VERSION ""

NS_ :

BS_:

BU_: R_BPCU_MCU JiaShiCang L_BPCU_MCU EMPC_ECU

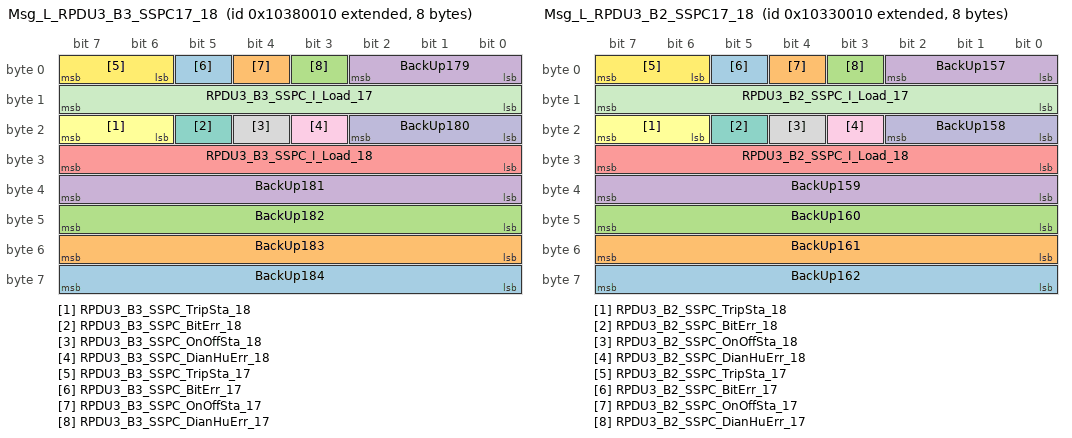
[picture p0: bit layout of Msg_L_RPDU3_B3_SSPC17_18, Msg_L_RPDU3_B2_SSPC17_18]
BO_ 2419589136 Msg_L_RPDU3_B3_SSPC17_18: 8 L_BPCU_MCU
 SG_ BackUp184 : 56|8@1+ (1,0) [0|0] ""  JiaShiCang
 SG_ BackUp183 : 48|8@1+ (1,0) [0|0] ""  JiaShiCang
 SG_ BackUp182 : 40|8@1+ (1,0) [0|0] ""  JiaShiCang
 SG_ BackUp181 : 32|8@1+ (1,0) [0|0] ""  JiaShiCang
 SG_ RPDU3_B3_SSPC_I_Load_18 : 24|8@1+ (0.1,0) [0|25.5] "A"  JiaShiCang
 SG_ RPDU3_B3_SSPC_TripSta_18 : 22|2@1+ (1,0) [0|3] ""  JiaShiCang
 SG_ RPDU3_B3_SSPC_BitErr_18 : 21|1@1+ (1,0) [0|1] ""  JiaShiCang
 SG_ RPDU3_B3_SSPC_OnOffSta_18 : 20|1@1+ (1,0) [0|1] ""  JiaShiCang
 SG_ RPDU3_B3_SSPC_DianHuErr_18 : 19|1@1+ (1,0) [0|1] ""  JiaShiCang
 SG_ BackUp180 : 16|3@1+ (1,0) [0|0] ""  JiaShiCang
 SG_ RPDU3_B3_SSPC_I_Load_17 : 8|8@1+ (0.1,0) [0|25.5] "A"  JiaShiCang
 SG_ RPDU3_B3_SSPC_TripSta_17 : 6|2@1+ (1,0) [0|3] ""  JiaShiCang
 SG_ RPDU3_B3_SSPC_BitErr_17 : 5|1@1+ (1,0) [0|1] ""  JiaShiCang
 SG_ RPDU3_B3_SSPC_OnOffSta_17 : 4|1@1+ (1,0) [0|1] ""  JiaShiCang
 SG_ RPDU3_B3_SSPC_DianHuErr_17 : 3|1@1+ (1,0) [0|1] ""  JiaShiCang
 SG_ BackUp179 : 0|3@1+ (1,0) [0|0] ""  JiaShiCang

BO_ 2419523600 Msg_L_RPDU3_B3_SSPC13_16: 8 L_BPCU_MCU
 SG_ RPDU3_B3_SSPC_I_Load_16 : 56|8@1+ (0.1,0) [0|25.5] "A"  JiaShiCang
 SG_ RPDU3_B3_SSPC_TripSta_16 : 54|2@1+ (1,0) [0|3] ""  JiaShiCang
 SG_ RPDU3_B3_SSPC_BitErr_16 : 53|1@1+ (1,0) [0|1] ""  JiaShiCang
 SG_ RPDU3_B3_SSPC_OnOffSta_16 : 52|1@1+ (1,0) [0|1] ""  JiaShiCang
 SG_ RPDU3_B3_SSPC_DianHuErr_16 : 51|1@1+ (1,0) [0|1] ""  JiaShiCang
 SG_ BackUp178 : 48|3@1+ (1,0) [0|0] ""  JiaShiCang
 SG_ RPDU3_B3_SSPC_I_Load_15 : 40|8@1+ (0.1,0) [0|25.5] "A"  JiaShiCang
 SG_ RPDU3_B3_SSPC_TripSta_15 : 38|2@1+ (1,0) [0|3] ""  JiaShiCang
 SG_ RPDU3_B3_SSPC_BitErr_15 : 37|1@1+ (1,0) [0|1] ""  JiaShiCang
 SG_ RPDU3_B3_SSPC_OnOffSta_15 : 36|1@1+ (1,0) [0|1] ""  JiaShiCang
 SG_ RPDU3_B3_SSPC_DianHuErr_15 : 35|1@1+ (1,0) [0|1] ""  JiaShiCang
 SG_ BackUp177 : 32|3@1+ (1,0) [0|0] ""  JiaShiCang
 SG_ RPDU3_B3_SSPC_I_Load_14 : 24|8@1+ (0.1,0) [0|25.5] "A"  JiaShiCang
 SG_ RPDU3_B3_SSPC_TripSta_14 : 22|2@1+ (1,0) [0|3] ""  JiaShiCang
 SG_ RPDU3_B3_SSPC_BitErr_14 : 21|1@1+ (1,0) [0|1] ""  JiaShiCang
 SG_ RPDU3_B3_SSPC_OnOffSta_14 : 20|1@1+ (1,0) [0|1] ""  JiaShiCang
 SG_ RPDU3_B3_SSPC_DianHuErr_14 : 19|1@1+ (1,0) [0|1] ""  JiaShiCang
 SG_ BackUp176 : 16|3@1+ (1,0) [0|0] ""  JiaShiCang
 SG_ RPDU3_B3_SSPC_I_Load_13 : 8|8@1+ (0.1,0) [0|25.5] "A"  JiaShiCang
 SG_ RPDU3_B3_SSPC_TripSta_13 : 6|2@1+ (1,0) [0|3] ""  JiaShiCang
 SG_ RPDU3_B3_SSPC_BitErr_13 : 5|1@1+ (1,0) [0|1] ""  JiaShiCang
 SG_ RPDU3_B3_SSPC_OnOffSta_13 : 4|1@1+ (1,0) [0|1] ""  JiaShiCang
 SG_ RPDU3_B3_SSPC_DianHuErr_13 : 3|1@1+ (1,0) [0|1] ""  JiaShiCang
 SG_ BackUp175 : 0|3@1+ (1,0) [0|0] ""  JiaShiCang

BO_ 2419458064 Msg_L_RPDU3_B3_SSPC09_12: 8 L_BPCU_MCU
 SG_ RPDU3_B3_SSPC_I_Load_12 : 56|8@1+ (0.1,0) [0|25.5] "A"  JiaShiCang
 SG_ RPDU3_B3_SSPC_TripSta_12 : 54|2@1+ (1,0) [0|3] ""  JiaShiCang
 SG_ RPDU3_B3_SSPC_BitErr_12 : 53|1@1+ (1,0) [0|1] ""  JiaShiCang
 SG_ RPDU3_B3_SSPC_OnOffSta_12 : 52|1@1+ (1,0) [0|1] ""  JiaShiCang
 SG_ RPDU3_B3_SSPC_DianHuErr_12 : 51|1@1+ (1,0) [0|1] ""  JiaShiCang
 SG_ BackUp174 : 48|3@1+ (1,0) [0|0] ""  JiaShiCang
 SG_ RPDU3_B3_SSPC_I_Load_11 : 40|8@1+ (0.1,0) [0|25.5] "A"  JiaShiCang
 SG_ RPDU3_B3_SSPC_TripSta_11 : 38|2@1+ (1,0) [0|3] ""  JiaShiCang
 SG_ RPDU3_B3_SSPC_BitErr_11 : 37|1@1+ (1,0) [0|1] ""  JiaShiCang
 SG_ RPDU3_B3_SSPC_OnOffSta_11 : 36|1@1+ (1,0) [0|1] ""  JiaShiCang
 SG_ RPDU3_B3_SSPC_DianHuErr_11 : 35|1@1+ (1,0) [0|1] ""  JiaShiCang
 SG_ BackUp173 : 32|3@1+ (1,0) [0|0] ""  JiaShiCang
 SG_ RPDU3_B3_SSPC_I_Load_10 : 24|8@1+ (0.1,0) [0|25.5] "A"  JiaShiCang
 SG_ RPDU3_B3_SSPC_TripSta_10 : 22|2@1+ (1,0) [0|3] ""  JiaShiCang
 SG_ RPDU3_B3_SSPC_BitErr_10 : 21|1@1+ (1,0) [0|1] ""  JiaShiCang
 SG_ RPDU3_B3_SSPC_OnOffSta_10 : 20|1@1+ (1,0) [0|1] ""  JiaShiCang
 SG_ RPDU3_B3_SSPC_DianHuErr_10 : 19|1@1+ (1,0) [0|1] ""  JiaShiCang
 SG_ BackUp172 : 16|3@1+ (1,0) [0|0] ""  JiaShiCang
 SG_ RPDU3_B3_SSPC_I_Load_09 : 8|8@1+ (0.1,0) [0|25.5] "A"  JiaShiCang
 SG_ RPDU3_B3_SSPC_TripSta_09 : 6|2@1+ (1,0) [0|3] ""  JiaShiCang
 SG_ RPDU3_B3_SSPC_BitErr_09 : 5|1@1+ (1,0) [0|1] ""  JiaShiCang
 SG_ RPDU3_B3_SSPC_OnOffSta_09 : 4|1@1+ (1,0) [0|1] ""  JiaShiCang
 SG_ RPDU3_B3_SSPC_DianHuErr_09 : 3|1@1+ (1,0) [0|1] ""  JiaShiCang
 SG_ BackUp171 : 0|3@1+ (1,0) [0|0] ""  JiaShiCang

BO_ 2419392528 Msg_L_RPDU3_B3_SSPC05_08: 8 L_BPCU_MCU
 SG_ RPDU3_B3_SSPC_I_Load_08 : 56|8@1+ (0.1,0) [0|25.5] "A"  JiaShiCang
 SG_ RPDU3_B3_SSPC_TripSta_08 : 54|2@1+ (1,0) [0|3] ""  JiaShiCang
 SG_ RPDU3_B3_SSPC_BitErr_08 : 53|1@1+ (1,0) [0|1] ""  JiaShiCang
 SG_ RPDU3_B3_SSPC_OnOffSta_08 : 52|1@1+ (1,0) [0|1] ""  JiaShiCang
 SG_ RPDU3_B3_SSPC_DianHuErr_08 : 51|1@1+ (1,0) [0|1] ""  JiaShiCang
 SG_ BackUp170 : 48|3@1+ (1,0) [0|0] ""  JiaShiCang
 SG_ RPDU3_B3_SSPC_I_Load_07 : 40|8@1+ (0.1,0) [0|25.5] "A"  JiaShiCang
 SG_ RPDU3_B3_SSPC_TripSta_07 : 38|2@1+ (1,0) [0|3] ""  JiaShiCang
 SG_ RPDU3_B3_SSPC_BitErr_07 : 37|1@1+ (1,0) [0|1] ""  JiaShiCang
 SG_ RPDU3_B3_SSPC_OnOffSta_07 : 36|1@1+ (1,0) [0|1] ""  JiaShiCang
 SG_ RPDU3_B3_SSPC_DianHuErr_07 : 35|1@1+ (1,0) [0|1] ""  JiaShiCang
 SG_ BackUp169 : 32|3@1+ (1,0) [0|0] ""  JiaShiCang
 SG_ RPDU3_B3_SSPC_I_Load_06 : 24|8@1+ (0.1,0) [0|25.5] "A"  JiaShiCang
 SG_ RPDU3_B3_SSPC_TripSta_06 : 22|2@1+ (1,0) [0|3] ""  JiaShiCang
 SG_ RPDU3_B3_SSPC_BitErr_06 : 21|1@1+ (1,0) [0|1] ""  JiaShiCang
 SG_ RPDU3_B3_SSPC_OnOffSta_06 : 20|1@1+ (1,0) [0|1] ""  JiaShiCang
 SG_ RPDU3_B3_SSPC_DianHuErr_06 : 19|1@1+ (1,0) [0|1] ""  JiaShiCang
 SG_ BackUp168 : 16|3@1+ (1,0) [0|0] ""  JiaShiCang
 SG_ RPDU3_B3_SSPC_I_Load_05 : 8|8@1+ (0.1,0) [0|25.5] "A"  JiaShiCang
 SG_ RPDU3_B3_SSPC_TripSta_05 : 6|2@1+ (1,0) [0|3] ""  JiaShiCang
 SG_ RPDU3_B3_SSPC_BitErr_05 : 5|1@1+ (1,0) [0|1] ""  JiaShiCang
 SG_ RPDU3_B3_SSPC_OnOffSta_05 : 4|1@1+ (1,0) [0|1] ""  JiaShiCang
 SG_ RPDU3_B3_SSPC_DianHuErr_05 : 3|1@1+ (1,0) [0|1] ""  JiaShiCang
 SG_ BackUp167 : 0|3@1+ (1,0) [0|0] ""  JiaShiCang

BO_ 2419326992 Msg_L_RPDU3_B3_SSPC01_04: 8 L_BPCU_MCU
 SG_ RPDU3_B3_SSPC_I_Load_04 : 56|8@1+ (0.1,0) [0|25.5] "A"  JiaShiCang
 SG_ RPDU3_B3_SSPC_TripSta_04 : 54|2@1+ (1,0) [0|3] ""  JiaShiCang
 SG_ RPDU3_B3_SSPC_BitErr_04 : 53|1@1+ (1,0) [0|1] ""  JiaShiCang
 SG_ RPDU3_B3_SSPC_OnOffSta_04 : 52|1@1+ (1,0) [0|1] ""  JiaShiCang
 SG_ RPDU3_B3_SSPC_DianHuErr_04 : 51|1@1+ (1,0) [0|1] ""  JiaShiCang
 SG_ BackUp166 : 48|3@1+ (1,0) [0|0] ""  JiaShiCang
 SG_ RPDU3_B3_SSPC_I_Load_03 : 40|8@1+ (0.1,0) [0|25.5] "A"  JiaShiCang
 SG_ RPDU3_B3_SSPC_TripSta_03 : 38|2@1+ (1,0) [0|3] ""  JiaShiCang
 SG_ RPDU3_B3_SSPC_BitErr_03 : 37|1@1+ (1,0) [0|1] ""  JiaShiCang
 SG_ RPDU3_B3_SSPC_OnOffSta_03 : 36|1@1+ (1,0) [0|1] ""  JiaShiCang
 SG_ RPDU3_B3_SSPC_DianHuErr_03 : 35|1@1+ (1,0) [0|1] ""  JiaShiCang
 SG_ BackUp165 : 32|3@1+ (1,0) [0|0] ""  JiaShiCang
 SG_ RPDU3_B3_SSPC_I_Load_02 : 24|8@1+ (0.1,0) [0|25.5] "A"  JiaShiCang
 SG_ RPDU3_B3_SSPC_TripSta_02 : 22|2@1+ (1,0) [0|3] ""  JiaShiCang
 SG_ RPDU3_B3_SSPC_BitErr_02 : 21|1@1+ (1,0) [0|1] ""  JiaShiCang
 SG_ RPDU3_B3_SSPC_OnOffSta_02 : 20|1@1+ (1,0) [0|1] ""  JiaShiCang
 SG_ RPDU3_B3_SSPC_DianHuErr_02 : 19|1@1+ (1,0) [0|1] ""  JiaShiCang
 SG_ BackUp164 : 16|3@1+ (1,0) [0|0] ""  JiaShiCang
 SG_ RPDU3_B3_SSPC_I_Load_01 : 8|8@1+ (0.1,0) [0|25.5] "A"  JiaShiCang
 SG_ RPDU3_B3_SSPC_TripSta_01 : 6|2@1+ (1,0) [0|3] ""  JiaShiCang
 SG_ RPDU3_B3_SSPC_BitErr_01 : 5|1@1+ (1,0) [0|1] ""  JiaShiCang
 SG_ RPDU3_B3_SSPC_OnOffSta_01 : 4|1@1+ (1,0) [0|1] ""  JiaShiCang
 SG_ RPDU3_B3_SSPC_DianHuErr_01 : 3|1@1+ (1,0) [0|1] ""  JiaShiCang
 SG_ BackUp163 : 0|3@1+ (1,0) [0|0] ""  JiaShiCang

BO_ 2419261456 Msg_L_RPDU3_B2_SSPC17_18: 8 L_BPCU_MCU
 SG_ BackUp162 : 56|8@1+ (1,0) [0|0] ""  JiaShiCang
 SG_ BackUp161 : 48|8@1+ (1,0) [0|0] ""  JiaShiCang
 SG_ BackUp160 : 40|8@1+ (1,0) [0|0] ""  JiaShiCang
 SG_ BackUp159 : 32|8@1+ (1,0) [0|0] ""  JiaShiCang
 SG_ RPDU3_B2_SSPC_I_Load_18 : 24|8@1+ (0.1,0) [0|25.5] "A"  JiaShiCang
 SG_ RPDU3_B2_SSPC_TripSta_18 : 22|2@1+ (1,0) [0|3] ""  JiaShiCang
 SG_ RPDU3_B2_SSPC_BitErr_18 : 21|1@1+ (1,0) [0|1] ""  JiaShiCang
 SG_ RPDU3_B2_SSPC_OnOffSta_18 : 20|1@1+ (1,0) [0|1] ""  JiaShiCang
 SG_ RPDU3_B2_SSPC_DianHuErr_18 : 19|1@1+ (1,0) [0|1] ""  JiaShiCang
 SG_ BackUp158 : 16|3@1+ (1,0) [0|0] ""  JiaShiCang
 SG_ RPDU3_B2_SSPC_I_Load_17 : 8|8@1+ (0.1,0) [0|25.5] "A"  JiaShiCang
 SG_ RPDU3_B2_SSPC_TripSta_17 : 6|2@1+ (1,0) [0|3] ""  JiaShiCang
 SG_ RPDU3_B2_SSPC_BitErr_17 : 5|1@1+ (1,0) [0|1] ""  JiaShiCang
 SG_ RPDU3_B2_SSPC_OnOffSta_17 : 4|1@1+ (1,0) [0|1] ""  JiaShiCang
 SG_ RPDU3_B2_SSPC_DianHuErr_17 : 3|1@1+ (1,0) [0|1] ""  JiaShiCang
 SG_ BackUp157 : 0|3@1+ (1,0) [0|0] ""  JiaShiCang

BO_ 2419195920 Msg_L_RPDU3_B2_SSPC13_16: 8 L_BPCU_MCU
 SG_ RPDU3_B2_SSPC_I_Load_16 : 56|8@1+ (0.1,0) [0|25.5] "A"  JiaShiCang
 SG_ RPDU3_B2_SSPC_TripSta_16 : 54|2@1+ (1,0) [0|3] ""  JiaShiCang
 SG_ RPDU3_B2_SSPC_BitErr_16 : 53|1@1+ (1,0) [0|1] ""  JiaShiCang
 SG_ RPDU3_B2_SSPC_OnOffSta_16 : 52|1@1+ (1,0) [0|1] ""  JiaShiCang
 SG_ RPDU3_B2_SSPC_DianHuErr_16 : 51|1@1+ (1,0) [0|1] ""  JiaShiCang
 SG_ BackUp156 : 48|3@1+ (1,0) [0|0] ""  JiaShiCang
 SG_ RPDU3_B2_SSPC_I_Load_15 : 40|8@1+ (0.1,0) [0|25.5] "A"  JiaShiCang
 SG_ RPDU3_B2_SSPC_TripSta_15 : 38|2@1+ (1,0) [0|3] ""  JiaShiCang
 SG_ RPDU3_B2_SSPC_BitErr_15 : 37|1@1+ (1,0) [0|1] ""  JiaShiCang
 SG_ RPDU3_B2_SSPC_OnOffSta_15 : 36|1@1+ (1,0) [0|1] ""  JiaShiCang
 SG_ RPDU3_B2_SSPC_DianHuErr_15 : 35|1@1+ (1,0) [0|1] ""  JiaShiCang
 SG_ BackUp155 : 32|3@1+ (1,0) [0|0] ""  JiaShiCang
 SG_ RPDU3_B2_SSPC_I_Load_14 : 24|8@1+ (0.1,0) [0|25.5] "A"  JiaShiCang
 SG_ RPDU3_B2_SSPC_TripSta_14 : 22|2@1+ (1,0) [0|3] ""  JiaShiCang
 SG_ RPDU3_B2_SSPC_BitErr_14 : 21|1@1+ (1,0) [0|1] ""  JiaShiCang
 SG_ RPDU3_B2_SSPC_OnOffSta_14 : 20|1@1+ (1,0) [0|1] ""  JiaShiCang
 SG_ RPDU3_B2_SSPC_DianHuErr_14 : 19|1@1+ (1,0) [0|1] ""  JiaShiCang
 SG_ BackUp154 : 16|3@1+ (1,0) [0|0] ""  JiaShiCang
 SG_ RPDU3_B2_SSPC_I_Load_13 : 8|8@1+ (0.1,0) [0|25.5] "A"  JiaShiCang
 SG_ RPDU3_B2_SSPC_TripSta_13 : 6|2@1+ (1,0) [0|3] ""  JiaShiCang
 SG_ RPDU3_B2_SSPC_BitErr_13 : 5|1@1+ (1,0) [0|1] ""  JiaShiCang
 SG_ RPDU3_B2_SSPC_OnOffSta_13 : 4|1@1+ (1,0) [0|1] ""  JiaShiCang
 SG_ RPDU3_B2_SSPC_DianHuErr_13 : 3|1@1+ (1,0) [0|1] ""  JiaShiCang
 SG_ BackUp153 : 0|3@1+ (1,0) [0|0] ""  JiaShiCang

BO_ 2419130384 Msg_L_RPDU3_B2_SSPC09_12: 8 L_BPCU_MCU
 SG_ RPDU3_B2_SSPC_I_Load_12 : 56|8@1+ (0.1,0) [0|25.5] "A"  JiaShiCang
 SG_ RPDU3_B2_SSPC_TripSta_12 : 54|2@1+ (1,0) [0|3] ""  JiaShiCang
 SG_ RPDU3_B2_SSPC_BitErr_12 : 53|1@1+ (1,0) [0|1] ""  JiaShiCang
 SG_ RPDU3_B2_SSPC_OnOffSta_12 : 52|1@1+ (1,0) [0|1] ""  JiaShiCang
 SG_ RPDU3_B2_SSPC_DianHuErr_12 : 51|1@1+ (1,0) [0|1] ""  JiaShiCang
 SG_ BackUp152 : 48|3@1+ (1,0) [0|0] ""  JiaShiCang
 SG_ RPDU3_B2_SSPC_I_Load_11 : 40|8@1+ (0.1,0) [0|25.5] "A"  JiaShiCang
 SG_ RPDU3_B2_SSPC_TripSta_11 : 38|2@1+ (1,0) [0|3] ""  JiaShiCang
 SG_ RPDU3_B2_SSPC_BitErr_11 : 37|1@1+ (1,0) [0|1] ""  JiaShiCang
 SG_ RPDU3_B2_SSPC_OnOffSta_11 : 36|1@1+ (1,0) [0|1] ""  JiaShiCang
 SG_ RPDU3_B2_SSPC_DianHuErr_11 : 35|1@1+ (1,0) [0|1] ""  JiaShiCang
 SG_ BackUp151 : 32|3@1+ (1,0) [0|0] ""  JiaShiCang
 SG_ RPDU3_B2_SSPC_I_Load_10 : 24|8@1+ (0.1,0) [0|25.5] "A"  JiaShiCang
 SG_ RPDU3_B2_SSPC_TripSta_10 : 22|2@1+ (1,0) [0|3] ""  JiaShiCang
 SG_ RPDU3_B2_SSPC_BitErr_10 : 21|1@1+ (1,0) [0|1] ""  JiaShiCang
 SG_ RPDU3_B2_SSPC_OnOffSta_10 : 20|1@1+ (1,0) [0|1] ""  JiaShiCang
 SG_ RPDU3_B2_SSPC_DianHuErr_10 : 19|1@1+ (1,0) [0|1] ""  JiaShiCang
 SG_ BackUp150 : 16|3@1+ (1,0) [0|0] ""  JiaShiCang
 SG_ RPDU3_B2_SSPC_I_Load_09 : 8|8@1+ (0.1,0) [0|25.5] "A"  JiaShiCang
 SG_ RPDU3_B2_SSPC_TripSta_09 : 6|2@1+ (1,0) [0|3] ""  JiaShiCang
 SG_ RPDU3_B2_SSPC_BitErr_09 : 5|1@1+ (1,0) [0|1] ""  JiaShiCang
 SG_ RPDU3_B2_SSPC_OnOffSta_09 : 4|1@1+ (1,0) [0|1] ""  JiaShiCang
 SG_ RPDU3_B2_SSPC_DianHuErr_09 : 3|1@1+ (1,0) [0|1] ""  JiaShiCang
 SG_ BackUp149 : 0|3@1+ (1,0) [0|0] ""  JiaShiCang

BO_ 2419064848 Msg_L_RPDU3_B2_SSPC05_08: 8 L_BPCU_MCU
 SG_ RPDU3_B2_SSPC_I_Load_08 : 56|8@1+ (0.1,0) [0|25.5] "A"  JiaShiCang
 SG_ RPDU3_B2_SSPC_TripSta_08 : 54|2@1+ (1,0) [0|3] ""  JiaShiCang
 SG_ RPDU3_B2_SSPC_BitErr_08 : 53|1@1+ (1,0) [0|1] ""  JiaShiCang
 SG_ RPDU3_B2_SSPC_OnOffSta_08 : 52|1@1+ (1,0) [0|1] ""  JiaShiCang
 SG_ RPDU3_B2_SSPC_DianHuErr_08 : 51|1@1+ (1,0) [0|1] ""  JiaShiCang
 SG_ BackUp148 : 48|3@1+ (1,0) [0|0] ""  JiaShiCang
 SG_ RPDU3_B2_SSPC_I_Load_07 : 40|8@1+ (0.1,0) [0|25.5] "A"  JiaShiCang
 SG_ RPDU3_B2_SSPC_TripSta_07 : 38|2@1+ (1,0) [0|3] ""  JiaShiCang
 SG_ RPDU3_B2_SSPC_BitErr_07 : 37|1@1+ (1,0) [0|1] ""  JiaShiCang
 SG_ RPDU3_B2_SSPC_OnOffSta_07 : 36|1@1+ (1,0) [0|1] ""  JiaShiCang
 SG_ RPDU3_B2_SSPC_DianHuErr_07 : 35|1@1+ (1,0) [0|1] ""  JiaShiCang
 SG_ BackUp147 : 32|3@1+ (1,0) [0|0] ""  JiaShiCang
 SG_ RPDU3_B2_SSPC_I_Load_06 : 24|8@1+ (0.1,0) [0|25.5] "A"  JiaShiCang
 SG_ RPDU3_B2_SSPC_TripSta_06 : 22|2@1+ (1,0) [0|3] ""  JiaShiCang
 SG_ RPDU3_B2_SSPC_BitErr_06 : 21|1@1+ (1,0) [0|1] ""  JiaShiCang
 SG_ RPDU3_B2_SSPC_OnOffSta_06 : 20|1@1+ (1,0) [0|1] ""  JiaShiCang
 SG_ RPDU3_B2_SSPC_DianHuErr_06 : 19|1@1+ (1,0) [0|1] ""  JiaShiCang
 SG_ BackUp146 : 16|3@1+ (1,0) [0|0] ""  JiaShiCang
 SG_ RPDU3_B2_SSPC_I_Load_05 : 8|8@1+ (0.1,0) [0|25.5] "A"  JiaShiCang
 SG_ RPDU3_B2_SSPC_TripSta_05 : 6|2@1+ (1,0) [0|3] ""  JiaShiCang
 SG_ RPDU3_B2_SSPC_BitErr_05 : 5|1@1+ (1,0) [0|1] ""  JiaShiCang
 SG_ RPDU3_B2_SSPC_OnOffSta_05 : 4|1@1+ (1,0) [0|1] ""  JiaShiCang
 SG_ RPDU3_B2_SSPC_DianHuErr_05 : 3|1@1+ (1,0) [0|1] ""  JiaShiCang
 SG_ BackUp145 : 0|3@1+ (1,0) [0|0] ""  JiaShiCang

BO_ 2418999312 Msg_L_RPDU3_B2_SSPC01_04: 8 L_BPCU_MCU
 SG_ RPDU3_B2_SSPC_I_Load_04 : 56|8@1+ (0.1,0) [0|25.5] "A"  JiaShiCang
 SG_ RPDU3_B2_SSPC_TripSta_04 : 54|2@1+ (1,0) [0|3] ""  JiaShiCang
 SG_ RPDU3_B2_SSPC_BitErr_04 : 53|1@1+ (1,0) [0|1] ""  JiaShiCang
 SG_ RPDU3_B2_SSPC_OnOffSta_04 : 52|1@1+ (1,0) [0|1] ""  JiaShiCang
 SG_ RPDU3_B2_SSPC_DianHuErr_04 : 51|1@1+ (1,0) [0|1] ""  JiaShiCang
 SG_ BackUp144 : 48|3@1+ (1,0) [0|0] ""  JiaShiCang
 SG_ RPDU3_B2_SSPC_I_Load_03 : 40|8@1+ (0.1,0) [0|25.5] "A"  JiaShiCang
 SG_ RPDU3_B2_SSPC_TripSta_03 : 38|2@1+ (1,0) [0|3] ""  JiaShiCang
 SG_ RPDU3_B2_SSPC_BitErr_03 : 37|1@1+ (1,0) [0|1] ""  JiaShiCang
 SG_ RPDU3_B2_SSPC_OnOffSta_03 : 36|1@1+ (1,0) [0|1] ""  JiaShiCang
 SG_ RPDU3_B2_SSPC_DianHuErr_03 : 35|1@1+ (1,0) [0|1] ""  JiaShiCang
 SG_ BackUp143 : 32|3@1+ (1,0) [0|0] ""  JiaShiCang
 SG_ RPDU3_B2_SSPC_I_Load_02 : 24|8@1+ (0.1,0) [0|25.5] "A"  JiaShiCang
 SG_ RPDU3_B2_SSPC_TripSta_02 : 22|2@1+ (1,0) [0|3] ""  JiaShiCang
 SG_ RPDU3_B2_SSPC_BitErr_02 : 21|1@1+ (1,0) [0|1] ""  JiaShiCang
 SG_ RPDU3_B2_SSPC_OnOffSta_02 : 20|1@1+ (1,0) [0|1] ""  JiaShiCang
 SG_ RPDU3_B2_SSPC_DianHuErr_02 : 19|1@1+ (1,0) [0|1] ""  JiaShiCang
 SG_ BackUp142 : 16|3@1+ (1,0) [0|0] ""  JiaShiCang
 SG_ RPDU3_B2_SSPC_I_Load_01 : 8|8@1+ (0.1,0) [0|25.5] "A"  JiaShiCang
 SG_ RPDU3_B2_SSPC_TripSta_01 : 6|2@1+ (1,0) [0|3] ""  JiaShiCang
 SG_ RPDU3_B2_SSPC_BitErr_01 : 5|1@1+ (1,0) [0|1] ""  JiaShiCang
 SG_ RPDU3_B2_SSPC_OnOffSta_01 : 4|1@1+ (1,0) [0|1] ""  JiaShiCang
 SG_ RPDU3_B2_SSPC_DianHuErr_01 : 3|1@1+ (1,0) [0|1] ""  JiaShiCang
 SG_ BackUp141 : 0|3@1+ (1,0) [0|0] ""  JiaShiCang

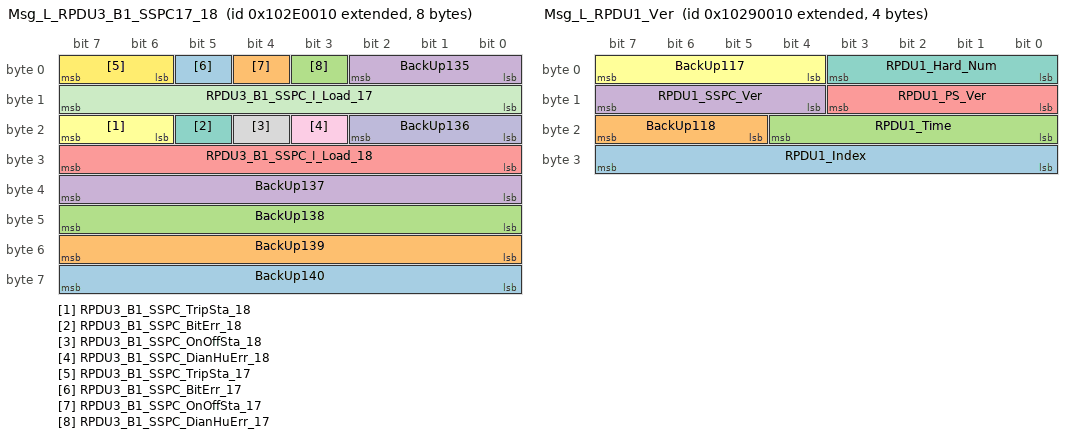
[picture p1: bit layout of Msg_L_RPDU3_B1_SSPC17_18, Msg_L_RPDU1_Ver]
BO_ 2418933776 Msg_L_RPDU3_B1_SSPC17_18: 8 L_BPCU_MCU
 SG_ BackUp140 : 56|8@1+ (1,0) [0|0] ""  JiaShiCang
 SG_ BackUp139 : 48|8@1+ (1,0) [0|0] ""  JiaShiCang
 SG_ BackUp138 : 40|8@1+ (1,0) [0|0] ""  JiaShiCang
 SG_ BackUp137 : 32|8@1+ (1,0) [0|0] ""  JiaShiCang
 SG_ RPDU3_B1_SSPC_I_Load_18 : 24|8@1+ (0.1,0) [0|25.5] "A"  JiaShiCang
 SG_ RPDU3_B1_SSPC_TripSta_18 : 22|2@1+ (1,0) [0|3] ""  JiaShiCang
 SG_ RPDU3_B1_SSPC_BitErr_18 : 21|1@1+ (1,0) [0|1] ""  JiaShiCang
 SG_ RPDU3_B1_SSPC_OnOffSta_18 : 20|1@1+ (1,0) [0|1] ""  JiaShiCang
 SG_ RPDU3_B1_SSPC_DianHuErr_18 : 19|1@1+ (1,0) [0|1] ""  JiaShiCang
 SG_ BackUp136 : 16|3@1+ (1,0) [0|0] ""  JiaShiCang
 SG_ RPDU3_B1_SSPC_I_Load_17 : 8|8@1+ (0.1,0) [0|25.5] "A"  JiaShiCang
 SG_ RPDU3_B1_SSPC_TripSta_17 : 6|2@1+ (1,0) [0|3] ""  JiaShiCang
 SG_ RPDU3_B1_SSPC_BitErr_17 : 5|1@1+ (1,0) [0|1] ""  JiaShiCang
 SG_ RPDU3_B1_SSPC_OnOffSta_17 : 4|1@1+ (1,0) [0|1] ""  JiaShiCang
 SG_ RPDU3_B1_SSPC_DianHuErr_17 : 3|1@1+ (1,0) [0|1] ""  JiaShiCang
 SG_ BackUp135 : 0|3@1+ (1,0) [0|0] ""  JiaShiCang

BO_ 2418868240 Msg_L_RPDU3_B1_SSPC13_16: 8 L_BPCU_MCU
 SG_ RPDU3_B1_SSPC_I_Load_16 : 56|8@1+ (0.1,0) [0|25.5] "A"  JiaShiCang
 SG_ RPDU3_B1_SSPC_TripSta_16 : 54|2@1+ (1,0) [0|3] ""  JiaShiCang
 SG_ RPDU3_B1_SSPC_BitErr_16 : 53|1@1+ (1,0) [0|1] ""  JiaShiCang
 SG_ RPDU3_B1_SSPC_OnOffSta_16 : 52|1@1+ (1,0) [0|1] ""  JiaShiCang
 SG_ RPDU3_B1_SSPC_DianHuErr_16 : 51|1@1+ (1,0) [0|1] ""  JiaShiCang
 SG_ BackUp134 : 48|3@1+ (1,0) [0|0] ""  JiaShiCang
 SG_ RPDU3_B1_SSPC_I_Load_15 : 40|8@1+ (0.1,0) [0|25.5] "A"  JiaShiCang
 SG_ RPDU3_B1_SSPC_TripSta_15 : 38|2@1+ (1,0) [0|3] ""  JiaShiCang
 SG_ RPDU3_B1_SSPC_BitErr_15 : 37|1@1+ (1,0) [0|1] ""  JiaShiCang
 SG_ RPDU3_B1_SSPC_OnOffSta_15 : 36|1@1+ (1,0) [0|1] ""  JiaShiCang
 SG_ RPDU3_B1_SSPC_DianHuErr_15 : 35|1@1+ (1,0) [0|1] ""  JiaShiCang
 SG_ BackUp133 : 32|3@1+ (1,0) [0|0] ""  JiaShiCang
 SG_ RPDU3_B1_SSPC_I_Load_14 : 24|8@1+ (0.1,0) [0|25.5] "A"  JiaShiCang
 SG_ RPDU3_B1_SSPC_TripSta_14 : 22|2@1+ (1,0) [0|3] ""  JiaShiCang
 SG_ RPDU3_B1_SSPC_BitErr_14 : 21|1@1+ (1,0) [0|1] ""  JiaShiCang
 SG_ RPDU3_B1_SSPC_OnOffSta_14 : 20|1@1+ (1,0) [0|1] ""  JiaShiCang
 SG_ RPDU3_B1_SSPC_DianHuErr_14 : 19|1@1+ (1,0) [0|1] ""  JiaShiCang
 SG_ BackUp132 : 16|3@1+ (1,0) [0|0] ""  JiaShiCang
 SG_ RPDU3_B1_SSPC_I_Load_13 : 8|8@1+ (0.1,0) [0|25.5] "A"  JiaShiCang
 SG_ RPDU3_B1_SSPC_TripSta_13 : 6|2@1+ (1,0) [0|3] ""  JiaShiCang
 SG_ RPDU3_B1_SSPC_BitErr_13 : 5|1@1+ (1,0) [0|1] ""  JiaShiCang
 SG_ RPDU3_B1_SSPC_OnOffSta_13 : 4|1@1+ (1,0) [0|1] ""  JiaShiCang
 SG_ RPDU3_B1_SSPC_DianHuErr_13 : 3|1@1+ (1,0) [0|1] ""  JiaShiCang
 SG_ BackUp131 : 0|3@1+ (1,0) [0|0] ""  JiaShiCang

BO_ 2418802704 Msg_L_RPDU3_B1_SSPC09_12: 8 L_BPCU_MCU
 SG_ RPDU3_B1_SSPC_I_Load_12 : 56|8@1+ (0.1,0) [0|25.5] "A"  JiaShiCang
 SG_ RPDU3_B1_SSPC_TripSta_12 : 54|2@1+ (1,0) [0|3] ""  JiaShiCang
 SG_ RPDU3_B1_SSPC_BitErr_12 : 53|1@1+ (1,0) [0|1] ""  JiaShiCang
 SG_ RPDU3_B1_SSPC_OnOffSta_12 : 52|1@1+ (1,0) [0|1] ""  JiaShiCang
 SG_ RPDU3_B1_SSPC_DianHuErr_12 : 51|1@1+ (1,0) [0|1] ""  JiaShiCang
 SG_ BackUp130 : 48|3@1+ (1,0) [0|0] ""  JiaShiCang
 SG_ RPDU3_B1_SSPC_I_Load_11 : 40|8@1+ (0.1,0) [0|25.5] "A"  JiaShiCang
 SG_ RPDU3_B1_SSPC_TripSta_11 : 38|2@1+ (1,0) [0|3] ""  JiaShiCang
 SG_ RPDU3_B1_SSPC_BitErr_11 : 37|1@1+ (1,0) [0|1] ""  JiaShiCang
 SG_ RPDU3_B1_SSPC_OnOffSta_11 : 36|1@1+ (1,0) [0|1] ""  JiaShiCang
 SG_ RPDU3_B1_SSPC_DianHuErr_11 : 35|1@1+ (1,0) [0|1] ""  JiaShiCang
 SG_ BackUp129 : 32|3@1+ (1,0) [0|0] ""  JiaShiCang
 SG_ RPDU3_B1_SSPC_I_Load_10 : 24|8@1+ (0.1,0) [0|25.5] "A"  JiaShiCang
 SG_ RPDU3_B1_SSPC_TripSta_10 : 22|2@1+ (1,0) [0|3] ""  JiaShiCang
 SG_ RPDU3_B1_SSPC_BitErr_10 : 21|1@1+ (1,0) [0|1] ""  JiaShiCang
 SG_ RPDU3_B1_SSPC_OnOffSta_10 : 20|1@1+ (1,0) [0|1] ""  JiaShiCang
 SG_ RPDU3_B1_SSPC_DianHuErr_10 : 19|1@1+ (1,0) [0|1] ""  JiaShiCang
 SG_ BackUp128 : 16|3@1+ (1,0) [0|0] ""  JiaShiCang
 SG_ RPDU3_B1_SSPC_I_Load_09 : 8|8@1+ (0.1,0) [0|25.5] "A"  JiaShiCang
 SG_ RPDU3_B1_SSPC_TripSta_09 : 6|2@1+ (1,0) [0|3] ""  JiaShiCang
 SG_ RPDU3_B1_SSPC_BitErr_09 : 5|1@1+ (1,0) [0|1] ""  JiaShiCang
 SG_ RPDU3_B1_SSPC_OnOffSta_09 : 4|1@1+ (1,0) [0|1] ""  JiaShiCang
 SG_ RPDU3_B1_SSPC_DianHuErr_09 : 3|1@1+ (1,0) [0|1] ""  JiaShiCang
 SG_ BackUp127 : 0|3@1+ (1,0) [0|0] ""  JiaShiCang

BO_ 2418737168 Msg_L_RPDU3_B1_SSPC05_08: 8 L_BPCU_MCU
 SG_ RPDU3_B1_SSPC_I_Load_08 : 56|8@1+ (0.1,0) [0|25.5] "A"  JiaShiCang
 SG_ RPDU3_B1_SSPC_TripSta_08 : 54|2@1+ (1,0) [0|3] ""  JiaShiCang
 SG_ RPDU3_B1_SSPC_BitErr_08 : 53|1@1+ (1,0) [0|1] ""  JiaShiCang
 SG_ RPDU3_B1_SSPC_OnOffSta_08 : 52|1@1+ (1,0) [0|1] ""  JiaShiCang
 SG_ RPDU3_B1_SSPC_DianHuErr_08 : 51|1@1+ (1,0) [0|1] ""  JiaShiCang
 SG_ BackUp126 : 48|3@1+ (1,0) [0|0] ""  JiaShiCang
 SG_ RPDU3_B1_SSPC_I_Load_07 : 40|8@1+ (0.1,0) [0|25.5] "A"  JiaShiCang
 SG_ RPDU3_B1_SSPC_TripSta_07 : 38|2@1+ (1,0) [0|3] ""  JiaShiCang
 SG_ RPDU3_B1_SSPC_BitErr_07 : 37|1@1+ (1,0) [0|1] ""  JiaShiCang
 SG_ RPDU3_B1_SSPC_OnOffSta_07 : 36|1@1+ (1,0) [0|1] ""  JiaShiCang
 SG_ RPDU3_B1_SSPC_DianHuErr_07 : 35|1@1+ (1,0) [0|1] ""  JiaShiCang
 SG_ BackUp125 : 32|3@1+ (1,0) [0|0] ""  JiaShiCang
 SG_ RPDU3_B1_SSPC_I_Load_06 : 24|8@1+ (0.1,0) [0|25.5] "A"  JiaShiCang
 SG_ RPDU3_B1_SSPC_TripSta_06 : 22|2@1+ (1,0) [0|3] ""  JiaShiCang
 SG_ RPDU3_B1_SSPC_BitErr_06 : 21|1@1+ (1,0) [0|1] ""  JiaShiCang
 SG_ RPDU3_B1_SSPC_OnOffSta_06 : 20|1@1+ (1,0) [0|1] ""  JiaShiCang
 SG_ RPDU3_B1_SSPC_DianHuErr_06 : 19|1@1+ (1,0) [0|1] ""  JiaShiCang
 SG_ BackUp124 : 16|3@1+ (1,0) [0|0] ""  JiaShiCang
 SG_ RPDU3_B1_SSPC_I_Load_05 : 8|8@1+ (0.1,0) [0|25.5] "A"  JiaShiCang
 SG_ RPDU3_B1_SSPC_TripSta_05 : 6|2@1+ (1,0) [0|3] ""  JiaShiCang
 SG_ RPDU3_B1_SSPC_BitErr_05 : 5|1@1+ (1,0) [0|1] ""  JiaShiCang
 SG_ RPDU3_B1_SSPC_OnOffSta_05 : 4|1@1+ (1,0) [0|1] ""  JiaShiCang
 SG_ RPDU3_B1_SSPC_DianHuErr_05 : 3|1@1+ (1,0) [0|1] ""  JiaShiCang
 SG_ BackUp123 : 0|3@1+ (1,0) [0|0] ""  JiaShiCang

BO_ 2418671632 Msg_L_RPDU3_B1_SSPC01_04: 8 L_BPCU_MCU
 SG_ RPDU3_B1_SSPC_I_Load_04 : 56|8@1+ (0.1,0) [0|25.5] "A"  JiaShiCang
 SG_ RPDU3_B1_SSPC_TripSta_04 : 54|2@1+ (1,0) [0|3] ""  JiaShiCang
 SG_ RPDU3_B1_SSPC_BitErr_04 : 53|1@1+ (1,0) [0|1] ""  JiaShiCang
 SG_ RPDU3_B1_SSPC_OnOffSta_04 : 52|1@1+ (1,0) [0|1] ""  JiaShiCang
 SG_ RPDU3_B1_SSPC_DianHuErr_04 : 51|1@1+ (1,0) [0|1] ""  JiaShiCang
 SG_ BackUp122 : 48|3@1+ (1,0) [0|0] ""  JiaShiCang
 SG_ RPDU3_B1_SSPC_I_Load_03 : 40|8@1+ (0.1,0) [0|25.5] "A"  JiaShiCang
 SG_ RPDU3_B1_SSPC_TripSta_03 : 38|2@1+ (1,0) [0|3] ""  JiaShiCang
 SG_ RPDU3_B1_SSPC_BitErr_03 : 37|1@1+ (1,0) [0|1] ""  JiaShiCang
 SG_ RPDU3_B1_SSPC_OnOffSta_03 : 36|1@1+ (1,0) [0|1] ""  JiaShiCang
 SG_ RPDU3_B1_SSPC_DianHuErr_03 : 35|1@1+ (1,0) [0|1] ""  JiaShiCang
 SG_ BackUp121 : 32|3@1+ (1,0) [0|0] ""  JiaShiCang
 SG_ RPDU3_B1_SSPC_I_Load_02 : 24|8@1+ (0.1,0) [0|25.5] "A"  JiaShiCang
 SG_ RPDU3_B1_SSPC_TripSta_02 : 22|2@1+ (1,0) [0|3] ""  JiaShiCang
 SG_ RPDU3_B1_SSPC_BitErr_02 : 21|1@1+ (1,0) [0|1] ""  JiaShiCang
 SG_ RPDU3_B1_SSPC_OnOffSta_02 : 20|1@1+ (1,0) [0|1] ""  JiaShiCang
 SG_ RPDU3_B1_SSPC_DianHuErr_02 : 19|1@1+ (1,0) [0|1] ""  JiaShiCang
 SG_ BackUp120 : 16|3@1+ (1,0) [0|0] ""  JiaShiCang
 SG_ RPDU3_B1_SSPC_I_Load_01 : 8|8@1+ (0.1,0) [0|25.5] "A"  JiaShiCang
 SG_ RPDU3_B1_SSPC_TripSta_01 : 6|2@1+ (1,0) [0|3] ""  JiaShiCang
 SG_ RPDU3_B1_SSPC_BitErr_01 : 5|1@1+ (1,0) [0|1] ""  JiaShiCang
 SG_ RPDU3_B1_SSPC_OnOffSta_01 : 4|1@1+ (1,0) [0|1] ""  JiaShiCang
 SG_ RPDU3_B1_SSPC_DianHuErr_01 : 3|1@1+ (1,0) [0|1] ""  JiaShiCang
 SG_ BackUp119 : 0|3@1+ (1,0) [0|0] ""  JiaShiCang

BO_ 2418606096 Msg_L_RPDU1_Ver: 4 L_BPCU_MCU
 SG_ RPDU1_Index : 24|8@1+ (1,0) [0|255] ""  JiaShiCang
 SG_ BackUp118 : 21|3@1+ (1,0) [0|0] ""  JiaShiCang
 SG_ RPDU1_Time : 16|5@1+ (1,0) [0|31] ""  JiaShiCang
 SG_ RPDU1_SSPC_Ver : 12|4@1+ (1,0) [0|15] ""  JiaShiCang
 SG_ RPDU1_PS_Ver : 8|4@1+ (1,0) [0|15] ""  JiaShiCang
 SG_ BackUp117 : 4|4@1+ (1,0) [0|0] ""  JiaShiCang
 SG_ RPDU1_Hard_Num : 0|4@1+ (1,0) [0|15] ""  JiaShiCang

BO_ 2418540560 Msg_L_RPDU1_B6_SSPC05_07: 8 L_BPCU_MCU
 SG_ BackUp116 : 56|8@1+ (1,0) [0|0] ""  JiaShiCang
 SG_ BackUp115 : 48|8@1+ (1,0) [0|0] ""  JiaShiCang
 SG_ RPDU1_B6_SSPC_I_Load_07 : 40|8@1+ (0.1,0) [0|25.5] "A"  JiaShiCang
 SG_ RPDU1_B6_SSPC_TripSta_07 : 38|2@1+ (1,0) [0|3] ""  JiaShiCang
 SG_ RPDU1_B6_SSPC_BitErr_07 : 37|1@1+ (1,0) [0|1] ""  JiaShiCang
 SG_ RPDU1_B6_SSPC_OnOffSta_07 : 36|1@1+ (1,0) [0|1] ""  JiaShiCang
 SG_ RPDU1_B6_SSPC_DianHuErr_07 : 35|1@1+ (1,0) [0|1] ""  JiaShiCang
 SG_ BackUp114 : 32|3@1+ (1,0) [0|0] ""  JiaShiCang
 SG_ RPDU1_B6_SSPC_I_Load_06 : 24|8@1+ (0.1,0) [0|25.5] "A"  JiaShiCang
 SG_ RPDU1_B6_SSPC_TripSta_06 : 22|2@1+ (1,0) [0|3] ""  JiaShiCang
 SG_ RPDU1_B6_SSPC_BitErr_06 : 21|1@1+ (1,0) [0|1] ""  JiaShiCang
 SG_ RPDU1_B6_SSPC_OnOffSta_06 : 20|1@1+ (1,0) [0|1] ""  JiaShiCang
 SG_ RPDU1_B6_SSPC_DianHuErr_06 : 19|1@1+ (1,0) [0|1] ""  JiaShiCang
 SG_ BackUp113 : 16|3@1+ (1,0) [0|0] ""  JiaShiCang
 SG_ RPDU1_B6_SSPC_I_Load_05 : 8|8@1+ (0.1,0) [0|25.5] "A"  JiaShiCang
 SG_ RPDU1_B6_SSPC_TripSta_05 : 6|2@1+ (1,0) [0|3] ""  JiaShiCang
 SG_ RPDU1_B6_SSPC_BitErr_05 : 5|1@1+ (1,0) [0|1] ""  JiaShiCang
 SG_ RPDU1_B6_SSPC_OnOffSta_05 : 4|1@1+ (1,0) [0|1] ""  JiaShiCang
 SG_ RPDU1_B6_SSPC_DianHuErr_05 : 3|1@1+ (1,0) [0|1] ""  JiaShiCang
 SG_ BackUp112 : 0|3@1+ (1,0) [0|0] ""  JiaShiCang

BO_ 2418475024 Msg_L_RPDU1_B6_SSPC01_04: 8 L_BPCU_MCU
 SG_ RPDU1_B6_SSPC_I_Load_04 : 56|8@1+ (0.1,0) [0|25.5] "A"  JiaShiCang
 SG_ RPDU1_B6_SSPC_TripSta_04 : 54|2@1+ (1,0) [0|3] ""  JiaShiCang
 SG_ RPDU1_B6_SSPC_BitErr_04 : 53|1@1+ (1,0) [0|1] ""  JiaShiCang
 SG_ RPDU1_B6_SSPC_OnOffSta_04 : 52|1@1+ (1,0) [0|1] ""  JiaShiCang
 SG_ RPDU1_B6_SSPC_DianHuErr_04 : 51|1@1+ (1,0) [0|1] ""  JiaShiCang
 SG_ BackUp111 : 48|3@1+ (1,0) [0|0] ""  JiaShiCang
 SG_ RPDU1_B6_SSPC_I_Load_03 : 40|8@1+ (0.1,0) [0|25.5] "A"  JiaShiCang
 SG_ RPDU1_B6_SSPC_TripSta_03 : 38|2@1+ (1,0) [0|3] ""  JiaShiCang
 SG_ RPDU1_B6_SSPC_BitErr_03 : 37|1@1+ (1,0) [0|1] ""  JiaShiCang
 SG_ RPDU1_B6_SSPC_OnOffSta_03 : 36|1@1+ (1,0) [0|1] ""  JiaShiCang
 SG_ RPDU1_B6_SSPC_DianHuErr_03 : 35|1@1+ (1,0) [0|1] ""  JiaShiCang
 SG_ BackUp110 : 32|3@1+ (1,0) [0|0] ""  JiaShiCang
 SG_ RPDU1_B6_SSPC_I_Load_02 : 24|8@1+ (0.1,0) [0|25.5] "A"  JiaShiCang
 SG_ RPDU1_B6_SSPC_TripSta_02 : 22|2@1+ (1,0) [0|3] ""  JiaShiCang
 SG_ RPDU1_B6_SSPC_BitErr_02 : 21|1@1+ (1,0) [0|1] ""  JiaShiCang
 SG_ RPDU1_B6_SSPC_OnOffSta_02 : 20|1@1+ (1,0) [0|1] ""  JiaShiCang
 SG_ RPDU1_B6_SSPC_DianHuErr_02 : 19|1@1+ (1,0) [0|1] ""  JiaShiCang
 SG_ BackUp109 : 16|3@1+ (1,0) [0|0] ""  JiaShiCang
 SG_ RPDU1_B6_SSPC_I_Load_01 : 8|8@1+ (0.1,0) [0|25.5] "A"  JiaShiCang
 SG_ RPDU1_B6_SSPC_TripSta_01 : 6|2@1+ (1,0) [0|3] ""  JiaShiCang
 SG_ RPDU1_B6_SSPC_BitErr_01 : 5|1@1+ (1,0) [0|1] ""  JiaShiCang
 SG_ RPDU1_B6_SSPC_OnOffSta_01 : 4|1@1+ (1,0) [0|1] ""  JiaShiCang
 SG_ RPDU1_B6_SSPC_DianHuErr_01 : 3|1@1+ (1,0) [0|1] ""  JiaShiCang
 SG_ BackUp108 : 0|3@1+ (1,0) [0|0] ""  JiaShiCang

BO_ 2418409488 Msg_L_RPDU1_B5_SSPC05_07: 8 L_BPCU_MCU
 SG_ BackUp107 : 56|8@1+ (1,0) [0|0] ""  JiaShiCang
 SG_ BackUp106 : 48|8@1+ (1,0) [0|0] ""  JiaShiCang
 SG_ RPDU1_B5_SSPC_I_Load_07 : 40|8@1+ (0.1,0) [0|25.5] "A"  JiaShiCang
 SG_ RPDU1_B5_SSPC_TripSta_07 : 38|2@1+ (1,0) [0|3] ""  JiaShiCang
 SG_ RPDU1_B5_SSPC_BitErr_07 : 37|1@1+ (1,0) [0|1] ""  JiaShiCang
 SG_ RPDU1_B5_SSPC_OnOffSta_07 : 36|1@1+ (1,0) [0|1] ""  JiaShiCang
 SG_ RPDU1_B5_SSPC_DianHuErr_07 : 35|1@1+ (1,0) [0|1] ""  JiaShiCang
 SG_ BackUp105 : 32|3@1+ (1,0) [0|0] ""  JiaShiCang
 SG_ RPDU1_B5_SSPC_I_Load_06 : 24|8@1+ (0.1,0) [0|25.5] "A"  JiaShiCang
 SG_ RPDU1_B5_SSPC_TripSta_06 : 22|2@1+ (1,0) [0|3] ""  JiaShiCang
 SG_ RPDU1_B5_SSPC_BitErr_06 : 21|1@1+ (1,0) [0|1] ""  JiaShiCang
 SG_ RPDU1_B5_SSPC_OnOffSta_06 : 20|1@1+ (1,0) [0|1] ""  JiaShiCang
 SG_ RPDU1_B5_SSPC_DianHuErr_06 : 19|1@1+ (1,0) [0|1] ""  JiaShiCang
 SG_ BackUp104 : 16|3@1+ (1,0) [0|0] ""  JiaShiCang
 SG_ RPDU1_B5_SSPC_I_Load_05 : 8|8@1+ (0.1,0) [0|25.5] "A"  JiaShiCang
 SG_ RPDU1_B5_SSPC_TripSta_05 : 6|2@1+ (1,0) [0|3] ""  JiaShiCang
 SG_ RPDU1_B5_SSPC_BitErr_05 : 5|1@1+ (1,0) [0|1] ""  JiaShiCang
 SG_ RPDU1_B5_SSPC_OnOffSta_05 : 4|1@1+ (1,0) [0|1] ""  JiaShiCang
 SG_ RPDU1_B5_SSPC_DianHuErr_05 : 3|1@1+ (1,0) [0|1] ""  JiaShiCang
 SG_ BackUp103 : 0|3@1+ (1,0) [0|0] ""  JiaShiCang

BO_ 2418343952 Msg_L_RPDU1_B5_SSPC01_04: 8 L_BPCU_MCU
 SG_ RPDU1_B5_SSPC_I_Load_04 : 56|8@1+ (0.1,0) [0|25.5] "A"  JiaShiCang
 SG_ RPDU1_B5_SSPC_TripSta_04 : 54|2@1+ (1,0) [0|3] ""  JiaShiCang
 SG_ RPDU1_B5_SSPC_BitErr_04 : 53|1@1+ (1,0) [0|1] ""  JiaShiCang
 SG_ RPDU1_B5_SSPC_OnOffSta_04 : 52|1@1+ (1,0) [0|1] ""  JiaShiCang
 SG_ RPDU1_B5_SSPC_DianHuErr_04 : 51|1@1+ (1,0) [0|1] ""  JiaShiCang
 SG_ BackUp102 : 48|3@1+ (1,0) [0|0] ""  JiaShiCang
 SG_ RPDU1_B5_SSPC_I_Load_03 : 40|8@1+ (0.1,0) [0|25.5] "A"  JiaShiCang
 SG_ RPDU1_B5_SSPC_TripSta_03 : 38|2@1+ (1,0) [0|3] ""  JiaShiCang
 SG_ RPDU1_B5_SSPC_BitErr_03 : 37|1@1+ (1,0) [0|1] ""  JiaShiCang
 SG_ RPDU1_B5_SSPC_OnOffSta_03 : 36|1@1+ (1,0) [0|1] ""  JiaShiCang
 SG_ RPDU1_B5_SSPC_DianHuErr_03 : 35|1@1+ (1,0) [0|1] ""  JiaShiCang
 SG_ BackUp101 : 32|3@1+ (1,0) [0|0] ""  JiaShiCang
 SG_ RPDU1_B5_SSPC_I_Load_02 : 24|8@1+ (0.1,0) [0|25.5] "A"  JiaShiCang
 SG_ RPDU1_B5_SSPC_TripSta_02 : 22|2@1+ (1,0) [0|3] ""  JiaShiCang
 SG_ RPDU1_B5_SSPC_BitErr_02 : 21|1@1+ (1,0) [0|1] ""  JiaShiCang
 SG_ RPDU1_B5_SSPC_OnOffSta_02 : 20|1@1+ (1,0) [0|1] ""  JiaShiCang
 SG_ RPDU1_B5_SSPC_DianHuErr_02 : 19|1@1+ (1,0) [0|1] ""  JiaShiCang
 SG_ BackUp100 : 16|3@1+ (1,0) [0|0] ""  JiaShiCang
 SG_ RPDU1_B5_SSPC_I_Load_01 : 8|8@1+ (0.1,0) [0|25.5] "A"  JiaShiCang
 SG_ RPDU1_B5_SSPC_TripSta_01 : 6|2@1+ (1,0) [0|3] ""  JiaShiCang
 SG_ RPDU1_B5_SSPC_BitErr_01 : 5|1@1+ (1,0) [0|1] ""  JiaShiCang
 SG_ RPDU1_B5_SSPC_OnOffSta_01 : 4|1@1+ (1,0) [0|1] ""  JiaShiCang
 SG_ RPDU1_B5_SSPC_DianHuErr_01 : 3|1@1+ (1,0) [0|1] ""  JiaShiCang
 SG_ BackUp099 : 0|3@1+ (1,0) [0|0] ""  JiaShiCang

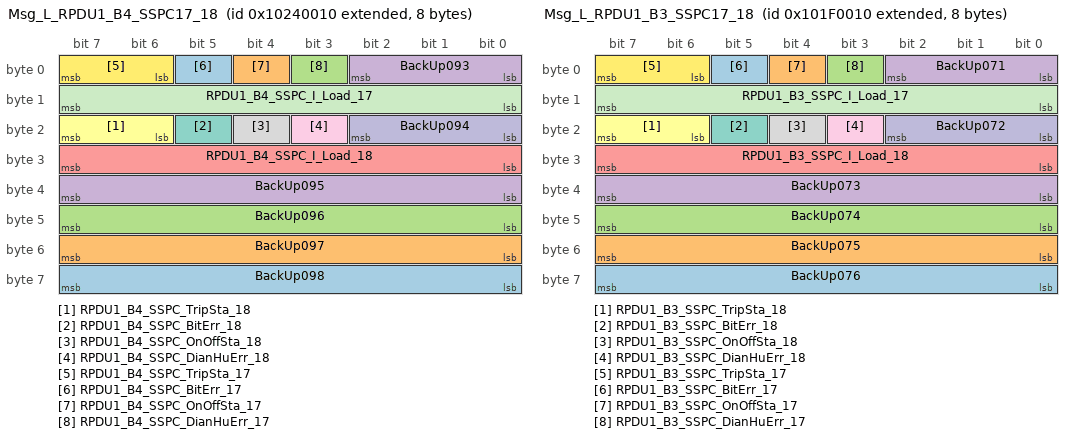
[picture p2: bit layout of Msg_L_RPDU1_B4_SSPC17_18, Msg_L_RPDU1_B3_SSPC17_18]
BO_ 2418278416 Msg_L_RPDU1_B4_SSPC17_18: 8 L_BPCU_MCU
 SG_ BackUp098 : 56|8@1+ (1,0) [0|0] ""  JiaShiCang
 SG_ BackUp097 : 48|8@1+ (1,0) [0|0] ""  JiaShiCang
 SG_ BackUp096 : 40|8@1+ (1,0) [0|0] ""  JiaShiCang
 SG_ BackUp095 : 32|8@1+ (1,0) [0|0] ""  JiaShiCang
 SG_ RPDU1_B4_SSPC_I_Load_18 : 24|8@1+ (0.1,0) [0|25.5] "A"  JiaShiCang
 SG_ RPDU1_B4_SSPC_TripSta_18 : 22|2@1+ (1,0) [0|3] ""  JiaShiCang
 SG_ RPDU1_B4_SSPC_BitErr_18 : 21|1@1+ (1,0) [0|1] ""  JiaShiCang
 SG_ RPDU1_B4_SSPC_OnOffSta_18 : 20|1@1+ (1,0) [0|1] ""  JiaShiCang
 SG_ RPDU1_B4_SSPC_DianHuErr_18 : 19|1@1+ (1,0) [0|1] ""  JiaShiCang
 SG_ BackUp094 : 16|3@1+ (1,0) [0|0] ""  JiaShiCang
 SG_ RPDU1_B4_SSPC_I_Load_17 : 8|8@1+ (0.1,0) [0|25.5] "A"  JiaShiCang
 SG_ RPDU1_B4_SSPC_TripSta_17 : 6|2@1+ (1,0) [0|3] ""  JiaShiCang
 SG_ RPDU1_B4_SSPC_BitErr_17 : 5|1@1+ (1,0) [0|1] ""  JiaShiCang
 SG_ RPDU1_B4_SSPC_OnOffSta_17 : 4|1@1+ (1,0) [0|1] ""  JiaShiCang
 SG_ RPDU1_B4_SSPC_DianHuErr_17 : 3|1@1+ (1,0) [0|1] ""  JiaShiCang
 SG_ BackUp093 : 0|3@1+ (1,0) [0|0] ""  JiaShiCang

BO_ 2418212880 Msg_L_RPDU1_B4_SSPC13_16: 8 L_BPCU_MCU
 SG_ RPDU1_B4_SSPC_I_Load_16 : 56|8@1+ (0.1,0) [0|25.5] "A"  JiaShiCang
 SG_ RPDU1_B4_SSPC_TripSta_16 : 54|2@1+ (1,0) [0|3] ""  JiaShiCang
 SG_ RPDU1_B4_SSPC_BitErr_16 : 53|1@1+ (1,0) [0|1] ""  JiaShiCang
 SG_ RPDU1_B4_SSPC_OnOffSta_16 : 52|1@1+ (1,0) [0|1] ""  JiaShiCang
 SG_ RPDU1_B4_SSPC_DianHuErr_16 : 51|1@1+ (1,0) [0|1] ""  JiaShiCang
 SG_ BackUp092 : 48|3@1+ (1,0) [0|0] ""  JiaShiCang
 SG_ RPDU1_B4_SSPC_I_Load_15 : 40|8@1+ (0.1,0) [0|25.5] "A"  JiaShiCang
 SG_ RPDU1_B4_SSPC_TripSta_15 : 38|2@1+ (1,0) [0|3] ""  JiaShiCang
 SG_ RPDU1_B4_SSPC_BitErr_15 : 37|1@1+ (1,0) [0|1] ""  JiaShiCang
 SG_ RPDU1_B4_SSPC_OnOffSta_15 : 36|1@1+ (1,0) [0|1] ""  JiaShiCang
 SG_ RPDU1_B4_SSPC_DianHuErr_15 : 35|1@1+ (1,0) [0|1] ""  JiaShiCang
 SG_ BackUp091 : 32|3@1+ (1,0) [0|0] ""  JiaShiCang
 SG_ RPDU1_B4_SSPC_I_Load_14 : 24|8@1+ (0.1,0) [0|25.5] "A"  JiaShiCang
 SG_ RPDU1_B4_SSPC_TripSta_14 : 22|2@1+ (1,0) [0|3] ""  JiaShiCang
 SG_ RPDU1_B4_SSPC_BitErr_14 : 21|1@1+ (1,0) [0|1] ""  JiaShiCang
 SG_ RPDU1_B4_SSPC_OnOffSta_14 : 20|1@1+ (1,0) [0|1] ""  JiaShiCang
 SG_ RPDU1_B4_SSPC_DianHuErr_14 : 19|1@1+ (1,0) [0|1] ""  JiaShiCang
 SG_ BackUp090 : 16|3@1+ (1,0) [0|0] ""  JiaShiCang
 SG_ RPDU1_B4_SSPC_I_Load_13 : 8|8@1+ (0.1,0) [0|25.5] "A"  JiaShiCang
 SG_ RPDU1_B4_SSPC_TripSta_13 : 6|2@1+ (1,0) [0|3] ""  JiaShiCang
 SG_ RPDU1_B4_SSPC_BitErr_13 : 5|1@1+ (1,0) [0|1] ""  JiaShiCang
 SG_ RPDU1_B4_SSPC_OnOffSta_13 : 4|1@1+ (1,0) [0|1] ""  JiaShiCang
 SG_ RPDU1_B4_SSPC_DianHuErr_13 : 3|1@1+ (1,0) [0|1] ""  JiaShiCang
 SG_ BackUp089 : 0|3@1+ (1,0) [0|0] ""  JiaShiCang

BO_ 2418147344 Msg_L_RPDU1_B4_SSPC09_12: 8 L_BPCU_MCU
 SG_ RPDU1_B4_SSPC_I_Load_12 : 56|8@1+ (0.1,0) [0|25.5] "A"  JiaShiCang
 SG_ RPDU1_B4_SSPC_TripSta_12 : 54|2@1+ (1,0) [0|3] ""  JiaShiCang
 SG_ RPDU1_B4_SSPC_BitErr_12 : 53|1@1+ (1,0) [0|1] ""  JiaShiCang
 SG_ RPDU1_B4_SSPC_OnOffSta_12 : 52|1@1+ (1,0) [0|1] ""  JiaShiCang
 SG_ RPDU1_B4_SSPC_DianHuErr_12 : 51|1@1+ (1,0) [0|1] ""  JiaShiCang
 SG_ BackUp088 : 48|3@1+ (1,0) [0|0] ""  JiaShiCang
 SG_ RPDU1_B4_SSPC_I_Load_11 : 40|8@1+ (0.1,0) [0|25.5] "A"  JiaShiCang
 SG_ RPDU1_B4_SSPC_TripSta_11 : 38|2@1+ (1,0) [0|3] ""  JiaShiCang
 SG_ RPDU1_B4_SSPC_BitErr_11 : 37|1@1+ (1,0) [0|1] ""  JiaShiCang
 SG_ RPDU1_B4_SSPC_OnOffSta_11 : 36|1@1+ (1,0) [0|1] ""  JiaShiCang
 SG_ RPDU1_B4_SSPC_DianHuErr_11 : 35|1@1+ (1,0) [0|1] ""  JiaShiCang
 SG_ BackUp087 : 32|3@1+ (1,0) [0|0] ""  JiaShiCang
 SG_ RPDU1_B4_SSPC_I_Load_10 : 24|8@1+ (0.1,0) [0|25.5] "A"  JiaShiCang
 SG_ RPDU1_B4_SSPC_TripSta_10 : 22|2@1+ (1,0) [0|3] ""  JiaShiCang
 SG_ RPDU1_B4_SSPC_BitErr_10 : 21|1@1+ (1,0) [0|1] ""  JiaShiCang
 SG_ RPDU1_B4_SSPC_OnOffSta_10 : 20|1@1+ (1,0) [0|1] ""  JiaShiCang
 SG_ RPDU1_B4_SSPC_DianHuErr_10 : 19|1@1+ (1,0) [0|1] ""  JiaShiCang
 SG_ BackUp086 : 16|3@1+ (1,0) [0|0] ""  JiaShiCang
 SG_ RPDU1_B4_SSPC_I_Load_09 : 8|8@1+ (0.1,0) [0|25.5] "A"  JiaShiCang
 SG_ RPDU1_B4_SSPC_TripSta_09 : 6|2@1+ (1,0) [0|3] ""  JiaShiCang
 SG_ RPDU1_B4_SSPC_BitErr_09 : 5|1@1+ (1,0) [0|1] ""  JiaShiCang
 SG_ RPDU1_B4_SSPC_OnOffSta_09 : 4|1@1+ (1,0) [0|1] ""  JiaShiCang
 SG_ RPDU1_B4_SSPC_DianHuErr_09 : 3|1@1+ (1,0) [0|1] ""  JiaShiCang
 SG_ BackUp085 : 0|3@1+ (1,0) [0|0] ""  JiaShiCang

BO_ 2418081808 Msg_L_RPDU1_B4_SSPC05_08: 8 L_BPCU_MCU
 SG_ RPDU1_B4_SSPC_I_Load_08 : 56|8@1+ (0.1,0) [0|25.5] "A"  JiaShiCang
 SG_ RPDU1_B4_SSPC_TripSta_08 : 54|2@1+ (1,0) [0|3] ""  JiaShiCang
 SG_ RPDU1_B4_SSPC_BitErr_08 : 53|1@1+ (1,0) [0|1] ""  JiaShiCang
 SG_ RPDU1_B4_SSPC_OnOffSta_08 : 52|1@1+ (1,0) [0|1] ""  JiaShiCang
 SG_ RPDU1_B4_SSPC_DianHuErr_08 : 51|1@1+ (1,0) [0|1] ""  JiaShiCang
 SG_ BackUp084 : 48|3@1+ (1,0) [0|0] ""  JiaShiCang
 SG_ RPDU1_B4_SSPC_I_Load_07 : 40|8@1+ (0.1,0) [0|25.5] "A"  JiaShiCang
 SG_ RPDU1_B4_SSPC_TripSta_07 : 38|2@1+ (1,0) [0|3] ""  JiaShiCang
 SG_ RPDU1_B4_SSPC_BitErr_07 : 37|1@1+ (1,0) [0|1] ""  JiaShiCang
 SG_ RPDU1_B4_SSPC_OnOffSta_07 : 36|1@1+ (1,0) [0|1] ""  JiaShiCang
 SG_ RPDU1_B4_SSPC_DianHuErr_07 : 35|1@1+ (1,0) [0|1] ""  JiaShiCang
 SG_ BackUp083 : 32|3@1+ (1,0) [0|0] ""  JiaShiCang
 SG_ RPDU1_B4_SSPC_I_Load_06 : 24|8@1+ (0.1,0) [0|25.5] "A"  JiaShiCang
 SG_ RPDU1_B4_SSPC_TripSta_06 : 22|2@1+ (1,0) [0|3] ""  JiaShiCang
 SG_ RPDU1_B4_SSPC_BitErr_06 : 21|1@1+ (1,0) [0|1] ""  JiaShiCang
 SG_ RPDU1_B4_SSPC_OnOffSta_06 : 20|1@1+ (1,0) [0|1] ""  JiaShiCang
 SG_ RPDU1_B4_SSPC_DianHuErr_06 : 19|1@1+ (1,0) [0|1] ""  JiaShiCang
 SG_ BackUp082 : 16|3@1+ (1,0) [0|0] ""  JiaShiCang
 SG_ RPDU1_B4_SSPC_I_Load_05 : 8|8@1+ (0.1,0) [0|25.5] "A"  JiaShiCang
 SG_ RPDU1_B4_SSPC_TripSta_05 : 6|2@1+ (1,0) [0|3] ""  JiaShiCang
 SG_ RPDU1_B4_SSPC_BitErr_05 : 5|1@1+ (1,0) [0|1] ""  JiaShiCang
 SG_ RPDU1_B4_SSPC_OnOffSta_05 : 4|1@1+ (1,0) [0|1] ""  JiaShiCang
 SG_ RPDU1_B4_SSPC_DianHuErr_05 : 3|1@1+ (1,0) [0|1] ""  JiaShiCang
 SG_ BackUp081 : 0|3@1+ (1,0) [0|0] ""  JiaShiCang

BO_ 2418016272 Msg_L_RPDU1_B4_SSPC01_04: 8 L_BPCU_MCU
 SG_ RPDU1_B4_SSPC_I_Load_04 : 56|8@1+ (0.1,0) [0|25.5] "A"  JiaShiCang
 SG_ RPDU1_B4_SSPC_TripSta_04 : 54|2@1+ (1,0) [0|3] ""  JiaShiCang
 SG_ RPDU1_B4_SSPC_BitErr_04 : 53|1@1+ (1,0) [0|1] ""  JiaShiCang
 SG_ RPDU1_B4_SSPC_OnOffSta_04 : 52|1@1+ (1,0) [0|1] ""  JiaShiCang
 SG_ RPDU1_B4_SSPC_DianHuErr_04 : 51|1@1+ (1,0) [0|1] ""  JiaShiCang
 SG_ BackUp080 : 48|3@1+ (1,0) [0|0] ""  JiaShiCang
 SG_ RPDU1_B4_SSPC_I_Load_03 : 40|8@1+ (0.1,0) [0|25.5] "A"  JiaShiCang
 SG_ RPDU1_B4_SSPC_TripSta_03 : 38|2@1+ (1,0) [0|3] ""  JiaShiCang
 SG_ RPDU1_B4_SSPC_BitErr_03 : 37|1@1+ (1,0) [0|1] ""  JiaShiCang
 SG_ RPDU1_B4_SSPC_OnOffSta_03 : 36|1@1+ (1,0) [0|1] ""  JiaShiCang
 SG_ RPDU1_B4_SSPC_DianHuErr_03 : 35|1@1+ (1,0) [0|1] ""  JiaShiCang
 SG_ BackUp079 : 32|3@1+ (1,0) [0|0] ""  JiaShiCang
 SG_ RPDU1_B4_SSPC_I_Load_02 : 24|8@1+ (0.1,0) [0|25.5] "A"  JiaShiCang
 SG_ RPDU1_B4_SSPC_TripSta_02 : 22|2@1+ (1,0) [0|3] ""  JiaShiCang
 SG_ RPDU1_B4_SSPC_BitErr_02 : 21|1@1+ (1,0) [0|1] ""  JiaShiCang
 SG_ RPDU1_B4_SSPC_OnOffSta_02 : 20|1@1+ (1,0) [0|1] ""  JiaShiCang
 SG_ RPDU1_B4_SSPC_DianHuErr_02 : 19|1@1+ (1,0) [0|1] ""  JiaShiCang
 SG_ BackUp078 : 16|3@1+ (1,0) [0|0] ""  JiaShiCang
 SG_ RPDU1_B4_SSPC_I_Load_01 : 8|8@1+ (0.1,0) [0|25.5] "A"  JiaShiCang
 SG_ RPDU1_B4_SSPC_TripSta_01 : 6|2@1+ (1,0) [0|3] ""  JiaShiCang
 SG_ RPDU1_B4_SSPC_BitErr_01 : 5|1@1+ (1,0) [0|1] ""  JiaShiCang
 SG_ RPDU1_B4_SSPC_OnOffSta_01 : 4|1@1+ (1,0) [0|1] ""  JiaShiCang
 SG_ RPDU1_B4_SSPC_DianHuErr_01 : 3|1@1+ (1,0) [0|1] ""  JiaShiCang
 SG_ BackUp077 : 0|3@1+ (1,0) [0|0] ""  JiaShiCang

BO_ 2417950736 Msg_L_RPDU1_B3_SSPC17_18: 8 L_BPCU_MCU
 SG_ BackUp076 : 56|8@1+ (1,0) [0|0] ""  JiaShiCang
 SG_ BackUp075 : 48|8@1+ (1,0) [0|0] ""  JiaShiCang
 SG_ BackUp074 : 40|8@1+ (1,0) [0|0] ""  JiaShiCang
 SG_ BackUp073 : 32|8@1+ (1,0) [0|0] ""  JiaShiCang
 SG_ RPDU1_B3_SSPC_I_Load_18 : 24|8@1+ (0.1,0) [0|25.5] "A"  JiaShiCang
 SG_ RPDU1_B3_SSPC_TripSta_18 : 22|2@1+ (1,0) [0|3] ""  JiaShiCang
 SG_ RPDU1_B3_SSPC_BitErr_18 : 21|1@1+ (1,0) [0|1] ""  JiaShiCang
 SG_ RPDU1_B3_SSPC_OnOffSta_18 : 20|1@1+ (1,0) [0|1] ""  JiaShiCang
 SG_ RPDU1_B3_SSPC_DianHuErr_18 : 19|1@1+ (1,0) [0|1] ""  JiaShiCang
 SG_ BackUp072 : 16|3@1+ (1,0) [0|0] ""  JiaShiCang
 SG_ RPDU1_B3_SSPC_I_Load_17 : 8|8@1+ (0.1,0) [0|25.5] "A"  JiaShiCang
 SG_ RPDU1_B3_SSPC_TripSta_17 : 6|2@1+ (1,0) [0|3] ""  JiaShiCang
 SG_ RPDU1_B3_SSPC_BitErr_17 : 5|1@1+ (1,0) [0|1] ""  JiaShiCang
 SG_ RPDU1_B3_SSPC_OnOffSta_17 : 4|1@1+ (1,0) [0|1] ""  JiaShiCang
 SG_ RPDU1_B3_SSPC_DianHuErr_17 : 3|1@1+ (1,0) [0|1] ""  JiaShiCang
 SG_ BackUp071 : 0|3@1+ (1,0) [0|0] ""  JiaShiCang

BO_ 2417885200 Msg_L_RPDU1_B3_SSPC13_16: 8 L_BPCU_MCU
 SG_ RPDU1_B3_SSPC_I_Load_16 : 56|8@1+ (0.1,0) [0|25.5] "A"  JiaShiCang
 SG_ RPDU1_B3_SSPC_TripSta_16 : 54|2@1+ (1,0) [0|3] ""  JiaShiCang
 SG_ RPDU1_B3_SSPC_BitErr_16 : 53|1@1+ (1,0) [0|1] ""  JiaShiCang
 SG_ RPDU1_B3_SSPC_OnOffSta_16 : 52|1@1+ (1,0) [0|1] ""  JiaShiCang
 SG_ RPDU1_B3_SSPC_DianHuErr_16 : 51|1@1+ (1,0) [0|1] ""  JiaShiCang
 SG_ BackUp070 : 48|3@1+ (1,0) [0|0] ""  JiaShiCang
 SG_ RPDU1_B3_SSPC_I_Load_15 : 40|8@1+ (0.1,0) [0|25.5] "A"  JiaShiCang
 SG_ RPDU1_B3_SSPC_TripSta_15 : 38|2@1+ (1,0) [0|3] ""  JiaShiCang
 SG_ RPDU1_B3_SSPC_BitErr_15 : 37|1@1+ (1,0) [0|1] ""  JiaShiCang
 SG_ RPDU1_B3_SSPC_OnOffSta_15 : 36|1@1+ (1,0) [0|1] ""  JiaShiCang
 SG_ RPDU1_B3_SSPC_DianHuErr_15 : 35|1@1+ (1,0) [0|1] ""  JiaShiCang
 SG_ BackUp069 : 32|3@1+ (1,0) [0|0] ""  JiaShiCang
 SG_ RPDU1_B3_SSPC_I_Load_14 : 24|8@1+ (0.1,0) [0|25.5] "A"  JiaShiCang
 SG_ RPDU1_B3_SSPC_TripSta_14 : 22|2@1+ (1,0) [0|3] ""  JiaShiCang
 SG_ RPDU1_B3_SSPC_BitErr_14 : 21|1@1+ (1,0) [0|1] ""  JiaShiCang
 SG_ RPDU1_B3_SSPC_OnOffSta_14 : 20|1@1+ (1,0) [0|1] ""  JiaShiCang
 SG_ RPDU1_B3_SSPC_DianHuErr_14 : 19|1@1+ (1,0) [0|1] ""  JiaShiCang
 SG_ BackUp068 : 16|3@1+ (1,0) [0|0] ""  JiaShiCang
 SG_ RPDU1_B3_SSPC_I_Load_13 : 8|8@1+ (0.1,0) [0|25.5] "A"  JiaShiCang
 SG_ RPDU1_B3_SSPC_TripSta_13 : 6|2@1+ (1,0) [0|3] ""  JiaShiCang
 SG_ RPDU1_B3_SSPC_BitErr_13 : 5|1@1+ (1,0) [0|1] ""  JiaShiCang
 SG_ RPDU1_B3_SSPC_OnOffSta_13 : 4|1@1+ (1,0) [0|1] ""  JiaShiCang
 SG_ RPDU1_B3_SSPC_DianHuErr_13 : 3|1@1+ (1,0) [0|1] ""  JiaShiCang
 SG_ BackUp067 : 0|3@1+ (1,0) [0|0] ""  JiaShiCang

BO_ 2417819664 Msg_L_RPDU1_B3_SSPC09_12: 8 L_BPCU_MCU
 SG_ RPDU1_B3_SSPC_I_Load_12 : 56|8@1+ (0.1,0) [0|25.5] "A"  JiaShiCang
 SG_ RPDU1_B3_SSPC_TripSta_12 : 54|2@1+ (1,0) [0|3] ""  JiaShiCang
 SG_ RPDU1_B3_SSPC_BitErr_12 : 53|1@1+ (1,0) [0|1] ""  JiaShiCang
 SG_ RPDU1_B3_SSPC_OnOffSta_12 : 52|1@1+ (1,0) [0|1] ""  JiaShiCang
 SG_ RPDU1_B3_SSPC_DianHuErr_12 : 51|1@1+ (1,0) [0|1] ""  JiaShiCang
 SG_ BackUp066 : 48|3@1+ (1,0) [0|0] ""  JiaShiCang
 SG_ RPDU1_B3_SSPC_I_Load_11 : 40|8@1+ (0.1,0) [0|25.5] "A"  JiaShiCang
 SG_ RPDU1_B3_SSPC_TripSta_11 : 38|2@1+ (1,0) [0|3] ""  JiaShiCang
 SG_ RPDU1_B3_SSPC_BitErr_11 : 37|1@1+ (1,0) [0|1] ""  JiaShiCang
 SG_ RPDU1_B3_SSPC_OnOffSta_11 : 36|1@1+ (1,0) [0|1] ""  JiaShiCang
 SG_ RPDU1_B3_SSPC_DianHuErr_11 : 35|1@1+ (1,0) [0|1] ""  JiaShiCang
 SG_ BackUp065 : 32|3@1+ (1,0) [0|0] ""  JiaShiCang
 SG_ RPDU1_B3_SSPC_I_Load_10 : 24|8@1+ (0.1,0) [0|25.5] "A"  JiaShiCang
 SG_ RPDU1_B3_SSPC_TripSta_10 : 22|2@1+ (1,0) [0|3] ""  JiaShiCang
 SG_ RPDU1_B3_SSPC_BitErr_10 : 21|1@1+ (1,0) [0|1] ""  JiaShiCang
 SG_ RPDU1_B3_SSPC_OnOffSta_10 : 20|1@1+ (1,0) [0|1] ""  JiaShiCang
 SG_ RPDU1_B3_SSPC_DianHuErr_10 : 19|1@1+ (1,0) [0|1] ""  JiaShiCang
 SG_ BackUp064 : 16|3@1+ (1,0) [0|0] ""  JiaShiCang
 SG_ RPDU1_B3_SSPC_I_Load_09 : 8|8@1+ (0.1,0) [0|25.5] "A"  JiaShiCang
 SG_ RPDU1_B3_SSPC_TripSta_09 : 6|2@1+ (1,0) [0|3] ""  JiaShiCang
 SG_ RPDU1_B3_SSPC_BitErr_09 : 5|1@1+ (1,0) [0|1] ""  JiaShiCang
 SG_ RPDU1_B3_SSPC_OnOffSta_09 : 4|1@1+ (1,0) [0|1] ""  JiaShiCang
 SG_ RPDU1_B3_SSPC_DianHuErr_09 : 3|1@1+ (1,0) [0|1] ""  JiaShiCang
 SG_ BackUp063 : 0|3@1+ (1,0) [0|0] ""  JiaShiCang

BO_ 2417754128 Msg_L_RPDU1_B3_SSPC05_08: 8 L_BPCU_MCU
 SG_ RPDU1_B3_SSPC_I_Load_08 : 56|8@1+ (0.1,0) [0|25.5] "A"  JiaShiCang
 SG_ RPDU1_B3_SSPC_TripSta_08 : 54|2@1+ (1,0) [0|3] ""  JiaShiCang
 SG_ RPDU1_B3_SSPC_BitErr_08 : 53|1@1+ (1,0) [0|1] ""  JiaShiCang
 SG_ RPDU1_B3_SSPC_OnOffSta_08 : 52|1@1+ (1,0) [0|1] ""  JiaShiCang
 SG_ RPDU1_B3_SSPC_DianHuErr_08 : 51|1@1+ (1,0) [0|1] ""  JiaShiCang
 SG_ BackUp062 : 48|3@1+ (1,0) [0|0] ""  JiaShiCang
 SG_ RPDU1_B3_SSPC_I_Load_07 : 40|8@1+ (0.1,0) [0|25.5] "A"  JiaShiCang
 SG_ RPDU1_B3_SSPC_TripSta_07 : 38|2@1+ (1,0) [0|3] ""  JiaShiCang
 SG_ RPDU1_B3_SSPC_BitErr_07 : 37|1@1+ (1,0) [0|1] ""  JiaShiCang
 SG_ RPDU1_B3_SSPC_OnOffSta_07 : 36|1@1+ (1,0) [0|1] ""  JiaShiCang
 SG_ RPDU1_B3_SSPC_DianHuErr_07 : 35|1@1+ (1,0) [0|1] ""  JiaShiCang
 SG_ BackUp061 : 32|3@1+ (1,0) [0|0] ""  JiaShiCang
 SG_ RPDU1_B3_SSPC_I_Load_06 : 24|8@1+ (0.1,0) [0|25.5] "A"  JiaShiCang
 SG_ RPDU1_B3_SSPC_TripSta_06 : 22|2@1+ (1,0) [0|3] ""  JiaShiCang
 SG_ RPDU1_B3_SSPC_BitErr_06 : 21|1@1+ (1,0) [0|1] ""  JiaShiCang
 SG_ RPDU1_B3_SSPC_OnOffSta_06 : 20|1@1+ (1,0) [0|1] ""  JiaShiCang
 SG_ RPDU1_B3_SSPC_DianHuErr_06 : 19|1@1+ (1,0) [0|1] ""  JiaShiCang
 SG_ BackUp060 : 16|3@1+ (1,0) [0|0] ""  JiaShiCang
 SG_ RPDU1_B3_SSPC_I_Load_05 : 8|8@1+ (0.1,0) [0|25.5] "A"  JiaShiCang
 SG_ RPDU1_B3_SSPC_TripSta_05 : 6|2@1+ (1,0) [0|3] ""  JiaShiCang
 SG_ RPDU1_B3_SSPC_BitErr_05 : 5|1@1+ (1,0) [0|1] ""  JiaShiCang
 SG_ RPDU1_B3_SSPC_OnOffSta_05 : 4|1@1+ (1,0) [0|1] ""  JiaShiCang
 SG_ RPDU1_B3_SSPC_DianHuErr_05 : 3|1@1+ (1,0) [0|1] ""  JiaShiCang
 SG_ BackUp059 : 0|3@1+ (1,0) [0|0] ""  JiaShiCang

BO_ 2417688592 Msg_L_RPDU1_B3_SSPC01_04: 8 L_BPCU_MCU
 SG_ RPDU1_B3_SSPC_I_Load_04 : 56|8@1+ (0.1,0) [0|25.5] "A"  JiaShiCang
 SG_ RPDU1_B3_SSPC_TripSta_04 : 54|2@1+ (1,0) [0|3] ""  JiaShiCang
 SG_ RPDU1_B3_SSPC_BitErr_04 : 53|1@1+ (1,0) [0|1] ""  JiaShiCang
 SG_ RPDU1_B3_SSPC_OnOffSta_04 : 52|1@1+ (1,0) [0|1] ""  JiaShiCang
 SG_ RPDU1_B3_SSPC_DianHuErr_04 : 51|1@1+ (1,0) [0|1] ""  JiaShiCang
 SG_ BackUp058 : 48|3@1+ (1,0) [0|0] ""  JiaShiCang
 SG_ RPDU1_B3_SSPC_I_Load_03 : 40|8@1+ (0.1,0) [0|25.5] "A"  JiaShiCang
 SG_ RPDU1_B3_SSPC_TripSta_03 : 38|2@1+ (1,0) [0|3] ""  JiaShiCang
 SG_ RPDU1_B3_SSPC_BitErr_03 : 37|1@1+ (1,0) [0|1] ""  JiaShiCang
 SG_ RPDU1_B3_SSPC_OnOffSta_03 : 36|1@1+ (1,0) [0|1] ""  JiaShiCang
 SG_ RPDU1_B3_SSPC_DianHuErr_03 : 35|1@1+ (1,0) [0|1] ""  JiaShiCang
 SG_ BackUp057 : 32|3@1+ (1,0) [0|0] ""  JiaShiCang
 SG_ RPDU1_B3_SSPC_I_Load_02 : 24|8@1+ (0.1,0) [0|25.5] "A"  JiaShiCang
 SG_ RPDU1_B3_SSPC_TripSta_02 : 22|2@1+ (1,0) [0|3] ""  JiaShiCang
 SG_ RPDU1_B3_SSPC_BitErr_02 : 21|1@1+ (1,0) [0|1] ""  JiaShiCang
 SG_ RPDU1_B3_SSPC_OnOffSta_02 : 20|1@1+ (1,0) [0|1] ""  JiaShiCang
 SG_ RPDU1_B3_SSPC_DianHuErr_02 : 19|1@1+ (1,0) [0|1] ""  JiaShiCang
 SG_ BackUp056 : 16|3@1+ (1,0) [0|0] ""  JiaShiCang
 SG_ RPDU1_B3_SSPC_I_Load_01 : 8|8@1+ (0.1,0) [0|25.5] "A"  JiaShiCang
 SG_ RPDU1_B3_SSPC_TripSta_01 : 6|2@1+ (1,0) [0|3] ""  JiaShiCang
 SG_ RPDU1_B3_SSPC_BitErr_01 : 5|1@1+ (1,0) [0|1] ""  JiaShiCang
 SG_ RPDU1_B3_SSPC_OnOffSta_01 : 4|1@1+ (1,0) [0|1] ""  JiaShiCang
 SG_ RPDU1_B3_SSPC_DianHuErr_01 : 3|1@1+ (1,0) [0|1] ""  JiaShiCang
 SG_ BackUp055 : 0|3@1+ (1,0) [0|0] ""  JiaShiCang

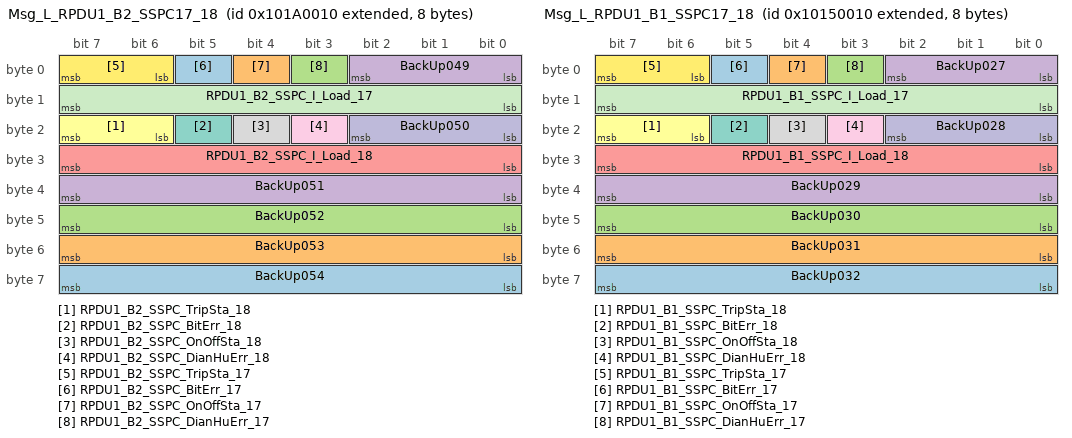
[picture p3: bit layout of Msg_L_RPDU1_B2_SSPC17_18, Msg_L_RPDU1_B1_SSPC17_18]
BO_ 2417623056 Msg_L_RPDU1_B2_SSPC17_18: 8 L_BPCU_MCU
 SG_ BackUp054 : 56|8@1+ (1,0) [0|0] ""  JiaShiCang
 SG_ BackUp053 : 48|8@1+ (1,0) [0|0] ""  JiaShiCang
 SG_ BackUp052 : 40|8@1+ (1,0) [0|0] ""  JiaShiCang
 SG_ BackUp051 : 32|8@1+ (1,0) [0|0] ""  JiaShiCang
 SG_ RPDU1_B2_SSPC_I_Load_18 : 24|8@1+ (0.1,0) [0|25.5] "A"  JiaShiCang
 SG_ RPDU1_B2_SSPC_TripSta_18 : 22|2@1+ (1,0) [0|3] ""  JiaShiCang
 SG_ RPDU1_B2_SSPC_BitErr_18 : 21|1@1+ (1,0) [0|1] ""  JiaShiCang
 SG_ RPDU1_B2_SSPC_OnOffSta_18 : 20|1@1+ (1,0) [0|1] ""  JiaShiCang
 SG_ RPDU1_B2_SSPC_DianHuErr_18 : 19|1@1+ (1,0) [0|1] ""  JiaShiCang
 SG_ BackUp050 : 16|3@1+ (1,0) [0|0] ""  JiaShiCang
 SG_ RPDU1_B2_SSPC_I_Load_17 : 8|8@1+ (0.1,0) [0|25.5] "A"  JiaShiCang
 SG_ RPDU1_B2_SSPC_TripSta_17 : 6|2@1+ (1,0) [0|3] ""  JiaShiCang
 SG_ RPDU1_B2_SSPC_BitErr_17 : 5|1@1+ (1,0) [0|1] ""  JiaShiCang
 SG_ RPDU1_B2_SSPC_OnOffSta_17 : 4|1@1+ (1,0) [0|1] ""  JiaShiCang
 SG_ RPDU1_B2_SSPC_DianHuErr_17 : 3|1@1+ (1,0) [0|1] ""  JiaShiCang
 SG_ BackUp049 : 0|3@1+ (1,0) [0|0] ""  JiaShiCang

BO_ 2417557520 Msg_L_RPDU1_B2_SSPC13_16: 8 L_BPCU_MCU
 SG_ RPDU1_B2_SSPC_I_Load_16 : 56|8@1+ (0.1,0) [0|25.5] "A"  JiaShiCang
 SG_ RPDU1_B2_SSPC_TripSta_16 : 54|2@1+ (1,0) [0|3] ""  JiaShiCang
 SG_ RPDU1_B2_SSPC_BitErr_16 : 53|1@1+ (1,0) [0|1] ""  JiaShiCang
 SG_ RPDU1_B2_SSPC_OnOffSta_16 : 52|1@1+ (1,0) [0|1] ""  JiaShiCang
 SG_ RPDU1_B2_SSPC_DianHuErr_16 : 51|1@1+ (1,0) [0|1] ""  JiaShiCang
 SG_ BackUp048 : 48|3@1+ (1,0) [0|0] ""  JiaShiCang
 SG_ RPDU1_B2_SSPC_I_Load_15 : 40|8@1+ (0.1,0) [0|25.5] "A"  JiaShiCang
 SG_ RPDU1_B2_SSPC_TripSta_15 : 38|2@1+ (1,0) [0|3] ""  JiaShiCang
 SG_ RPDU1_B2_SSPC_BitErr_15 : 37|1@1+ (1,0) [0|1] ""  JiaShiCang
 SG_ RPDU1_B2_SSPC_OnOffSta_15 : 36|1@1+ (1,0) [0|1] ""  JiaShiCang
 SG_ RPDU1_B2_SSPC_DianHuErr_15 : 35|1@1+ (1,0) [0|1] ""  JiaShiCang
 SG_ BackUp047 : 32|3@1+ (1,0) [0|0] ""  JiaShiCang
 SG_ RPDU1_B2_SSPC_I_Load_14 : 24|8@1+ (0.1,0) [0|25.5] "A"  JiaShiCang
 SG_ RPDU1_B2_SSPC_TripSta_14 : 22|2@1+ (1,0) [0|3] ""  JiaShiCang
 SG_ RPDU1_B2_SSPC_BitErr_14 : 21|1@1+ (1,0) [0|1] ""  JiaShiCang
 SG_ RPDU1_B2_SSPC_OnOffSta_14 : 20|1@1+ (1,0) [0|1] ""  JiaShiCang
 SG_ RPDU1_B2_SSPC_DianHuErr_14 : 19|1@1+ (1,0) [0|1] ""  JiaShiCang
 SG_ BackUp046 : 16|3@1+ (1,0) [0|0] ""  JiaShiCang
 SG_ RPDU1_B2_SSPC_I_Load_13 : 8|8@1+ (0.1,0) [0|25.5] "A"  JiaShiCang
 SG_ RPDU1_B2_SSPC_TripSta_13 : 6|2@1+ (1,0) [0|3] ""  JiaShiCang
 SG_ RPDU1_B2_SSPC_BitErr_13 : 5|1@1+ (1,0) [0|1] ""  JiaShiCang
 SG_ RPDU1_B2_SSPC_OnOffSta_13 : 4|1@1+ (1,0) [0|1] ""  JiaShiCang
 SG_ RPDU1_B2_SSPC_DianHuErr_13 : 3|1@1+ (1,0) [0|1] ""  JiaShiCang
 SG_ BackUp045 : 0|3@1+ (1,0) [0|0] ""  JiaShiCang

BO_ 2417491984 Msg_L_RPDU1_B2_SSPC09_12: 8 L_BPCU_MCU
 SG_ RPDU1_B2_SSPC_I_Load_12 : 56|8@1+ (0.1,0) [0|25.5] "A"  JiaShiCang
 SG_ RPDU1_B2_SSPC_TripSta_12 : 54|2@1+ (1,0) [0|3] ""  JiaShiCang
 SG_ RPDU1_B2_SSPC_BitErr_12 : 53|1@1+ (1,0) [0|1] ""  JiaShiCang
 SG_ RPDU1_B2_SSPC_OnOffSta_12 : 52|1@1+ (1,0) [0|1] ""  JiaShiCang
 SG_ RPDU1_B2_SSPC_DianHuErr_12 : 51|1@1+ (1,0) [0|1] ""  JiaShiCang
 SG_ BackUp044 : 48|3@1+ (1,0) [0|0] ""  JiaShiCang
 SG_ RPDU1_B2_SSPC_I_Load_11 : 40|8@1+ (0.1,0) [0|25.5] "A"  JiaShiCang
 SG_ RPDU1_B2_SSPC_TripSta_11 : 38|2@1+ (1,0) [0|3] ""  JiaShiCang
 SG_ RPDU1_B2_SSPC_BitErr_11 : 37|1@1+ (1,0) [0|1] ""  JiaShiCang
 SG_ RPDU1_B2_SSPC_OnOffSta_11 : 36|1@1+ (1,0) [0|1] ""  JiaShiCang
 SG_ RPDU1_B2_SSPC_DianHuErr_11 : 35|1@1+ (1,0) [0|1] ""  JiaShiCang
 SG_ BackUp043 : 32|3@1+ (1,0) [0|0] ""  JiaShiCang
 SG_ RPDU1_B2_SSPC_I_Load_10 : 24|8@1+ (0.1,0) [0|25.5] "A"  JiaShiCang
 SG_ RPDU1_B2_SSPC_TripSta_10 : 22|2@1+ (1,0) [0|3] ""  JiaShiCang
 SG_ RPDU1_B2_SSPC_BitErr_10 : 21|1@1+ (1,0) [0|1] ""  JiaShiCang
 SG_ RPDU1_B2_SSPC_OnOffSta_10 : 20|1@1+ (1,0) [0|1] ""  JiaShiCang
 SG_ RPDU1_B2_SSPC_DianHuErr_10 : 19|1@1+ (1,0) [0|1] ""  JiaShiCang
 SG_ BackUp042 : 16|3@1+ (1,0) [0|0] ""  JiaShiCang
 SG_ RPDU1_B2_SSPC_I_Load_09 : 8|8@1+ (0.1,0) [0|25.5] "A"  JiaShiCang
 SG_ RPDU1_B2_SSPC_TripSta_09 : 6|2@1+ (1,0) [0|3] ""  JiaShiCang
 SG_ RPDU1_B2_SSPC_BitErr_09 : 5|1@1+ (1,0) [0|1] ""  JiaShiCang
 SG_ RPDU1_B2_SSPC_OnOffSta_09 : 4|1@1+ (1,0) [0|1] ""  JiaShiCang
 SG_ RPDU1_B2_SSPC_DianHuErr_09 : 3|1@1+ (1,0) [0|1] ""  JiaShiCang
 SG_ BackUp041 : 0|3@1+ (1,0) [0|0] ""  JiaShiCang

BO_ 2417426448 Msg_L_RPDU1_B2_SSPC05_08: 8 L_BPCU_MCU
 SG_ RPDU1_B2_SSPC_I_Load_08 : 56|8@1+ (0.1,0) [0|25.5] "A"  JiaShiCang
 SG_ RPDU1_B2_SSPC_TripSta_08 : 54|2@1+ (1,0) [0|3] ""  JiaShiCang
 SG_ RPDU1_B2_SSPC_BitErr_08 : 53|1@1+ (1,0) [0|1] ""  JiaShiCang
 SG_ RPDU1_B2_SSPC_OnOffSta_08 : 52|1@1+ (1,0) [0|1] ""  JiaShiCang
 SG_ RPDU1_B2_SSPC_DianHuErr_08 : 51|1@1+ (1,0) [0|1] ""  JiaShiCang
 SG_ BackUp040 : 48|3@1+ (1,0) [0|0] ""  JiaShiCang
 SG_ RPDU1_B2_SSPC_I_Load_07 : 40|8@1+ (0.1,0) [0|25.5] "A"  JiaShiCang
 SG_ RPDU1_B2_SSPC_TripSta_07 : 38|2@1+ (1,0) [0|3] ""  JiaShiCang
 SG_ RPDU1_B2_SSPC_BitErr_07 : 37|1@1+ (1,0) [0|1] ""  JiaShiCang
 SG_ RPDU1_B2_SSPC_OnOffSta_07 : 36|1@1+ (1,0) [0|1] ""  JiaShiCang
 SG_ RPDU1_B2_SSPC_DianHuErr_07 : 35|1@1+ (1,0) [0|1] ""  JiaShiCang
 SG_ BackUp039 : 32|3@1+ (1,0) [0|0] ""  JiaShiCang
 SG_ RPDU1_B2_SSPC_I_Load_06 : 24|8@1+ (0.1,0) [0|25.5] "A"  JiaShiCang
 SG_ RPDU1_B2_SSPC_TripSta_06 : 22|2@1+ (1,0) [0|3] ""  JiaShiCang
 SG_ RPDU1_B2_SSPC_BitErr_06 : 21|1@1+ (1,0) [0|1] ""  JiaShiCang
 SG_ RPDU1_B2_SSPC_OnOffSta_06 : 20|1@1+ (1,0) [0|1] ""  JiaShiCang
 SG_ RPDU1_B2_SSPC_DianHuErr_06 : 19|1@1+ (1,0) [0|1] ""  JiaShiCang
 SG_ BackUp038 : 16|3@1+ (1,0) [0|0] ""  JiaShiCang
 SG_ RPDU1_B2_SSPC_I_Load_05 : 8|8@1+ (0.1,0) [0|25.5] "A"  JiaShiCang
 SG_ RPDU1_B2_SSPC_TripSta_05 : 6|2@1+ (1,0) [0|3] ""  JiaShiCang
 SG_ RPDU1_B2_SSPC_BitErr_05 : 5|1@1+ (1,0) [0|1] ""  JiaShiCang
 SG_ RPDU1_B2_SSPC_OnOffSta_05 : 4|1@1+ (1,0) [0|1] ""  JiaShiCang
 SG_ RPDU1_B2_SSPC_DianHuErr_05 : 3|1@1+ (1,0) [0|1] ""  JiaShiCang
 SG_ BackUp037 : 0|3@1+ (1,0) [0|0] ""  JiaShiCang

BO_ 2417360912 Msg_L_RPDU1_B2_SSPC01_04: 8 L_BPCU_MCU
 SG_ RPDU1_B2_SSPC_I_Load_04 : 56|8@1+ (0.1,0) [0|25.5] "A"  JiaShiCang
 SG_ RPDU1_B2_SSPC_TripSta_04 : 54|2@1+ (1,0) [0|3] ""  JiaShiCang
 SG_ RPDU1_B2_SSPC_BitErr_04 : 53|1@1+ (1,0) [0|1] ""  JiaShiCang
 SG_ RPDU1_B2_SSPC_OnOffSta_04 : 52|1@1+ (1,0) [0|1] ""  JiaShiCang
 SG_ RPDU1_B2_SSPC_DianHuErr_04 : 51|1@1+ (1,0) [0|1] ""  JiaShiCang
 SG_ BackUp036 : 48|3@1+ (1,0) [0|0] ""  JiaShiCang
 SG_ RPDU1_B2_SSPC_I_Load_03 : 40|8@1+ (0.1,0) [0|25.5] "A"  JiaShiCang
 SG_ RPDU1_B2_SSPC_TripSta_03 : 38|2@1+ (1,0) [0|3] ""  JiaShiCang
 SG_ RPDU1_B2_SSPC_BitErr_03 : 37|1@1+ (1,0) [0|1] ""  JiaShiCang
 SG_ RPDU1_B2_SSPC_OnOffSta_03 : 36|1@1+ (1,0) [0|1] ""  JiaShiCang
 SG_ RPDU1_B2_SSPC_DianHuErr_03 : 35|1@1+ (1,0) [0|1] ""  JiaShiCang
 SG_ BackUp035 : 32|3@1+ (1,0) [0|0] ""  JiaShiCang
 SG_ RPDU1_B2_SSPC_I_Load_02 : 24|8@1+ (0.1,0) [0|25.5] "A"  JiaShiCang
 SG_ RPDU1_B2_SSPC_TripSta_02 : 22|2@1+ (1,0) [0|3] ""  JiaShiCang
 SG_ RPDU1_B2_SSPC_BitErr_02 : 21|1@1+ (1,0) [0|1] ""  JiaShiCang
 SG_ RPDU1_B2_SSPC_OnOffSta_02 : 20|1@1+ (1,0) [0|1] ""  JiaShiCang
 SG_ RPDU1_B2_SSPC_DianHuErr_02 : 19|1@1+ (1,0) [0|1] ""  JiaShiCang
 SG_ BackUp034 : 16|3@1+ (1,0) [0|0] ""  JiaShiCang
 SG_ RPDU1_B2_SSPC_I_Load_01 : 8|8@1+ (0.1,0) [0|25.5] "A"  JiaShiCang
 SG_ RPDU1_B2_SSPC_TripSta_01 : 6|2@1+ (1,0) [0|3] ""  JiaShiCang
 SG_ RPDU1_B2_SSPC_BitErr_01 : 5|1@1+ (1,0) [0|1] ""  JiaShiCang
 SG_ RPDU1_B2_SSPC_OnOffSta_01 : 4|1@1+ (1,0) [0|1] ""  JiaShiCang
 SG_ RPDU1_B2_SSPC_DianHuErr_01 : 3|1@1+ (1,0) [0|1] ""  JiaShiCang
 SG_ BackUp033 : 0|3@1+ (1,0) [0|0] ""  JiaShiCang

BO_ 2417295376 Msg_L_RPDU1_B1_SSPC17_18: 8 L_BPCU_MCU
 SG_ BackUp032 : 56|8@1+ (1,0) [0|0] ""  JiaShiCang
 SG_ BackUp031 : 48|8@1+ (1,0) [0|0] ""  JiaShiCang
 SG_ BackUp030 : 40|8@1+ (1,0) [0|0] ""  JiaShiCang
 SG_ BackUp029 : 32|8@1+ (1,0) [0|0] ""  JiaShiCang
 SG_ RPDU1_B1_SSPC_I_Load_18 : 24|8@1+ (0.1,0) [0|25.5] "A"  JiaShiCang
 SG_ RPDU1_B1_SSPC_TripSta_18 : 22|2@1+ (1,0) [0|3] ""  JiaShiCang
 SG_ RPDU1_B1_SSPC_BitErr_18 : 21|1@1+ (1,0) [0|1] ""  JiaShiCang
 SG_ RPDU1_B1_SSPC_OnOffSta_18 : 20|1@1+ (1,0) [0|1] ""  JiaShiCang
 SG_ RPDU1_B1_SSPC_DianHuErr_18 : 19|1@1+ (1,0) [0|1] ""  JiaShiCang
 SG_ BackUp028 : 16|3@1+ (1,0) [0|0] ""  JiaShiCang
 SG_ RPDU1_B1_SSPC_I_Load_17 : 8|8@1+ (0.1,0) [0|25.5] "A"  JiaShiCang
 SG_ RPDU1_B1_SSPC_TripSta_17 : 6|2@1+ (1,0) [0|3] ""  JiaShiCang
 SG_ RPDU1_B1_SSPC_BitErr_17 : 5|1@1+ (1,0) [0|1] ""  JiaShiCang
 SG_ RPDU1_B1_SSPC_OnOffSta_17 : 4|1@1+ (1,0) [0|1] ""  JiaShiCang
 SG_ RPDU1_B1_SSPC_DianHuErr_17 : 3|1@1+ (1,0) [0|1] ""  JiaShiCang
 SG_ BackUp027 : 0|3@1+ (1,0) [0|0] ""  JiaShiCang

BO_ 2417229840 Msg_L_RPDU1_B1_SSPC13_16: 8 L_BPCU_MCU
 SG_ RPDU1_B1_SSPC_I_Load_16 : 56|8@1+ (0.1,0) [0|25.5] "A"  JiaShiCang
 SG_ RPDU1_B1_SSPC_TripSta_16 : 54|2@1+ (1,0) [0|3] ""  JiaShiCang
 SG_ RPDU1_B1_SSPC_BitErr_16 : 53|1@1+ (1,0) [0|1] ""  JiaShiCang
 SG_ RPDU1_B1_SSPC_OnOffSta_16 : 52|1@1+ (1,0) [0|1] ""  JiaShiCang
 SG_ RPDU1_B1_SSPC_DianHuErr_16 : 51|1@1+ (1,0) [0|1] ""  JiaShiCang
 SG_ BackUp026 : 48|3@1+ (1,0) [0|0] ""  JiaShiCang
 SG_ RPDU1_B1_SSPC_I_Load_15 : 40|8@1+ (0.1,0) [0|25.5] "A"  JiaShiCang
 SG_ RPDU1_B1_SSPC_TripSta_15 : 38|2@1+ (1,0) [0|3] ""  JiaShiCang
 SG_ RPDU1_B1_SSPC_BitErr_15 : 37|1@1+ (1,0) [0|1] ""  JiaShiCang
 SG_ RPDU1_B1_SSPC_OnOffSta_15 : 36|1@1+ (1,0) [0|1] ""  JiaShiCang
 SG_ RPDU1_B1_SSPC_DianHuErr_15 : 35|1@1+ (1,0) [0|1] ""  JiaShiCang
 SG_ BackUp025 : 32|3@1+ (1,0) [0|0] ""  JiaShiCang
 SG_ RPDU1_B1_SSPC_I_Load_14 : 24|8@1+ (0.1,0) [0|25.5] "A"  JiaShiCang
 SG_ RPDU1_B1_SSPC_TripSta_14 : 22|2@1+ (1,0) [0|3] ""  JiaShiCang
 SG_ RPDU1_B1_SSPC_BitErr_14 : 21|1@1+ (1,0) [0|1] ""  JiaShiCang
 SG_ RPDU1_B1_SSPC_OnOffSta_14 : 20|1@1+ (1,0) [0|1] ""  JiaShiCang
 SG_ RPDU1_B1_SSPC_DianHuErr_14 : 19|1@1+ (1,0) [0|1] ""  JiaShiCang
 SG_ BackUp024 : 16|3@1+ (1,0) [0|0] ""  JiaShiCang
 SG_ RPDU1_B1_SSPC_I_Load_13 : 8|8@1+ (0.1,0) [0|25.5] "A"  JiaShiCang
 SG_ RPDU1_B1_SSPC_TripSta_13 : 6|2@1+ (1,0) [0|3] ""  JiaShiCang
 SG_ RPDU1_B1_SSPC_BitErr_13 : 5|1@1+ (1,0) [0|1] ""  JiaShiCang
 SG_ RPDU1_B1_SSPC_OnOffSta_13 : 4|1@1+ (1,0) [0|1] ""  JiaShiCang
 SG_ RPDU1_B1_SSPC_DianHuErr_13 : 3|1@1+ (1,0) [0|1] ""  JiaShiCang
 SG_ BackUp023 : 0|3@1+ (1,0) [0|0] ""  JiaShiCang

BO_ 2417164304 Msg_L_RPDU1_B1_SSPC09_12: 8 L_BPCU_MCU
 SG_ RPDU1_B1_SSPC_I_Load_12 : 56|8@1+ (0.1,0) [0|25.5] "A"  JiaShiCang
 SG_ RPDU1_B1_SSPC_TripSta_12 : 54|2@1+ (1,0) [0|3] ""  JiaShiCang
 SG_ RPDU1_B1_SSPC_BitErr_12 : 53|1@1+ (1,0) [0|1] ""  JiaShiCang
 SG_ RPDU1_B1_SSPC_OnOffSta_12 : 52|1@1+ (1,0) [0|1] ""  JiaShiCang
 SG_ RPDU1_B1_SSPC_DianHuErr_12 : 51|1@1+ (1,0) [0|1] ""  JiaShiCang
 SG_ BackUp022 : 48|3@1+ (1,0) [0|0] ""  JiaShiCang
 SG_ RPDU1_B1_SSPC_I_Load_11 : 40|8@1+ (0.1,0) [0|25.5] "A"  JiaShiCang
 SG_ RPDU1_B1_SSPC_TripSta_11 : 38|2@1+ (1,0) [0|3] ""  JiaShiCang
 SG_ RPDU1_B1_SSPC_BitErr_11 : 37|1@1+ (1,0) [0|1] ""  JiaShiCang
 SG_ RPDU1_B1_SSPC_OnOffSta_11 : 36|1@1+ (1,0) [0|1] ""  JiaShiCang
 SG_ RPDU1_B1_SSPC_DianHuErr_11 : 35|1@1+ (1,0) [0|1] ""  JiaShiCang
 SG_ BackUp021 : 32|3@1+ (1,0) [0|0] ""  JiaShiCang
 SG_ RPDU1_B1_SSPC_I_Load_10 : 24|8@1+ (0.1,0) [0|25.5] "A"  JiaShiCang
 SG_ RPDU1_B1_SSPC_TripSta_10 : 22|2@1+ (1,0) [0|3] ""  JiaShiCang
 SG_ RPDU1_B1_SSPC_BitErr_10 : 21|1@1+ (1,0) [0|1] ""  JiaShiCang
 SG_ RPDU1_B1_SSPC_OnOffSta_10 : 20|1@1+ (1,0) [0|1] ""  JiaShiCang
 SG_ RPDU1_B1_SSPC_DianHuErr_10 : 19|1@1+ (1,0) [0|1] ""  JiaShiCang
 SG_ BackUp020 : 16|3@1+ (1,0) [0|0] ""  JiaShiCang
 SG_ RPDU1_B1_SSPC_I_Load_09 : 8|8@1+ (0.1,0) [0|25.5] "A"  JiaShiCang
 SG_ RPDU1_B1_SSPC_TripSta_09 : 6|2@1+ (1,0) [0|3] ""  JiaShiCang
 SG_ RPDU1_B1_SSPC_BitErr_09 : 5|1@1+ (1,0) [0|1] ""  JiaShiCang
 SG_ RPDU1_B1_SSPC_OnOffSta_09 : 4|1@1+ (1,0) [0|1] ""  JiaShiCang
 SG_ RPDU1_B1_SSPC_DianHuErr_09 : 3|1@1+ (1,0) [0|1] ""  JiaShiCang
 SG_ BackUp019 : 0|3@1+ (1,0) [0|0] ""  JiaShiCang

BO_ 2417098768 Msg_L_RPDU1_B1_SSPC05_08: 8 L_BPCU_MCU
 SG_ RPDU1_B1_SSPC_I_Load_08 : 56|8@1+ (0.1,0) [0|25.5] "A"  JiaShiCang
 SG_ RPDU1_B1_SSPC_TripSta_08 : 54|2@1+ (1,0) [0|3] ""  JiaShiCang
 SG_ RPDU1_B1_SSPC_BitErr_08 : 53|1@1+ (1,0) [0|1] ""  JiaShiCang
 SG_ RPDU1_B1_SSPC_OnOffSta_08 : 52|1@1+ (1,0) [0|1] ""  JiaShiCang
 SG_ RPDU1_B1_SSPC_DianHuErr_08 : 51|1@1+ (1,0) [0|1] ""  JiaShiCang
 SG_ BackUp018 : 48|3@1+ (1,0) [0|0] ""  JiaShiCang
 SG_ RPDU1_B1_SSPC_I_Load_07 : 40|8@1+ (0.1,0) [0|25.5] "A"  JiaShiCang
 SG_ RPDU1_B1_SSPC_TripSta_07 : 38|2@1+ (1,0) [0|3] ""  JiaShiCang
 SG_ RPDU1_B1_SSPC_BitErr_07 : 37|1@1+ (1,0) [0|1] ""  JiaShiCang
 SG_ RPDU1_B1_SSPC_OnOffSta_07 : 36|1@1+ (1,0) [0|1] ""  JiaShiCang
 SG_ RPDU1_B1_SSPC_DianHuErr_07 : 35|1@1+ (1,0) [0|1] ""  JiaShiCang
 SG_ BackUp017 : 32|3@1+ (1,0) [0|0] ""  JiaShiCang
 SG_ RPDU1_B1_SSPC_I_Load_06 : 24|8@1+ (0.1,0) [0|25.5] "A"  JiaShiCang
 SG_ RPDU1_B1_SSPC_TripSta_06 : 22|2@1+ (1,0) [0|3] ""  JiaShiCang
 SG_ RPDU1_B1_SSPC_BitErr_06 : 21|1@1+ (1,0) [0|1] ""  JiaShiCang
 SG_ RPDU1_B1_SSPC_OnOffSta_06 : 20|1@1+ (1,0) [0|1] ""  JiaShiCang
 SG_ RPDU1_B1_SSPC_DianHuErr_06 : 19|1@1+ (1,0) [0|1] ""  JiaShiCang
 SG_ BackUp016 : 16|3@1+ (1,0) [0|0] ""  JiaShiCang
 SG_ RPDU1_B1_SSPC_I_Load_05 : 8|8@1+ (0.1,0) [0|25.5] "A"  JiaShiCang
 SG_ RPDU1_B1_SSPC_TripSta_05 : 6|2@1+ (1,0) [0|3] ""  JiaShiCang
 SG_ RPDU1_B1_SSPC_BitErr_05 : 5|1@1+ (1,0) [0|1] ""  JiaShiCang
 SG_ RPDU1_B1_SSPC_OnOffSta_05 : 4|1@1+ (1,0) [0|1] ""  JiaShiCang
 SG_ RPDU1_B1_SSPC_DianHuErr_05 : 3|1@1+ (1,0) [0|1] ""  JiaShiCang
 SG_ BackUp015 : 0|3@1+ (1,0) [0|0] ""  JiaShiCang

BO_ 2417033232 Msg_L_RPDU1_B1_SSPC01_04: 8 L_BPCU_MCU
 SG_ RPDU1_B1_SSPC_I_Load_04 : 56|8@1+ (0.1,0) [0|25.5] "A"  JiaShiCang
 SG_ RPDU1_B1_SSPC_TripSta_04 : 54|2@1+ (1,0) [0|3] ""  JiaShiCang
 SG_ RPDU1_B1_SSPC_BitErr_04 : 53|1@1+ (1,0) [0|1] ""  JiaShiCang
 SG_ RPDU1_B1_SSPC_OnOffSta_04 : 52|1@1+ (1,0) [0|1] ""  JiaShiCang
 SG_ RPDU1_B1_SSPC_DianHuErr_04 : 51|1@1+ (1,0) [0|1] ""  JiaShiCang
 SG_ BackUp014 : 48|3@1+ (1,0) [0|0] ""  JiaShiCang
 SG_ RPDU1_B1_SSPC_I_Load_03 : 40|8@1+ (0.1,0) [0|25.5] "A"  JiaShiCang
 SG_ RPDU1_B1_SSPC_TripSta_03 : 38|2@1+ (1,0) [0|3] ""  JiaShiCang
 SG_ RPDU1_B1_SSPC_BitErr_03 : 37|1@1+ (1,0) [0|1] ""  JiaShiCang
 SG_ RPDU1_B1_SSPC_OnOffSta_03 : 36|1@1+ (1,0) [0|1] ""  JiaShiCang
 SG_ RPDU1_B1_SSPC_DianHuErr_03 : 35|1@1+ (1,0) [0|1] ""  JiaShiCang
 SG_ BackUp013 : 32|3@1+ (1,0) [0|0] ""  JiaShiCang
 SG_ RPDU1_B1_SSPC_I_Load_02 : 24|8@1+ (0.1,0) [0|25.5] "A"  JiaShiCang
 SG_ RPDU1_B1_SSPC_TripSta_02 : 22|2@1+ (1,0) [0|3] ""  JiaShiCang
 SG_ RPDU1_B1_SSPC_BitErr_02 : 21|1@1+ (1,0) [0|1] ""  JiaShiCang
 SG_ RPDU1_B1_SSPC_OnOffSta_02 : 20|1@1+ (1,0) [0|1] ""  JiaShiCang
 SG_ RPDU1_B1_SSPC_DianHuErr_02 : 19|1@1+ (1,0) [0|1] ""  JiaShiCang
 SG_ BackUp012 : 16|3@1+ (1,0) [0|0] ""  JiaShiCang
 SG_ RPDU1_B1_SSPC_I_Load_01 : 8|8@1+ (0.1,0) [0|25.5] "A"  JiaShiCang
 SG_ RPDU1_B1_SSPC_TripSta_01 : 6|2@1+ (1,0) [0|3] ""  JiaShiCang
 SG_ RPDU1_B1_SSPC_BitErr_01 : 5|1@1+ (1,0) [0|1] ""  JiaShiCang
 SG_ RPDU1_B1_SSPC_OnOffSta_01 : 4|1@1+ (1,0) [0|1] ""  JiaShiCang
 SG_ RPDU1_B1_SSPC_DianHuErr_01 : 3|1@1+ (1,0) [0|1] ""  JiaShiCang
 SG_ BackUp011 : 0|3@1+ (1,0) [0|0] ""  JiaShiCang

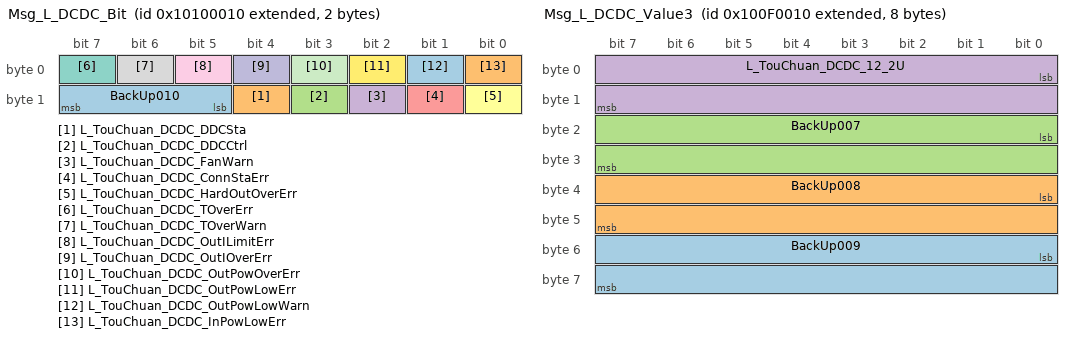
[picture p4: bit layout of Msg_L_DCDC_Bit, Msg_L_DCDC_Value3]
BO_ 2416967696 Msg_L_DCDC_Bit: 2 L_BPCU_MCU
 SG_ BackUp010 : 13|3@1+ (1,0) [0|0] ""  JiaShiCang
 SG_ L_TouChuan_DCDC_DDCSta : 12|1@1+ (1,0) [0|1] ""  JiaShiCang
 SG_ L_TouChuan_DCDC_DDCCtrl : 11|1@1+ (1,0) [0|1] ""  JiaShiCang
 SG_ L_TouChuan_DCDC_FanWarn : 10|1@1+ (1,0) [0|1] ""  JiaShiCang
 SG_ L_TouChuan_DCDC_ConnStaErr : 9|1@1+ (1,0) [0|1] ""  JiaShiCang
 SG_ L_TouChuan_DCDC_HardOutOverErr : 8|1@1+ (1,0) [0|1] ""  JiaShiCang
 SG_ L_TouChuan_DCDC_TOverErr : 7|1@1+ (1,0) [0|1] ""  JiaShiCang
 SG_ L_TouChuan_DCDC_TOverWarn : 6|1@1+ (1,0) [0|1] ""  JiaShiCang
 SG_ L_TouChuan_DCDC_OutILimitErr : 5|1@1+ (1,0) [0|1] ""  JiaShiCang
 SG_ L_TouChuan_DCDC_OutIOverErr : 4|1@1+ (1,0) [0|1] ""  JiaShiCang
 SG_ L_TouChuan_DCDC_OutPowOverErr : 3|1@1+ (1,0) [0|1] ""  JiaShiCang
 SG_ L_TouChuan_DCDC_OutPowLowErr : 2|1@1+ (1,0) [0|1] ""  JiaShiCang
 SG_ L_TouChuan_DCDC_OutPowLowWarn : 1|1@1+ (1,0) [0|1] ""  JiaShiCang
 SG_ L_TouChuan_DCDC_InPowLowErr : 0|1@1+ (1,0) [0|1] ""  JiaShiCang

BO_ 2416902160 Msg_L_DCDC_Value3: 8 L_BPCU_MCU
 SG_ BackUp009 : 48|16@1+ (1,0) [0|0] ""  JiaShiCang
 SG_ BackUp008 : 32|16@1+ (1,0) [0|0] ""  JiaShiCang
 SG_ BackUp007 : 16|16@1+ (1,0) [0|0] ""  JiaShiCang
 SG_ L_TouChuan_DCDC_12_2U : 0|16@1+ (0.1,0) [0|6553.5] "V"  JiaShiCang

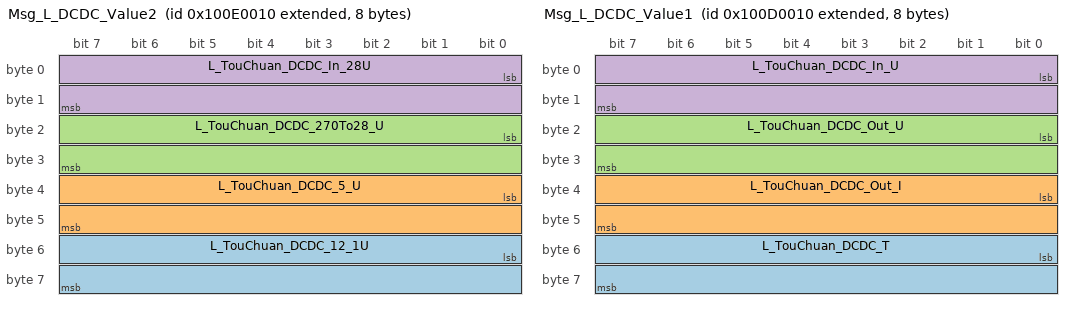
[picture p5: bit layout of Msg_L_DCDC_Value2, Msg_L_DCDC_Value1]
BO_ 2416836624 Msg_L_DCDC_Value2: 8 L_BPCU_MCU
 SG_ L_TouChuan_DCDC_12_1U : 48|16@1+ (0.1,0) [0|6553.5] "V"  JiaShiCang
 SG_ L_TouChuan_DCDC_5_U : 32|16@1+ (0.1,0) [0|6553.5] "V"  JiaShiCang
 SG_ L_TouChuan_DCDC_270To28_U : 16|16@1+ (0.1,0) [0|6553.5] "V"  JiaShiCang
 SG_ L_TouChuan_DCDC_In_28U : 0|16@1+ (0.1,0) [0|6553.5] "V"  JiaShiCang

BO_ 2416771088 Msg_L_DCDC_Value1: 8 L_BPCU_MCU
 SG_ L_TouChuan_DCDC_T : 48|16@1+ (1,-55) [-55|65480] ""  JiaShiCang
 SG_ L_TouChuan_DCDC_Out_I : 32|16@1+ (0.1,0) [0|6553.5] "A"  JiaShiCang
 SG_ L_TouChuan_DCDC_Out_U : 16|16@1+ (0.1,0) [0|6553.5] "V"  JiaShiCang
 SG_ L_TouChuan_DCDC_In_U : 0|16@1+ (0.1,0) [0|6553.5] "V"  JiaShiCang

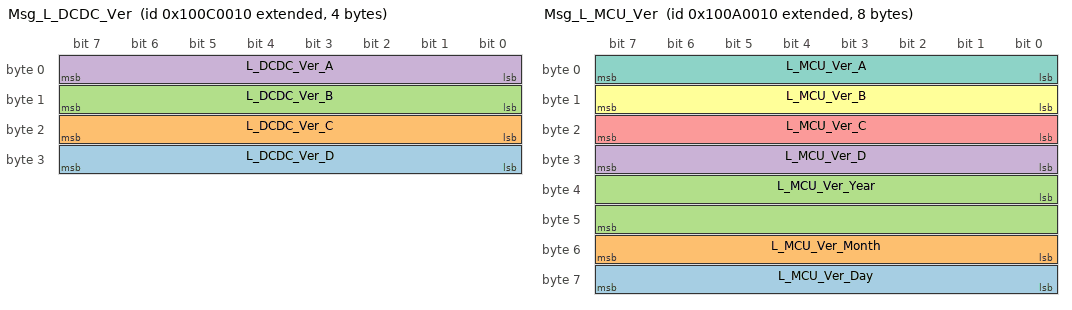
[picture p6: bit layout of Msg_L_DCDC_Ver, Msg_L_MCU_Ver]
BO_ 2416705552 Msg_L_DCDC_Ver: 4 L_BPCU_MCU
 SG_ L_DCDC_Ver_D : 24|8@1+ (1,0) [0|153] ""  JiaShiCang
 SG_ L_DCDC_Ver_C : 16|8@1+ (1,0) [0|153] ""  JiaShiCang
 SG_ L_DCDC_Ver_B : 8|8@1+ (1,0) [0|153] ""  JiaShiCang
 SG_ L_DCDC_Ver_A : 0|8@1+ (1,0) [0|153] ""  JiaShiCang

BO_ 2416574480 Msg_L_MCU_Ver: 8 L_BPCU_MCU
 SG_ L_MCU_Ver_Day : 56|8@1+ (1,0) [1|49] ""  JiaShiCang
 SG_ L_MCU_Ver_Month : 48|8@1+ (1,0) [1|18] ""  JiaShiCang
 SG_ L_MCU_Ver_Year : 32|16@1+ (1,0) [0|39321] ""  JiaShiCang
 SG_ L_MCU_Ver_D : 24|8@1+ (1,0) [0|153] ""  JiaShiCang
 SG_ L_MCU_Ver_C : 16|8@1+ (1,0) [0|153] ""  JiaShiCang
 SG_ L_MCU_Ver_B : 8|8@1+ (1,0) [0|153] ""  JiaShiCang
 SG_ L_MCU_Ver_A : 0|8@1+ (1,0) [0|153] ""  JiaShiCang

BO_ 2416508944 Msg_L_DuanLuQi_State: 7 L_BPCU_MCU
 SG_ BackUp006 : 49|7@1+ (1,0) [0|0] ""  JiaShiCang
 SG_ L_DuanLuQi_Sta_49 : 48|1@1+ (1,0) [0|1] ""  JiaShiCang
 SG_ L_DuanLuQi_Sta_48 : 47|1@1+ (1,0) [0|1] ""  JiaShiCang
 SG_ L_DuanLuQi_Sta_47 : 46|1@1+ (1,0) [0|1] ""  JiaShiCang
 SG_ L_DuanLuQi_Sta_46 : 45|1@1+ (1,0) [0|1] ""  JiaShiCang
 SG_ L_DuanLuQi_Sta_45 : 44|1@1+ (1,0) [0|1] ""  JiaShiCang
 SG_ L_DuanLuQi_Sta_44 : 43|1@1+ (1,0) [0|1] ""  JiaShiCang
 SG_ L_DuanLuQi_Sta_43 : 42|1@1+ (1,0) [0|1] ""  JiaShiCang
 SG_ L_DuanLuQi_Sta_42 : 41|1@1+ (1,0) [0|1] ""  JiaShiCang
 SG_ L_DuanLuQi_Sta_41 : 40|1@1+ (1,0) [0|1] ""  JiaShiCang
 SG_ L_DuanLuQi_Sta_40 : 39|1@1+ (1,0) [0|1] ""  JiaShiCang
 SG_ L_DuanLuQi_Sta_39 : 38|1@1+ (1,0) [0|1] ""  JiaShiCang
 SG_ L_DuanLuQi_Sta_38 : 37|1@1+ (1,0) [0|1] ""  JiaShiCang
 SG_ L_DuanLuQi_Sta_37 : 36|1@1+ (1,0) [0|1] ""  JiaShiCang
 SG_ L_DuanLuQi_Sta_36 : 35|1@1+ (1,0) [0|1] ""  JiaShiCang
 SG_ L_DuanLuQi_Sta_35 : 34|1@1+ (1,0) [0|1] ""  JiaShiCang
 SG_ L_DuanLuQi_Sta_34 : 33|1@1+ (1,0) [0|1] ""  JiaShiCang
 SG_ L_DuanLuQi_Sta_33 : 32|1@1+ (1,0) [0|1] ""  JiaShiCang
 SG_ L_DuanLuQi_Sta_32 : 31|1@1+ (1,0) [0|1] ""  JiaShiCang
 SG_ L_DuanLuQi_Sta_31 : 30|1@1+ (1,0) [0|1] ""  JiaShiCang
 SG_ L_DuanLuQi_Sta_30 : 29|1@1+ (1,0) [0|1] ""  JiaShiCang
 SG_ L_DuanLuQi_Sta_29 : 28|1@1+ (1,0) [0|1] ""  JiaShiCang
 SG_ L_DuanLuQi_Sta_28 : 27|1@1+ (1,0) [0|1] ""  JiaShiCang
 SG_ L_DuanLuQi_Sta_27 : 26|1@1+ (1,0) [0|1] ""  JiaShiCang
 SG_ L_DuanLuQi_Sta_26 : 25|1@1+ (1,0) [0|1] ""  JiaShiCang
 SG_ L_DuanLuQi_Sta_25 : 24|1@1+ (1,0) [0|1] ""  JiaShiCang
 SG_ L_DuanLuQi_Sta_24 : 23|1@1+ (1,0) [0|1] ""  JiaShiCang
 SG_ L_DuanLuQi_Sta_23 : 22|1@1+ (1,0) [0|1] ""  JiaShiCang
 SG_ L_DuanLuQi_Sta_22 : 21|1@1+ (1,0) [0|1] ""  JiaShiCang
 SG_ L_DuanLuQi_Sta_21 : 20|1@1+ (1,0) [0|1] ""  JiaShiCang
 SG_ L_DuanLuQi_Sta_20 : 19|1@1+ (1,0) [0|1] ""  JiaShiCang
 SG_ L_DuanLuQi_Sta_19 : 18|1@1+ (1,0) [0|1] ""  JiaShiCang
 SG_ L_DuanLuQi_Sta_18 : 17|1@1+ (1,0) [0|1] ""  JiaShiCang
 SG_ L_DuanLuQi_Sta_17 : 16|1@1+ (1,0) [0|1] ""  JiaShiCang
 SG_ L_DuanLuQi_Sta_16 : 15|1@1+ (1,0) [0|1] ""  JiaShiCang
 SG_ L_DuanLuQi_Sta_15 : 14|1@1+ (1,0) [0|1] ""  JiaShiCang
 SG_ L_DuanLuQi_Sta_14 : 13|1@1+ (1,0) [0|1] ""  JiaShiCang
 SG_ L_DuanLuQi_Sta_13 : 12|1@1+ (1,0) [0|1] ""  JiaShiCang
 SG_ L_DuanLuQi_Sta_12 : 11|1@1+ (1,0) [0|1] ""  JiaShiCang
 SG_ L_DuanLuQi_Sta_11 : 10|1@1+ (1,0) [0|1] ""  JiaShiCang
 SG_ L_DuanLuQi_Sta_10 : 9|1@1+ (1,0) [0|1] ""  JiaShiCang
 SG_ L_DuanLuQi_Sta_09 : 8|1@1+ (1,0) [0|1] ""  JiaShiCang
 SG_ L_DuanLuQi_Sta_08 : 7|1@1+ (1,0) [0|1] ""  JiaShiCang
 SG_ L_DuanLuQi_Sta_07 : 6|1@1+ (1,0) [0|1] ""  JiaShiCang
 SG_ L_DuanLuQi_Sta_06 : 5|1@1+ (1,0) [0|1] ""  JiaShiCang
 SG_ L_DuanLuQi_Sta_05 : 4|1@1+ (1,0) [0|1] ""  JiaShiCang
 SG_ L_DuanLuQi_Sta_04 : 3|1@1+ (1,0) [0|1] ""  JiaShiCang
 SG_ L_DuanLuQi_Sta_03 : 2|1@1+ (1,0) [0|1] ""  JiaShiCang
 SG_ L_DuanLuQi_Sta_02 : 1|1@1+ (1,0) [0|1] ""  JiaShiCang
 SG_ L_DuanLuQi_Sta_01 : 0|1@1+ (1,0) [0|1] ""  JiaShiCang

BO_ 2416443408 Msg_L_BIT_Msg: 8 L_BPCU_MCU
 SG_ BackUp005 : 39|1@1+ (1,0) [0|0] ""  JiaShiCang
 SG_ L_LE28IOver : 38|1@1+ (1,0) [0|1] ""  JiaShiCang
 SG_ L_LR28IOver : 37|1@1+ (1,0) [0|1] ""  JiaShiCang
 SG_ L_HLT281IOver : 36|1@1+ (1,0) [0|1] ""  JiaShiCang
 SG_ L_HLT282IOver : 35|1@1+ (1,0) [0|1] ""  JiaShiCang
 SG_ L_LE270IOver : 34|1@1+ (1,0) [0|1] ""  JiaShiCang
 SG_ L_LR270IOver : 33|1@1+ (1,0) [0|1] ""  JiaShiCang
 SG_ L_HLT270IOver : 32|1@1+ (1,0) [0|1] ""  JiaShiCang
 SG_ BackUp004 : 30|2@1+ (1,0) [0|0] ""  JiaShiCang
 SG_ L_HOTBBUSta : 28|2@1+ (1,0) [0|3] ""  JiaShiCang
 SG_ L_HLT281USta : 26|2@1+ (1,0) [0|3] ""  JiaShiCang
 SG_ L_HLT282USta : 24|2@1+ (1,0) [0|3] ""  JiaShiCang
 SG_ L_DCDC28OutUSta : 22|2@1+ (1,0) [0|3] ""  JiaShiCang
 SG_ L_DCDC270InUSta : 20|2@1+ (1,0) [0|3] ""  JiaShiCang
 SG_ L_HLT270USta : 18|2@1+ (1,0) [0|3] ""  JiaShiCang
 SG_ L_Batter270USta : 16|2@1+ (1,0) [0|3] ""  JiaShiCang
 SG_ BackUp003 : 11|5@1+ (1,0) [0|0] ""  JiaShiCang
 SG_ L_Heart_BIT : 10|1@1+ (1,0) [0|1] ""  JiaShiCang
 SG_ L_ZBUART_BIT : 9|1@1+ (1,0) [0|1] ""  JiaShiCang
 SG_ L_ADCIN_BIT : 8|1@1+ (1,0) [0|1] ""  JiaShiCang
 SG_ L_GpioIN_BIT : 7|1@1+ (1,0) [0|1] ""  JiaShiCang
 SG_ L_Flash_BIT : 6|1@1+ (1,0) [0|1] ""  JiaShiCang
 SG_ L_UART_BIT : 5|1@1+ (1,0) [0|1] ""  JiaShiCang
 SG_ L_IntCAN2_BIT : 4|1@1+ (1,0) [0|1] ""  JiaShiCang
 SG_ L_IntCAN1_BIT : 3|1@1+ (1,0) [0|1] ""  JiaShiCang
 SG_ L_ExtCAN_BIT : 2|1@1+ (1,0) [0|1] ""  JiaShiCang
 SG_ L_CPU_BIT : 1|1@1+ (1,0) [0|1] ""  JiaShiCang
 SG_ L_Pow_BIT : 0|1@1+ (1,0) [0|1] ""  JiaShiCang

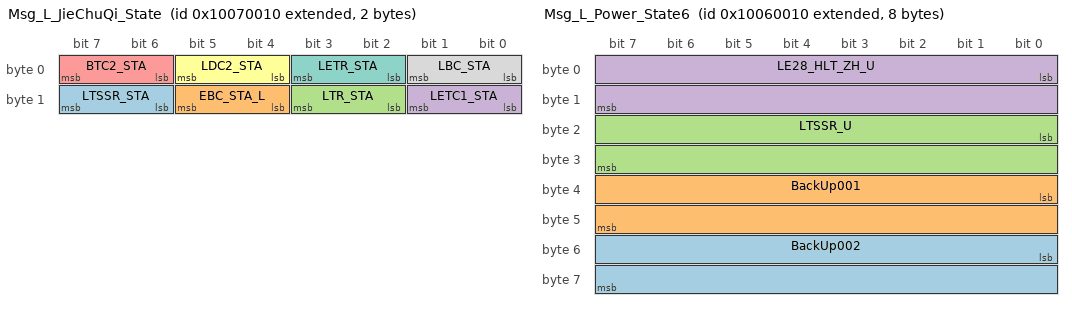
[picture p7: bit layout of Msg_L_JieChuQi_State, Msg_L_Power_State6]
BO_ 2416377872 Msg_L_JieChuQi_State: 2 L_BPCU_MCU
 SG_ LTSSR_STA : 14|2@1+ (1,0) [0|3] ""  JiaShiCang
 SG_ EBC_STA_L : 12|2@1+ (1,0) [0|3] ""  JiaShiCang
 SG_ LTR_STA : 10|2@1+ (1,0) [0|3] ""  JiaShiCang
 SG_ LETC1_STA : 8|2@1+ (1,0) [0|3] ""  JiaShiCang
 SG_ BTC2_STA : 6|2@1+ (1,0) [0|3] ""  JiaShiCang
 SG_ LDC2_STA : 4|2@1+ (1,0) [0|3] ""  JiaShiCang
 SG_ LETR_STA : 2|2@1+ (1,0) [0|3] ""  JiaShiCang
 SG_ LBC_STA : 0|2@1+ (1,0) [0|3] ""  JiaShiCang

BO_ 2416312336 Msg_L_Power_State6: 8 L_BPCU_MCU
 SG_ BackUp002 : 48|16@1+ (1,0) [0|0] ""  JiaShiCang
 SG_ BackUp001 : 32|16@1+ (1,0) [0|0] ""  JiaShiCang
 SG_ LTSSR_U : 16|16@1+ (0.1,0) [0|6553.5] "V"  JiaShiCang
 SG_ LE28_HLT_ZH_U : 0|16@1+ (0.1,0) [0|6553.5] "V"  JiaShiCang

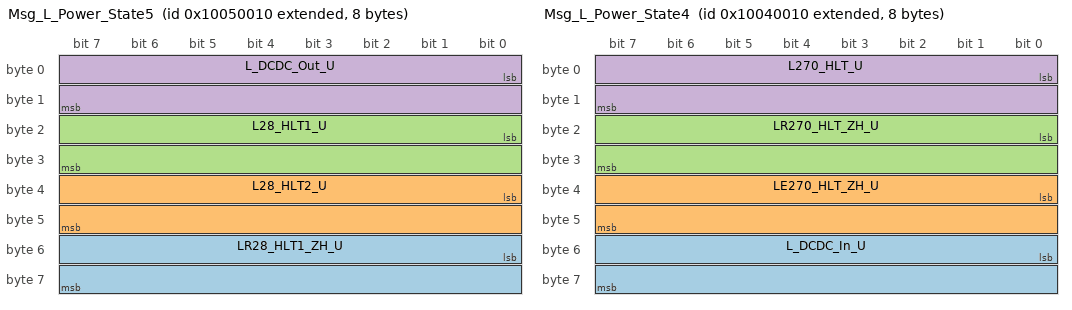
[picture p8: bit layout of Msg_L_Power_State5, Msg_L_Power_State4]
BO_ 2416246800 Msg_L_Power_State5: 8 L_BPCU_MCU
 SG_ LR28_HLT1_ZH_U : 48|16@1+ (0.1,0) [0|6553.5] "V"  JiaShiCang
 SG_ L28_HLT2_U : 32|16@1+ (0.1,0) [0|6553.5] "V"  JiaShiCang
 SG_ L28_HLT1_U : 16|16@1+ (0.1,0) [0|6553.5] "V"  JiaShiCang
 SG_ L_DCDC_Out_U : 0|16@1+ (0.1,0) [0|6553.5] "V"  JiaShiCang

BO_ 2416181264 Msg_L_Power_State4: 8 L_BPCU_MCU
 SG_ L_DCDC_In_U : 48|16@1+ (0.1,0) [0|6553.5] "V"  JiaShiCang
 SG_ LE270_HLT_ZH_U : 32|16@1+ (0.1,0) [0|6553.5] "V"  JiaShiCang
 SG_ LR270_HLT_ZH_U : 16|16@1+ (0.1,0) [0|6553.5] "V"  JiaShiCang
 SG_ L270_HLT_U : 0|16@1+ (0.1,0) [0|6553.5] "V"  JiaShiCang

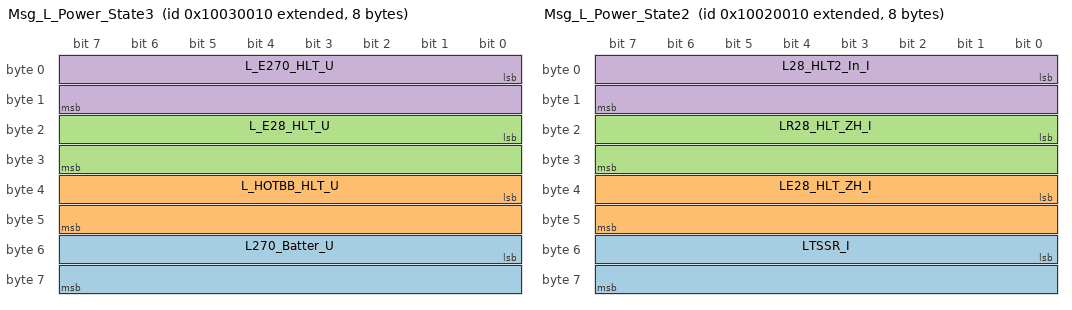
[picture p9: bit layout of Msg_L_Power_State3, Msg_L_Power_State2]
BO_ 2416115728 Msg_L_Power_State3: 8 L_BPCU_MCU
 SG_ L270_Batter_U : 48|16@1+ (0.1,0) [0|6553.5] "V"  JiaShiCang
 SG_ L_HOTBB_HLT_U : 32|16@1+ (0.1,0) [0|6553.5] "V"  JiaShiCang
 SG_ L_E28_HLT_U : 16|16@1+ (0.1,0) [0|6553.5] "V"  JiaShiCang
 SG_ L_E270_HLT_U : 0|16@1+ (0.1,0) [0|6553.5] "V"  JiaShiCang

BO_ 2416050192 Msg_L_Power_State2: 8 L_BPCU_MCU
 SG_ LTSSR_I : 48|16@1+ (0.1,0) [0|6553.5] "A"  JiaShiCang
 SG_ LE28_HLT_ZH_I : 32|16@1+ (0.1,0) [0|6553.5] "A"  JiaShiCang
 SG_ LR28_HLT_ZH_I : 16|16@1+ (0.1,0) [0|6553.5] "A"  JiaShiCang
 SG_ L28_HLT2_In_I : 0|16@1+ (0.1,0) [0|6553.5] "A"  JiaShiCang

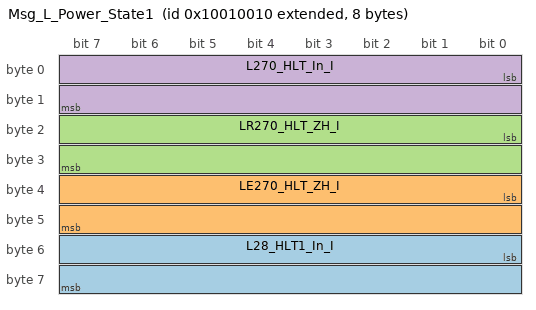
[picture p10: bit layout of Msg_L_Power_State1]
BO_ 2415984656 Msg_L_Power_State1: 8 L_BPCU_MCU
 SG_ L28_HLT1_In_I : 48|16@1+ (0.1,0) [0|6553.5] "A"  JiaShiCang
 SG_ LE270_HLT_ZH_I : 32|16@1+ (0.1,0) [0|6553.5] "A"  JiaShiCang
 SG_ LR270_HLT_ZH_I : 16|16@1+ (0.1,0) [0|6553.5] "A"  JiaShiCang
 SG_ L270_HLT_In_I : 0|16@1+ (0.1,0) [0|6553.5] "A"  JiaShiCang

CM_ SG_ 2419589136 BackUp184 "预留";
CM_ SG_ 2419589136 BackUp183 "预留";
CM_ SG_ 2419589136 BackUp182 "预留";
CM_ SG_ 2419589136 BackUp181 "预留";
CM_ SG_ 2419589136 RPDU3_B3_SSPC_I_Load_18 "SSPC18通道电流";
CM_ SG_ 2419589136 RPDU3_B3_SSPC_TripSta_18 "SSPC18跳闸状态";
CM_ SG_ 2419589136 RPDU3_B3_SSPC_BitErr_18 "SSPC18通断周期自检状态";
CM_ SG_ 2419589136 RPDU3_B3_SSPC_OnOffSta_18 "SSPC18通断状态";
CM_ SG_ 2419589136 RPDU3_B3_SSPC_DianHuErr_18 "SSPC18电弧故障状态";
CM_ SG_ 2419589136 BackUp180 "预留";
CM_ SG_ 2419589136 RPDU3_B3_SSPC_I_Load_17 "SSPC17通道电流";
CM_ SG_ 2419589136 RPDU3_B3_SSPC_TripSta_17 "SSPC17跳闸状态";
CM_ SG_ 2419589136 RPDU3_B3_SSPC_BitErr_17 "SSPC17通断周期自检状态";
CM_ SG_ 2419589136 RPDU3_B3_SSPC_OnOffSta_17 "SSPC17通断状态";
CM_ SG_ 2419589136 RPDU3_B3_SSPC_DianHuErr_17 "SSPC17电弧故障状态";
CM_ SG_ 2419589136 BackUp179 "预留";
CM_ SG_ 2419523600 RPDU3_B3_SSPC_I_Load_16 "SSPC16通道电流";
CM_ SG_ 2419523600 RPDU3_B3_SSPC_TripSta_16 "SSPC16跳闸状态";
CM_ SG_ 2419523600 RPDU3_B3_SSPC_BitErr_16 "SSPC16通断周期自检状态";
CM_ SG_ 2419523600 RPDU3_B3_SSPC_OnOffSta_16 "SSPC16通断状态";
CM_ SG_ 2419523600 RPDU3_B3_SSPC_DianHuErr_16 "SSPC16电弧故障状态";
CM_ SG_ 2419523600 BackUp178 "预留";
CM_ SG_ 2419523600 RPDU3_B3_SSPC_I_Load_15 "SSPC15通道电流";
CM_ SG_ 2419523600 RPDU3_B3_SSPC_TripSta_15 "SSPC15跳闸状态";
CM_ SG_ 2419523600 RPDU3_B3_SSPC_BitErr_15 "SSPC15通断周期自检状态";
CM_ SG_ 2419523600 RPDU3_B3_SSPC_OnOffSta_15 "SSPC15通断状态";
CM_ SG_ 2419523600 RPDU3_B3_SSPC_DianHuErr_15 "SSPC15电弧故障状态";
CM_ SG_ 2419523600 BackUp177 "预留";
CM_ SG_ 2419523600 RPDU3_B3_SSPC_I_Load_14 "SSPC14通道电流";
CM_ SG_ 2419523600 RPDU3_B3_SSPC_TripSta_14 "SSPC14跳闸状态";
CM_ SG_ 2419523600 RPDU3_B3_SSPC_BitErr_14 "SSPC14通断周期自检状态";
CM_ SG_ 2419523600 RPDU3_B3_SSPC_OnOffSta_14 "SSPC14通断状态";
CM_ SG_ 2419523600 RPDU3_B3_SSPC_DianHuErr_14 "SSPC14电弧故障状态";
CM_ SG_ 2419523600 BackUp176 "预留";
CM_ SG_ 2419523600 RPDU3_B3_SSPC_I_Load_13 "SSPC13通道电流";
CM_ SG_ 2419523600 RPDU3_B3_SSPC_TripSta_13 "SSPC13跳闸状态";
CM_ SG_ 2419523600 RPDU3_B3_SSPC_BitErr_13 "SSPC13通断周期自检状态";
CM_ SG_ 2419523600 RPDU3_B3_SSPC_OnOffSta_13 "SSPC13通断状态";
CM_ SG_ 2419523600 RPDU3_B3_SSPC_DianHuErr_13 "SSPC13电弧故障状态";
CM_ SG_ 2419523600 BackUp175 "预留";
CM_ SG_ 2419458064 RPDU3_B3_SSPC_I_Load_12 "SSPC12通道电流";
CM_ SG_ 2419458064 RPDU3_B3_SSPC_TripSta_12 "SSPC12跳闸状态";
CM_ SG_ 2419458064 RPDU3_B3_SSPC_BitErr_12 "SSPC12通断周期自检状态";
CM_ SG_ 2419458064 RPDU3_B3_SSPC_OnOffSta_12 "SSPC12通断状态";
CM_ SG_ 2419458064 RPDU3_B3_SSPC_DianHuErr_12 "SSPC12电弧故障状态";
CM_ SG_ 2419458064 BackUp174 "预留";
CM_ SG_ 2419458064 RPDU3_B3_SSPC_I_Load_11 "SSPC11通道电流";
CM_ SG_ 2419458064 RPDU3_B3_SSPC_TripSta_11 "SSPC11跳闸状态";
CM_ SG_ 2419458064 RPDU3_B3_SSPC_BitErr_11 "SSPC11通断周期自检状态";
CM_ SG_ 2419458064 RPDU3_B3_SSPC_OnOffSta_11 "SSPC11通断状态";
CM_ SG_ 2419458064 RPDU3_B3_SSPC_DianHuErr_11 "SSPC11电弧故障状态";
CM_ SG_ 2419458064 BackUp173 "预留";
CM_ SG_ 2419458064 RPDU3_B3_SSPC_I_Load_10 "SSPC10通道电流";
CM_ SG_ 2419458064 RPDU3_B3_SSPC_TripSta_10 "SSPC10跳闸状态";
CM_ SG_ 2419458064 RPDU3_B3_SSPC_BitErr_10 "SSPC10通断周期自检状态";
CM_ SG_ 2419458064 RPDU3_B3_SSPC_OnOffSta_10 "SSPC10通断状态";
CM_ SG_ 2419458064 RPDU3_B3_SSPC_DianHuErr_10 "SSPC10电弧故障状态";
CM_ SG_ 2419458064 BackUp172 "预留";
CM_ SG_ 2419458064 RPDU3_B3_SSPC_I_Load_09 "SSPC9通道电流";
CM_ SG_ 2419458064 RPDU3_B3_SSPC_TripSta_09 "SSPC9跳闸状态";
CM_ SG_ 2419458064 RPDU3_B3_SSPC_BitErr_09 "SSPC9通断周期自检状态";
CM_ SG_ 2419458064 RPDU3_B3_SSPC_OnOffSta_09 "SSPC9通断状态";
CM_ SG_ 2419458064 RPDU3_B3_SSPC_DianHuErr_09 "SSPC9电弧故障状态";
CM_ SG_ 2419458064 BackUp171 "预留";
CM_ SG_ 2419392528 RPDU3_B3_SSPC_I_Load_08 "SSPC8通道电流";
CM_ SG_ 2419392528 RPDU3_B3_SSPC_TripSta_08 "SSPC8跳闸状态";
CM_ SG_ 2419392528 RPDU3_B3_SSPC_BitErr_08 "SSPC8通断周期自检状态";
CM_ SG_ 2419392528 RPDU3_B3_SSPC_OnOffSta_08 "SSPC8通断状态";
CM_ SG_ 2419392528 RPDU3_B3_SSPC_DianHuErr_08 "SSPC8电弧故障状态";
CM_ SG_ 2419392528 BackUp170 "预留";
CM_ SG_ 2419392528 RPDU3_B3_SSPC_I_Load_07 "SSPC7通道电流";
CM_ SG_ 2419392528 RPDU3_B3_SSPC_TripSta_07 "SSPC7跳闸状态";
CM_ SG_ 2419392528 RPDU3_B3_SSPC_BitErr_07 "SSPC7通断周期自检状态";
CM_ SG_ 2419392528 RPDU3_B3_SSPC_OnOffSta_07 "SSPC7通断状态";
CM_ SG_ 2419392528 RPDU3_B3_SSPC_DianHuErr_07 "SSPC7电弧故障状态";
CM_ SG_ 2419392528 BackUp169 "预留";
CM_ SG_ 2419392528 RPDU3_B3_SSPC_I_Load_06 "SSPC6通道电流";
CM_ SG_ 2419392528 RPDU3_B3_SSPC_TripSta_06 "SSPC6跳闸状态";
CM_ SG_ 2419392528 RPDU3_B3_SSPC_BitErr_06 "SSPC6通断周期自检状态";
CM_ SG_ 2419392528 RPDU3_B3_SSPC_OnOffSta_06 "SSPC6通断状态";
CM_ SG_ 2419392528 RPDU3_B3_SSPC_DianHuErr_06 "SSPC6电弧故障状态";
CM_ SG_ 2419392528 BackUp168 "预留";
CM_ SG_ 2419392528 RPDU3_B3_SSPC_I_Load_05 "SSPC5通道电流";
CM_ SG_ 2419392528 RPDU3_B3_SSPC_TripSta_05 "SSPC5跳闸状态";
CM_ SG_ 2419392528 RPDU3_B3_SSPC_BitErr_05 "SSPC5通断周期自检状态";
CM_ SG_ 2419392528 RPDU3_B3_SSPC_OnOffSta_05 "SSPC5通断状态";
CM_ SG_ 2419392528 RPDU3_B3_SSPC_DianHuErr_05 "SSPC5电弧故障状态";
CM_ SG_ 2419392528 BackUp167 "预留";
CM_ SG_ 2419326992 RPDU3_B3_SSPC_I_Load_04 "SSPC4通道电流";
CM_ SG_ 2419326992 RPDU3_B3_SSPC_TripSta_04 "SSPC4跳闸状态";
CM_ SG_ 2419326992 RPDU3_B3_SSPC_BitErr_04 "SSPC4通断周期自检状态";
CM_ SG_ 2419326992 RPDU3_B3_SSPC_OnOffSta_04 "SSPC4通断状态";
CM_ SG_ 2419326992 RPDU3_B3_SSPC_DianHuErr_04 "SSPC4电弧故障状态";
CM_ SG_ 2419326992 BackUp166 "预留";
CM_ SG_ 2419326992 RPDU3_B3_SSPC_I_Load_03 "SSPC3通道电流";
CM_ SG_ 2419326992 RPDU3_B3_SSPC_TripSta_03 "SSPC3跳闸状态";
CM_ SG_ 2419326992 RPDU3_B3_SSPC_BitErr_03 "SSPC3通断周期自检状态";
CM_ SG_ 2419326992 RPDU3_B3_SSPC_OnOffSta_03 "SSPC3通断状态";
CM_ SG_ 2419326992 RPDU3_B3_SSPC_DianHuErr_03 "SSPC3电弧故障状态";
CM_ SG_ 2419326992 BackUp165 "预留";
CM_ SG_ 2419326992 RPDU3_B3_SSPC_I_Load_02 "SSPC2通道电流";
CM_ SG_ 2419326992 RPDU3_B3_SSPC_TripSta_02 "SSPC2跳闸状态";
CM_ SG_ 2419326992 RPDU3_B3_SSPC_BitErr_02 "SSPC2通断周期自检状态";
CM_ SG_ 2419326992 RPDU3_B3_SSPC_OnOffSta_02 "SSPC2通断状态";
CM_ SG_ 2419326992 RPDU3_B3_SSPC_DianHuErr_02 "SSPC2电弧故障状态";
CM_ SG_ 2419326992 BackUp164 "预留";
CM_ SG_ 2419326992 RPDU3_B3_SSPC_I_Load_01 "SSPC1通道电流";
CM_ SG_ 2419326992 RPDU3_B3_SSPC_TripSta_01 "SSPC1跳闸状态";
CM_ SG_ 2419326992 RPDU3_B3_SSPC_BitErr_01 "SSPC1通断周期自检状态";
CM_ SG_ 2419326992 RPDU3_B3_SSPC_OnOffSta_01 "SSPC1通断状态";
CM_ SG_ 2419326992 RPDU3_B3_SSPC_DianHuErr_01 "SSPC1电弧故障状态";
CM_ SG_ 2419326992 BackUp163 "预留";
CM_ SG_ 2419261456 BackUp162 "预留";
CM_ SG_ 2419261456 BackUp161 "预留";
CM_ SG_ 2419261456 BackUp160 "预留";
CM_ SG_ 2419261456 BackUp159 "预留";
CM_ SG_ 2419261456 RPDU3_B2_SSPC_I_Load_18 "SSPC18通道电流";
CM_ SG_ 2419261456 RPDU3_B2_SSPC_TripSta_18 "SSPC18跳闸状态";
CM_ SG_ 2419261456 RPDU3_B2_SSPC_BitErr_18 "SSPC18通断周期自检状态";
CM_ SG_ 2419261456 RPDU3_B2_SSPC_OnOffSta_18 "SSPC18通断状态";
CM_ SG_ 2419261456 RPDU3_B2_SSPC_DianHuErr_18 "SSPC18电弧故障状态";
CM_ SG_ 2419261456 BackUp158 "预留";
CM_ SG_ 2419261456 RPDU3_B2_SSPC_I_Load_17 "SSPC17通道电流";
CM_ SG_ 2419261456 RPDU3_B2_SSPC_TripSta_17 "SSPC17跳闸状态";
CM_ SG_ 2419261456 RPDU3_B2_SSPC_BitErr_17 "SSPC17通断周期自检状态";
CM_ SG_ 2419261456 RPDU3_B2_SSPC_OnOffSta_17 "SSPC17通断状态";
CM_ SG_ 2419261456 RPDU3_B2_SSPC_DianHuErr_17 "SSPC17电弧故障状态";
CM_ SG_ 2419261456 BackUp157 "预留";
CM_ SG_ 2419195920 RPDU3_B2_SSPC_I_Load_16 "SSPC16通道电流";
CM_ SG_ 2419195920 RPDU3_B2_SSPC_TripSta_16 "SSPC16跳闸状态";
CM_ SG_ 2419195920 RPDU3_B2_SSPC_BitErr_16 "SSPC16通断周期自检状态";
CM_ SG_ 2419195920 RPDU3_B2_SSPC_OnOffSta_16 "SSPC16通断状态";
CM_ SG_ 2419195920 RPDU3_B2_SSPC_DianHuErr_16 "SSPC16电弧故障状态";
CM_ SG_ 2419195920 BackUp156 "预留";
CM_ SG_ 2419195920 RPDU3_B2_SSPC_I_Load_15 "SSPC15通道电流";
CM_ SG_ 2419195920 RPDU3_B2_SSPC_TripSta_15 "SSPC15跳闸状态";
CM_ SG_ 2419195920 RPDU3_B2_SSPC_BitErr_15 "SSPC15通断周期自检状态";
CM_ SG_ 2419195920 RPDU3_B2_SSPC_OnOffSta_15 "SSPC15通断状态";
CM_ SG_ 2419195920 RPDU3_B2_SSPC_DianHuErr_15 "SSPC15电弧故障状态";
CM_ SG_ 2419195920 BackUp155 "预留";
CM_ SG_ 2419195920 RPDU3_B2_SSPC_I_Load_14 "SSPC14通道电流";
CM_ SG_ 2419195920 RPDU3_B2_SSPC_TripSta_14 "SSPC14跳闸状态";
CM_ SG_ 2419195920 RPDU3_B2_SSPC_BitErr_14 "SSPC14通断周期自检状态";
CM_ SG_ 2419195920 RPDU3_B2_SSPC_OnOffSta_14 "SSPC14通断状态";
CM_ SG_ 2419195920 RPDU3_B2_SSPC_DianHuErr_14 "SSPC14电弧故障状态";
CM_ SG_ 2419195920 BackUp154 "预留";
CM_ SG_ 2419195920 RPDU3_B2_SSPC_I_Load_13 "SSPC13通道电流";
CM_ SG_ 2419195920 RPDU3_B2_SSPC_TripSta_13 "SSPC13跳闸状态";
CM_ SG_ 2419195920 RPDU3_B2_SSPC_BitErr_13 "SSPC13通断周期自检状态";
CM_ SG_ 2419195920 RPDU3_B2_SSPC_OnOffSta_13 "SSPC13通断状态";
CM_ SG_ 2419195920 RPDU3_B2_SSPC_DianHuErr_13 "SSPC13电弧故障状态";
CM_ SG_ 2419195920 BackUp153 "预留";
CM_ SG_ 2419130384 RPDU3_B2_SSPC_I_Load_12 "SSPC12通道电流";
CM_ SG_ 2419130384 RPDU3_B2_SSPC_TripSta_12 "SSPC12跳闸状态";
CM_ SG_ 2419130384 RPDU3_B2_SSPC_BitErr_12 "SSPC12通断周期自检状态";
CM_ SG_ 2419130384 RPDU3_B2_SSPC_OnOffSta_12 "SSPC12通断状态";
CM_ SG_ 2419130384 RPDU3_B2_SSPC_DianHuErr_12 "SSPC12电弧故障状态";
CM_ SG_ 2419130384 BackUp152 "预留";
CM_ SG_ 2419130384 RPDU3_B2_SSPC_I_Load_11 "SSPC11通道电流";
CM_ SG_ 2419130384 RPDU3_B2_SSPC_TripSta_11 "SSPC11跳闸状态";
CM_ SG_ 2419130384 RPDU3_B2_SSPC_BitErr_11 "SSPC11通断周期自检状态";
CM_ SG_ 2419130384 RPDU3_B2_SSPC_OnOffSta_11 "SSPC11通断状态";
CM_ SG_ 2419130384 RPDU3_B2_SSPC_DianHuErr_11 "SSPC11电弧故障状态";
CM_ SG_ 2419130384 BackUp151 "预留";
CM_ SG_ 2419130384 RPDU3_B2_SSPC_I_Load_10 "SSPC10通道电流";
CM_ SG_ 2419130384 RPDU3_B2_SSPC_TripSta_10 "SSPC10跳闸状态";
CM_ SG_ 2419130384 RPDU3_B2_SSPC_BitErr_10 "SSPC10通断周期自检状态";
CM_ SG_ 2419130384 RPDU3_B2_SSPC_OnOffSta_10 "SSPC10通断状态";
CM_ SG_ 2419130384 RPDU3_B2_SSPC_DianHuErr_10 "SSPC10电弧故障状态";
CM_ SG_ 2419130384 BackUp150 "预留";
CM_ SG_ 2419130384 RPDU3_B2_SSPC_I_Load_09 "SSPC9通道电流";
CM_ SG_ 2419130384 RPDU3_B2_SSPC_TripSta_09 "SSPC9跳闸状态";
CM_ SG_ 2419130384 RPDU3_B2_SSPC_BitErr_09 "SSPC9通断周期自检状态";
CM_ SG_ 2419130384 RPDU3_B2_SSPC_OnOffSta_09 "SSPC9通断状态";
CM_ SG_ 2419130384 RPDU3_B2_SSPC_DianHuErr_09 "SSPC9电弧故障状态";
CM_ SG_ 2419130384 BackUp149 "预留";
CM_ SG_ 2419064848 RPDU3_B2_SSPC_I_Load_08 "SSPC8通道电流";
CM_ SG_ 2419064848 RPDU3_B2_SSPC_TripSta_08 "SSPC8跳闸状态";
CM_ SG_ 2419064848 RPDU3_B2_SSPC_BitErr_08 "SSPC8通断周期自检状态";
CM_ SG_ 2419064848 RPDU3_B2_SSPC_OnOffSta_08 "SSPC8通断状态";
CM_ SG_ 2419064848 RPDU3_B2_SSPC_DianHuErr_08 "SSPC8电弧故障状态";
CM_ SG_ 2419064848 BackUp148 "预留";
CM_ SG_ 2419064848 RPDU3_B2_SSPC_I_Load_07 "SSPC7通道电流";
CM_ SG_ 2419064848 RPDU3_B2_SSPC_TripSta_07 "SSPC7跳闸状态";
CM_ SG_ 2419064848 RPDU3_B2_SSPC_BitErr_07 "SSPC7通断周期自检状态";
CM_ SG_ 2419064848 RPDU3_B2_SSPC_OnOffSta_07 "SSPC7通断状态";
CM_ SG_ 2419064848 RPDU3_B2_SSPC_DianHuErr_07 "SSPC7电弧故障状态";
CM_ SG_ 2419064848 BackUp147 "预留";
CM_ SG_ 2419064848 RPDU3_B2_SSPC_I_Load_06 "SSPC6通道电流";
CM_ SG_ 2419064848 RPDU3_B2_SSPC_TripSta_06 "SSPC6跳闸状态";
CM_ SG_ 2419064848 RPDU3_B2_SSPC_BitErr_06 "SSPC6通断周期自检状态";
CM_ SG_ 2419064848 RPDU3_B2_SSPC_OnOffSta_06 "SSPC6通断状态";
CM_ SG_ 2419064848 RPDU3_B2_SSPC_DianHuErr_06 "SSPC6电弧故障状态";
CM_ SG_ 2419064848 BackUp146 "预留";
CM_ SG_ 2419064848 RPDU3_B2_SSPC_I_Load_05 "SSPC5通道电流";
CM_ SG_ 2419064848 RPDU3_B2_SSPC_TripSta_05 "SSPC5跳闸状态";
CM_ SG_ 2419064848 RPDU3_B2_SSPC_BitErr_05 "SSPC5通断周期自检状态";
CM_ SG_ 2419064848 RPDU3_B2_SSPC_OnOffSta_05 "SSPC5通断状态";
CM_ SG_ 2419064848 RPDU3_B2_SSPC_DianHuErr_05 "SSPC5电弧故障状态";
CM_ SG_ 2419064848 BackUp145 "预留";
CM_ SG_ 2418999312 RPDU3_B2_SSPC_I_Load_04 "SSPC4通道电流";
CM_ SG_ 2418999312 RPDU3_B2_SSPC_TripSta_04 "SSPC4跳闸状态";
CM_ SG_ 2418999312 RPDU3_B2_SSPC_BitErr_04 "SSPC4通断周期自检状态";
CM_ SG_ 2418999312 RPDU3_B2_SSPC_OnOffSta_04 "SSPC4通断状态";
CM_ SG_ 2418999312 RPDU3_B2_SSPC_DianHuErr_04 "SSPC4电弧故障状态";
CM_ SG_ 2418999312 BackUp144 "预留";
CM_ SG_ 2418999312 RPDU3_B2_SSPC_I_Load_03 "SSPC3通道电流";
CM_ SG_ 2418999312 RPDU3_B2_SSPC_TripSta_03 "SSPC3跳闸状态";
CM_ SG_ 2418999312 RPDU3_B2_SSPC_BitErr_03 "SSPC3通断周期自检状态";
CM_ SG_ 2418999312 RPDU3_B2_SSPC_OnOffSta_03 "SSPC3通断状态";
CM_ SG_ 2418999312 RPDU3_B2_SSPC_DianHuErr_03 "SSPC3电弧故障状态";
CM_ SG_ 2418999312 BackUp143 "预留";
CM_ SG_ 2418999312 RPDU3_B2_SSPC_I_Load_02 "SSPC2通道电流";
CM_ SG_ 2418999312 RPDU3_B2_SSPC_TripSta_02 "SSPC2跳闸状态";
CM_ SG_ 2418999312 RPDU3_B2_SSPC_BitErr_02 "SSPC2通断周期自检状态";
CM_ SG_ 2418999312 RPDU3_B2_SSPC_OnOffSta_02 "SSPC2通断状态";
CM_ SG_ 2418999312 RPDU3_B2_SSPC_DianHuErr_02 "SSPC2电弧故障状态";
CM_ SG_ 2418999312 BackUp142 "预留";
CM_ SG_ 2418999312 RPDU3_B2_SSPC_I_Load_01 "SSPC1通道电流";
CM_ SG_ 2418999312 RPDU3_B2_SSPC_TripSta_01 "SSPC1跳闸状态";
CM_ SG_ 2418999312 RPDU3_B2_SSPC_BitErr_01 "SSPC1通断周期自检状态";
CM_ SG_ 2418999312 RPDU3_B2_SSPC_OnOffSta_01 "SSPC1通断状态";
CM_ SG_ 2418999312 RPDU3_B2_SSPC_DianHuErr_01 "SSPC1电弧故障状态";
CM_ SG_ 2418999312 BackUp141 "预留";
CM_ SG_ 2418933776 BackUp140 "预留";
CM_ SG_ 2418933776 BackUp139 "预留";
CM_ SG_ 2418933776 BackUp138 "预留";
CM_ SG_ 2418933776 BackUp137 "预留";
CM_ SG_ 2418933776 RPDU3_B1_SSPC_I_Load_18 "SSPC18通道电流";
CM_ SG_ 2418933776 RPDU3_B1_SSPC_TripSta_18 "SSPC18跳闸状态";
CM_ SG_ 2418933776 RPDU3_B1_SSPC_BitErr_18 "SSPC18通断周期自检状态";
CM_ SG_ 2418933776 RPDU3_B1_SSPC_OnOffSta_18 "SSPC18通断状态";
CM_ SG_ 2418933776 RPDU3_B1_SSPC_DianHuErr_18 "SSPC18电弧故障状态";
CM_ SG_ 2418933776 BackUp136 "预留";
CM_ SG_ 2418933776 RPDU3_B1_SSPC_I_Load_17 "SSPC17通道电流";
CM_ SG_ 2418933776 RPDU3_B1_SSPC_TripSta_17 "SSPC17跳闸状态";
CM_ SG_ 2418933776 RPDU3_B1_SSPC_BitErr_17 "SSPC17通断周期自检状态";
CM_ SG_ 2418933776 RPDU3_B1_SSPC_OnOffSta_17 "SSPC17通断状态";
CM_ SG_ 2418933776 RPDU3_B1_SSPC_DianHuErr_17 "SSPC17电弧故障状态";
CM_ SG_ 2418933776 BackUp135 "预留";
CM_ SG_ 2418868240 RPDU3_B1_SSPC_I_Load_16 "SSPC16通道电流";
CM_ SG_ 2418868240 RPDU3_B1_SSPC_TripSta_16 "SSPC16跳闸状态";
CM_ SG_ 2418868240 RPDU3_B1_SSPC_BitErr_16 "SSPC16通断周期自检状态";
CM_ SG_ 2418868240 RPDU3_B1_SSPC_OnOffSta_16 "SSPC16通断状态";
CM_ SG_ 2418868240 RPDU3_B1_SSPC_DianHuErr_16 "SSPC16电弧故障状态";
CM_ SG_ 2418868240 BackUp134 "预留";
CM_ SG_ 2418868240 RPDU3_B1_SSPC_I_Load_15 "SSPC15通道电流";
CM_ SG_ 2418868240 RPDU3_B1_SSPC_TripSta_15 "SSPC15跳闸状态";
CM_ SG_ 2418868240 RPDU3_B1_SSPC_BitErr_15 "SSPC15通断周期自检状态";
CM_ SG_ 2418868240 RPDU3_B1_SSPC_OnOffSta_15 "SSPC15通断状态";
CM_ SG_ 2418868240 RPDU3_B1_SSPC_DianHuErr_15 "SSPC15电弧故障状态";
CM_ SG_ 2418868240 BackUp133 "预留";
CM_ SG_ 2418868240 RPDU3_B1_SSPC_I_Load_14 "SSPC14通道电流";
CM_ SG_ 2418868240 RPDU3_B1_SSPC_TripSta_14 "SSPC14跳闸状态";
CM_ SG_ 2418868240 RPDU3_B1_SSPC_BitErr_14 "SSPC14通断周期自检状态";
CM_ SG_ 2418868240 RPDU3_B1_SSPC_OnOffSta_14 "SSPC14通断状态";
CM_ SG_ 2418868240 RPDU3_B1_SSPC_DianHuErr_14 "SSPC14电弧故障状态";
CM_ SG_ 2418868240 BackUp132 "预留";
CM_ SG_ 2418868240 RPDU3_B1_SSPC_I_Load_13 "SSPC13通道电流";
CM_ SG_ 2418868240 RPDU3_B1_SSPC_TripSta_13 "SSPC13跳闸状态";
CM_ SG_ 2418868240 RPDU3_B1_SSPC_BitErr_13 "SSPC13通断周期自检状态";
CM_ SG_ 2418868240 RPDU3_B1_SSPC_OnOffSta_13 "SSPC13通断状态";
CM_ SG_ 2418868240 RPDU3_B1_SSPC_DianHuErr_13 "SSPC13电弧故障状态";
CM_ SG_ 2418868240 BackUp131 "预留";
CM_ SG_ 2418802704 RPDU3_B1_SSPC_I_Load_12 "SSPC12通道电流";
CM_ SG_ 2418802704 RPDU3_B1_SSPC_TripSta_12 "SSPC12跳闸状态";
CM_ SG_ 2418802704 RPDU3_B1_SSPC_BitErr_12 "SSPC12通断周期自检状态";
CM_ SG_ 2418802704 RPDU3_B1_SSPC_OnOffSta_12 "SSPC12通断状态";
CM_ SG_ 2418802704 RPDU3_B1_SSPC_DianHuErr_12 "SSPC12电弧故障状态";
CM_ SG_ 2418802704 BackUp130 "预留";
CM_ SG_ 2418802704 RPDU3_B1_SSPC_I_Load_11 "SSPC11通道电流";
CM_ SG_ 2418802704 RPDU3_B1_SSPC_TripSta_11 "SSPC11跳闸状态";
CM_ SG_ 2418802704 RPDU3_B1_SSPC_BitErr_11 "SSPC11通断周期自检状态";
CM_ SG_ 2418802704 RPDU3_B1_SSPC_OnOffSta_11 "SSPC11通断状态";
CM_ SG_ 2418802704 RPDU3_B1_SSPC_DianHuErr_11 "SSPC11电弧故障状态";
CM_ SG_ 2418802704 BackUp129 "预留";
CM_ SG_ 2418802704 RPDU3_B1_SSPC_I_Load_10 "SSPC10通道电流";
CM_ SG_ 2418802704 RPDU3_B1_SSPC_TripSta_10 "SSPC10跳闸状态";
CM_ SG_ 2418802704 RPDU3_B1_SSPC_BitErr_10 "SSPC10通断周期自检状态";
CM_ SG_ 2418802704 RPDU3_B1_SSPC_OnOffSta_10 "SSPC10通断状态";
CM_ SG_ 2418802704 RPDU3_B1_SSPC_DianHuErr_10 "SSPC10电弧故障状态";
CM_ SG_ 2418802704 BackUp128 "预留";
CM_ SG_ 2418802704 RPDU3_B1_SSPC_I_Load_09 "SSPC9通道电流";
CM_ SG_ 2418802704 RPDU3_B1_SSPC_TripSta_09 "SSPC9跳闸状态";
CM_ SG_ 2418802704 RPDU3_B1_SSPC_BitErr_09 "SSPC9通断周期自检状态";
CM_ SG_ 2418802704 RPDU3_B1_SSPC_OnOffSta_09 "SSPC9通断状态";
CM_ SG_ 2418802704 RPDU3_B1_SSPC_DianHuErr_09 "SSPC9电弧故障状态";
CM_ SG_ 2418802704 BackUp127 "预留";
CM_ SG_ 2418737168 RPDU3_B1_SSPC_I_Load_08 "SSPC8通道电流";
CM_ SG_ 2418737168 RPDU3_B1_SSPC_TripSta_08 "SSPC8跳闸状态";
CM_ SG_ 2418737168 RPDU3_B1_SSPC_BitErr_08 "SSPC8通断周期自检状态";
CM_ SG_ 2418737168 RPDU3_B1_SSPC_OnOffSta_08 "SSPC8通断状态";
CM_ SG_ 2418737168 RPDU3_B1_SSPC_DianHuErr_08 "SSPC8电弧故障状态";
CM_ SG_ 2418737168 BackUp126 "预留";
CM_ SG_ 2418737168 RPDU3_B1_SSPC_I_Load_07 "SSPC7通道电流";
CM_ SG_ 2418737168 RPDU3_B1_SSPC_TripSta_07 "SSPC7跳闸状态";
CM_ SG_ 2418737168 RPDU3_B1_SSPC_BitErr_07 "SSPC7通断周期自检状态";
CM_ SG_ 2418737168 RPDU3_B1_SSPC_OnOffSta_07 "SSPC7通断状态";
CM_ SG_ 2418737168 RPDU3_B1_SSPC_DianHuErr_07 "SSPC7电弧故障状态";
CM_ SG_ 2418737168 BackUp125 "预留";
CM_ SG_ 2418737168 RPDU3_B1_SSPC_I_Load_06 "SSPC6通道电流";
CM_ SG_ 2418737168 RPDU3_B1_SSPC_TripSta_06 "SSPC6跳闸状态";
CM_ SG_ 2418737168 RPDU3_B1_SSPC_BitErr_06 "SSPC6通断周期自检状态";
CM_ SG_ 2418737168 RPDU3_B1_SSPC_OnOffSta_06 "SSPC6通断状态";
CM_ SG_ 2418737168 RPDU3_B1_SSPC_DianHuErr_06 "SSPC6电弧故障状态";
CM_ SG_ 2418737168 BackUp124 "预留";
CM_ SG_ 2418737168 RPDU3_B1_SSPC_I_Load_05 "SSPC5通道电流";
CM_ SG_ 2418737168 RPDU3_B1_SSPC_TripSta_05 "SSPC5跳闸状态";
CM_ SG_ 2418737168 RPDU3_B1_SSPC_BitErr_05 "SSPC5通断周期自检状态";
CM_ SG_ 2418737168 RPDU3_B1_SSPC_OnOffSta_05 "SSPC5通断状态";
CM_ SG_ 2418737168 RPDU3_B1_SSPC_DianHuErr_05 "SSPC5电弧故障状态";
CM_ SG_ 2418737168 BackUp123 "预留";
CM_ SG_ 2418671632 RPDU3_B1_SSPC_I_Load_04 "SSPC4通道电流";
CM_ SG_ 2418671632 RPDU3_B1_SSPC_TripSta_04 "SSPC4跳闸状态";
CM_ SG_ 2418671632 RPDU3_B1_SSPC_BitErr_04 "SSPC4通断周期自检状态";
CM_ SG_ 2418671632 RPDU3_B1_SSPC_OnOffSta_04 "SSPC4通断状态";
CM_ SG_ 2418671632 RPDU3_B1_SSPC_DianHuErr_04 "SSPC4电弧故障状态";
CM_ SG_ 2418671632 BackUp122 "预留";
CM_ SG_ 2418671632 RPDU3_B1_SSPC_I_Load_03 "SSPC3通道电流";
CM_ SG_ 2418671632 RPDU3_B1_SSPC_TripSta_03 "SSPC3跳闸状态";
CM_ SG_ 2418671632 RPDU3_B1_SSPC_BitErr_03 "SSPC3通断周期自检状态";
CM_ SG_ 2418671632 RPDU3_B1_SSPC_OnOffSta_03 "SSPC3通断状态";
CM_ SG_ 2418671632 RPDU3_B1_SSPC_DianHuErr_03 "SSPC3电弧故障状态";
CM_ SG_ 2418671632 BackUp121 "预留";
CM_ SG_ 2418671632 RPDU3_B1_SSPC_I_Load_02 "SSPC2通道电流";
CM_ SG_ 2418671632 RPDU3_B1_SSPC_TripSta_02 "SSPC2跳闸状态";
CM_ SG_ 2418671632 RPDU3_B1_SSPC_BitErr_02 "SSPC2通断周期自检状态";
CM_ SG_ 2418671632 RPDU3_B1_SSPC_OnOffSta_02 "SSPC2通断状态";
CM_ SG_ 2418671632 RPDU3_B1_SSPC_DianHuErr_02 "SSPC2电弧故障状态";
CM_ SG_ 2418671632 BackUp120 "预留";
CM_ SG_ 2418671632 RPDU3_B1_SSPC_I_Load_01 "SSPC1通道电流";
CM_ SG_ 2418671632 RPDU3_B1_SSPC_TripSta_01 "SSPC1跳闸状态";
CM_ SG_ 2418671632 RPDU3_B1_SSPC_BitErr_01 "SSPC1通断周期自检状态";
CM_ SG_ 2418671632 RPDU3_B1_SSPC_OnOffSta_01 "SSPC1通断状态";
CM_ SG_ 2418671632 RPDU3_B1_SSPC_DianHuErr_01 "SSPC1电弧故障状态";
CM_ SG_ 2418671632 BackUp119 "预留";
CM_ SG_ 2418606096 RPDU1_Index "序号";
CM_ SG_ 2418606096 BackUp118 "预留";
CM_ SG_ 2418606096 RPDU1_Time "时间";
CM_ SG_ 2418606096 RPDU1_SSPC_Ver "SSPC模块软件版本号";
CM_ SG_ 2418606096 RPDU1_PS_Ver "PS软件版本号";
CM_ SG_ 2418606096 BackUp117 "预留";
CM_ SG_ 2418606096 RPDU1_Hard_Num "硬件修改号";
CM_ SG_ 2418540560 BackUp116 "预留";
CM_ SG_ 2418540560 BackUp115 "预留";
CM_ SG_ 2418540560 RPDU1_B6_SSPC_I_Load_07 "SSPC7通道电流";
CM_ SG_ 2418540560 RPDU1_B6_SSPC_TripSta_07 "SSPC7跳闸状态";
CM_ SG_ 2418540560 RPDU1_B6_SSPC_BitErr_07 "SSPC7通断周期自检状态";
CM_ SG_ 2418540560 RPDU1_B6_SSPC_OnOffSta_07 "SSPC7通断状态";
CM_ SG_ 2418540560 RPDU1_B6_SSPC_DianHuErr_07 "SSPC7电弧故障状态";
CM_ SG_ 2418540560 BackUp114 "预留";
CM_ SG_ 2418540560 RPDU1_B6_SSPC_I_Load_06 "SSPC6通道电流";
CM_ SG_ 2418540560 RPDU1_B6_SSPC_TripSta_06 "SSPC6跳闸状态";
CM_ SG_ 2418540560 RPDU1_B6_SSPC_BitErr_06 "SSPC6通断周期自检状态";
CM_ SG_ 2418540560 RPDU1_B6_SSPC_OnOffSta_06 "SSPC6通断状态";
CM_ SG_ 2418540560 RPDU1_B6_SSPC_DianHuErr_06 "SSPC6电弧故障状态";
CM_ SG_ 2418540560 BackUp113 "预留";
CM_ SG_ 2418540560 RPDU1_B6_SSPC_I_Load_05 "SSPC5通道电流";
CM_ SG_ 2418540560 RPDU1_B6_SSPC_TripSta_05 "SSPC5跳闸状态";
CM_ SG_ 2418540560 RPDU1_B6_SSPC_BitErr_05 "SSPC5通断周期自检状态";
CM_ SG_ 2418540560 RPDU1_B6_SSPC_OnOffSta_05 "SSPC5通断状态";
CM_ SG_ 2418540560 RPDU1_B6_SSPC_DianHuErr_05 "SSPC5电弧故障状态";
CM_ SG_ 2418540560 BackUp112 "预留";
CM_ SG_ 2418475024 RPDU1_B6_SSPC_I_Load_04 "SSPC4通道电流";
CM_ SG_ 2418475024 RPDU1_B6_SSPC_TripSta_04 "SSPC4跳闸状态";
CM_ SG_ 2418475024 RPDU1_B6_SSPC_BitErr_04 "SSPC4通断周期自检状态";
CM_ SG_ 2418475024 RPDU1_B6_SSPC_OnOffSta_04 "SSPC4通断状态";
CM_ SG_ 2418475024 RPDU1_B6_SSPC_DianHuErr_04 "SSPC4电弧故障状态";
CM_ SG_ 2418475024 BackUp111 "预留";
CM_ SG_ 2418475024 RPDU1_B6_SSPC_I_Load_03 "SSPC3通道电流";
CM_ SG_ 2418475024 RPDU1_B6_SSPC_TripSta_03 "SSPC3跳闸状态";
CM_ SG_ 2418475024 RPDU1_B6_SSPC_BitErr_03 "SSPC3通断周期自检状态";
CM_ SG_ 2418475024 RPDU1_B6_SSPC_OnOffSta_03 "SSPC3通断状态";
CM_ SG_ 2418475024 RPDU1_B6_SSPC_DianHuErr_03 "SSPC3电弧故障状态";
CM_ SG_ 2418475024 BackUp110 "预留";
CM_ SG_ 2418475024 RPDU1_B6_SSPC_I_Load_02 "SSPC2通道电流";
CM_ SG_ 2418475024 RPDU1_B6_SSPC_TripSta_02 "SSPC2跳闸状态";
CM_ SG_ 2418475024 RPDU1_B6_SSPC_BitErr_02 "SSPC2通断周期自检状态";
CM_ SG_ 2418475024 RPDU1_B6_SSPC_OnOffSta_02 "SSPC2通断状态";
CM_ SG_ 2418475024 RPDU1_B6_SSPC_DianHuErr_02 "SSPC2电弧故障状态";
CM_ SG_ 2418475024 BackUp109 "预留";
CM_ SG_ 2418475024 RPDU1_B6_SSPC_I_Load_01 "SSPC1通道电流";
CM_ SG_ 2418475024 RPDU1_B6_SSPC_TripSta_01 "SSPC1跳闸状态";
CM_ SG_ 2418475024 RPDU1_B6_SSPC_BitErr_01 "SSPC1通断周期自检状态";
CM_ SG_ 2418475024 RPDU1_B6_SSPC_OnOffSta_01 "SSPC1通断状态";
CM_ SG_ 2418475024 RPDU1_B6_SSPC_DianHuErr_01 "SSPC1电弧故障状态";
CM_ SG_ 2418475024 BackUp108 "预留";
CM_ SG_ 2418409488 BackUp107 "预留";
CM_ SG_ 2418409488 BackUp106 "预留";
CM_ SG_ 2418409488 RPDU1_B5_SSPC_I_Load_07 "SSPC7通道电流";
CM_ SG_ 2418409488 RPDU1_B5_SSPC_TripSta_07 "SSPC7跳闸状态";
CM_ SG_ 2418409488 RPDU1_B5_SSPC_BitErr_07 "SSPC7通断周期自检状态";
CM_ SG_ 2418409488 RPDU1_B5_SSPC_OnOffSta_07 "SSPC7通断状态";
CM_ SG_ 2418409488 RPDU1_B5_SSPC_DianHuErr_07 "SSPC7电弧故障状态";
CM_ SG_ 2418409488 BackUp105 "预留";
CM_ SG_ 2418409488 RPDU1_B5_SSPC_I_Load_06 "SSPC6通道电流";
CM_ SG_ 2418409488 RPDU1_B5_SSPC_TripSta_06 "SSPC6跳闸状态";
CM_ SG_ 2418409488 RPDU1_B5_SSPC_BitErr_06 "SSPC6通断周期自检状态";
CM_ SG_ 2418409488 RPDU1_B5_SSPC_OnOffSta_06 "SSPC6通断状态";
CM_ SG_ 2418409488 RPDU1_B5_SSPC_DianHuErr_06 "SSPC6电弧故障状态";
CM_ SG_ 2418409488 BackUp104 "预留";
CM_ SG_ 2418409488 RPDU1_B5_SSPC_I_Load_05 "SSPC5通道电流";
CM_ SG_ 2418409488 RPDU1_B5_SSPC_TripSta_05 "SSPC5跳闸状态";
CM_ SG_ 2418409488 RPDU1_B5_SSPC_BitErr_05 "SSPC5通断周期自检状态";
CM_ SG_ 2418409488 RPDU1_B5_SSPC_OnOffSta_05 "SSPC5通断状态";
CM_ SG_ 2418409488 RPDU1_B5_SSPC_DianHuErr_05 "SSPC5电弧故障状态";
CM_ SG_ 2418409488 BackUp103 "预留";
CM_ SG_ 2418343952 RPDU1_B5_SSPC_I_Load_04 "SSPC4通道电流";
CM_ SG_ 2418343952 RPDU1_B5_SSPC_TripSta_04 "SSPC4跳闸状态";
CM_ SG_ 2418343952 RPDU1_B5_SSPC_BitErr_04 "SSPC4通断周期自检状态";
CM_ SG_ 2418343952 RPDU1_B5_SSPC_OnOffSta_04 "SSPC4通断状态";
CM_ SG_ 2418343952 RPDU1_B5_SSPC_DianHuErr_04 "SSPC4电弧故障状态";
CM_ SG_ 2418343952 BackUp102 "预留";
CM_ SG_ 2418343952 RPDU1_B5_SSPC_I_Load_03 "SSPC3通道电流";
CM_ SG_ 2418343952 RPDU1_B5_SSPC_TripSta_03 "SSPC3跳闸状态";
CM_ SG_ 2418343952 RPDU1_B5_SSPC_BitErr_03 "SSPC3通断周期自检状态";
CM_ SG_ 2418343952 RPDU1_B5_SSPC_OnOffSta_03 "SSPC3通断状态";
CM_ SG_ 2418343952 RPDU1_B5_SSPC_DianHuErr_03 "SSPC3电弧故障状态";
CM_ SG_ 2418343952 BackUp101 "预留";
CM_ SG_ 2418343952 RPDU1_B5_SSPC_I_Load_02 "SSPC2通道电流";
CM_ SG_ 2418343952 RPDU1_B5_SSPC_TripSta_02 "SSPC2跳闸状态";
CM_ SG_ 2418343952 RPDU1_B5_SSPC_BitErr_02 "SSPC2通断周期自检状态";
CM_ SG_ 2418343952 RPDU1_B5_SSPC_OnOffSta_02 "SSPC2通断状态";
CM_ SG_ 2418343952 RPDU1_B5_SSPC_DianHuErr_02 "SSPC2电弧故障状态";
CM_ SG_ 2418343952 BackUp100 "预留";
CM_ SG_ 2418343952 RPDU1_B5_SSPC_I_Load_01 "SSPC1通道电流";
CM_ SG_ 2418343952 RPDU1_B5_SSPC_TripSta_01 "SSPC1跳闸状态";
CM_ SG_ 2418343952 RPDU1_B5_SSPC_BitErr_01 "SSPC1通断周期自检状态";
CM_ SG_ 2418343952 RPDU1_B5_SSPC_OnOffSta_01 "SSPC1通断状态";
CM_ SG_ 2418343952 RPDU1_B5_SSPC_DianHuErr_01 "SSPC1电弧故障状态";
CM_ SG_ 2418343952 BackUp099 "预留";
CM_ SG_ 2418278416 BackUp098 "预留";
CM_ SG_ 2418278416 BackUp097 "预留";
CM_ SG_ 2418278416 BackUp096 "预留";
CM_ SG_ 2418278416 BackUp095 "预留";
CM_ SG_ 2418278416 RPDU1_B4_SSPC_I_Load_18 "SSPC18通道电流";
CM_ SG_ 2418278416 RPDU1_B4_SSPC_TripSta_18 "SSPC18跳闸状态";
CM_ SG_ 2418278416 RPDU1_B4_SSPC_BitErr_18 "SSPC18通断周期自检状态";
CM_ SG_ 2418278416 RPDU1_B4_SSPC_OnOffSta_18 "SSPC18通断状态";
CM_ SG_ 2418278416 RPDU1_B4_SSPC_DianHuErr_18 "SSPC18电弧故障状态";
CM_ SG_ 2418278416 BackUp094 "预留";
CM_ SG_ 2418278416 RPDU1_B4_SSPC_I_Load_17 "SSPC17通道电流";
CM_ SG_ 2418278416 RPDU1_B4_SSPC_TripSta_17 "SSPC17跳闸状态";
CM_ SG_ 2418278416 RPDU1_B4_SSPC_BitErr_17 "SSPC17通断周期自检状态";
CM_ SG_ 2418278416 RPDU1_B4_SSPC_OnOffSta_17 "SSPC17通断状态";
CM_ SG_ 2418278416 RPDU1_B4_SSPC_DianHuErr_17 "SSPC17电弧故障状态";
CM_ SG_ 2418278416 BackUp093 "预留";
CM_ SG_ 2418212880 RPDU1_B4_SSPC_I_Load_16 "SSPC16通道电流";
CM_ SG_ 2418212880 RPDU1_B4_SSPC_TripSta_16 "SSPC16跳闸状态";
CM_ SG_ 2418212880 RPDU1_B4_SSPC_BitErr_16 "SSPC16通断周期自检状态";
CM_ SG_ 2418212880 RPDU1_B4_SSPC_OnOffSta_16 "SSPC16通断状态";
CM_ SG_ 2418212880 RPDU1_B4_SSPC_DianHuErr_16 "SSPC16电弧故障状态";
CM_ SG_ 2418212880 BackUp092 "预留";
CM_ SG_ 2418212880 RPDU1_B4_SSPC_I_Load_15 "SSPC15通道电流";
CM_ SG_ 2418212880 RPDU1_B4_SSPC_TripSta_15 "SSPC15跳闸状态";
CM_ SG_ 2418212880 RPDU1_B4_SSPC_BitErr_15 "SSPC15通断周期自检状态";
CM_ SG_ 2418212880 RPDU1_B4_SSPC_OnOffSta_15 "SSPC15通断状态";
CM_ SG_ 2418212880 RPDU1_B4_SSPC_DianHuErr_15 "SSPC15电弧故障状态";
CM_ SG_ 2418212880 BackUp091 "预留";
CM_ SG_ 2418212880 RPDU1_B4_SSPC_I_Load_14 "SSPC14通道电流";
CM_ SG_ 2418212880 RPDU1_B4_SSPC_TripSta_14 "SSPC14跳闸状态";
CM_ SG_ 2418212880 RPDU1_B4_SSPC_BitErr_14 "SSPC14通断周期自检状态";
CM_ SG_ 2418212880 RPDU1_B4_SSPC_OnOffSta_14 "SSPC14通断状态";
CM_ SG_ 2418212880 RPDU1_B4_SSPC_DianHuErr_14 "SSPC14电弧故障状态";
CM_ SG_ 2418212880 BackUp090 "预留";
CM_ SG_ 2418212880 RPDU1_B4_SSPC_I_Load_13 "SSPC13通道电流";
CM_ SG_ 2418212880 RPDU1_B4_SSPC_TripSta_13 "SSPC13跳闸状态";
CM_ SG_ 2418212880 RPDU1_B4_SSPC_BitErr_13 "SSPC13通断周期自检状态";
CM_ SG_ 2418212880 RPDU1_B4_SSPC_OnOffSta_13 "SSPC13通断状态";
CM_ SG_ 2418212880 RPDU1_B4_SSPC_DianHuErr_13 "SSPC13电弧故障状态";
CM_ SG_ 2418212880 BackUp089 "预留";
CM_ SG_ 2418147344 RPDU1_B4_SSPC_I_Load_12 "SSPC12通道电流";
CM_ SG_ 2418147344 RPDU1_B4_SSPC_TripSta_12 "SSPC12跳闸状态";
CM_ SG_ 2418147344 RPDU1_B4_SSPC_BitErr_12 "SSPC12通断周期自检状态";
CM_ SG_ 2418147344 RPDU1_B4_SSPC_OnOffSta_12 "SSPC12通断状态";
CM_ SG_ 2418147344 RPDU1_B4_SSPC_DianHuErr_12 "SSPC12电弧故障状态";
CM_ SG_ 2418147344 BackUp088 "预留";
CM_ SG_ 2418147344 RPDU1_B4_SSPC_I_Load_11 "SSPC11通道电流";
CM_ SG_ 2418147344 RPDU1_B4_SSPC_TripSta_11 "SSPC11跳闸状态";
CM_ SG_ 2418147344 RPDU1_B4_SSPC_BitErr_11 "SSPC11通断周期自检状态";
CM_ SG_ 2418147344 RPDU1_B4_SSPC_OnOffSta_11 "SSPC11通断状态";
CM_ SG_ 2418147344 RPDU1_B4_SSPC_DianHuErr_11 "SSPC11电弧故障状态";
CM_ SG_ 2418147344 BackUp087 "预留";
CM_ SG_ 2418147344 RPDU1_B4_SSPC_I_Load_10 "SSPC10通道电流";
CM_ SG_ 2418147344 RPDU1_B4_SSPC_TripSta_10 "SSPC10跳闸状态";
CM_ SG_ 2418147344 RPDU1_B4_SSPC_BitErr_10 "SSPC10通断周期自检状态";
CM_ SG_ 2418147344 RPDU1_B4_SSPC_OnOffSta_10 "SSPC10通断状态";
CM_ SG_ 2418147344 RPDU1_B4_SSPC_DianHuErr_10 "SSPC10电弧故障状态";
CM_ SG_ 2418147344 BackUp086 "预留";
CM_ SG_ 2418147344 RPDU1_B4_SSPC_I_Load_09 "SSPC9通道电流";
CM_ SG_ 2418147344 RPDU1_B4_SSPC_TripSta_09 "SSPC9跳闸状态";
CM_ SG_ 2418147344 RPDU1_B4_SSPC_BitErr_09 "SSPC9通断周期自检状态";
CM_ SG_ 2418147344 RPDU1_B4_SSPC_OnOffSta_09 "SSPC9通断状态";
CM_ SG_ 2418147344 RPDU1_B4_SSPC_DianHuErr_09 "SSPC9电弧故障状态";
CM_ SG_ 2418147344 BackUp085 "预留";
CM_ SG_ 2418081808 RPDU1_B4_SSPC_I_Load_08 "SSPC8通道电流";
CM_ SG_ 2418081808 RPDU1_B4_SSPC_TripSta_08 "SSPC8跳闸状态";
CM_ SG_ 2418081808 RPDU1_B4_SSPC_BitErr_08 "SSPC8通断周期自检状态";
CM_ SG_ 2418081808 RPDU1_B4_SSPC_OnOffSta_08 "SSPC8通断状态";
CM_ SG_ 2418081808 RPDU1_B4_SSPC_DianHuErr_08 "SSPC8电弧故障状态";
CM_ SG_ 2418081808 BackUp084 "预留";
CM_ SG_ 2418081808 RPDU1_B4_SSPC_I_Load_07 "SSPC7通道电流";
CM_ SG_ 2418081808 RPDU1_B4_SSPC_TripSta_07 "SSPC7跳闸状态";
CM_ SG_ 2418081808 RPDU1_B4_SSPC_BitErr_07 "SSPC7通断周期自检状态";
CM_ SG_ 2418081808 RPDU1_B4_SSPC_OnOffSta_07 "SSPC7通断状态";
CM_ SG_ 2418081808 RPDU1_B4_SSPC_DianHuErr_07 "SSPC7电弧故障状态";
CM_ SG_ 2418081808 BackUp083 "预留";
CM_ SG_ 2418081808 RPDU1_B4_SSPC_I_Load_06 "SSPC6通道电流";
CM_ SG_ 2418081808 RPDU1_B4_SSPC_TripSta_06 "SSPC6跳闸状态";
CM_ SG_ 2418081808 RPDU1_B4_SSPC_BitErr_06 "SSPC6通断周期自检状态";
CM_ SG_ 2418081808 RPDU1_B4_SSPC_OnOffSta_06 "SSPC6通断状态";
CM_ SG_ 2418081808 RPDU1_B4_SSPC_DianHuErr_06 "SSPC6电弧故障状态";
CM_ SG_ 2418081808 BackUp082 "预留";
CM_ SG_ 2418081808 RPDU1_B4_SSPC_I_Load_05 "SSPC5通道电流";
CM_ SG_ 2418081808 RPDU1_B4_SSPC_TripSta_05 "SSPC5跳闸状态";
CM_ SG_ 2418081808 RPDU1_B4_SSPC_BitErr_05 "SSPC5通断周期自检状态";
CM_ SG_ 2418081808 RPDU1_B4_SSPC_OnOffSta_05 "SSPC5通断状态";
CM_ SG_ 2418081808 RPDU1_B4_SSPC_DianHuErr_05 "SSPC5电弧故障状态";
CM_ SG_ 2418081808 BackUp081 "预留";
CM_ SG_ 2418016272 RPDU1_B4_SSPC_I_Load_04 "SSPC4通道电流";
CM_ SG_ 2418016272 RPDU1_B4_SSPC_TripSta_04 "SSPC4跳闸状态";
CM_ SG_ 2418016272 RPDU1_B4_SSPC_BitErr_04 "SSPC4通断周期自检状态";
CM_ SG_ 2418016272 RPDU1_B4_SSPC_OnOffSta_04 "SSPC4通断状态";
CM_ SG_ 2418016272 RPDU1_B4_SSPC_DianHuErr_04 "SSPC4电弧故障状态";
CM_ SG_ 2418016272 BackUp080 "预留";
CM_ SG_ 2418016272 RPDU1_B4_SSPC_I_Load_03 "SSPC3通道电流";
CM_ SG_ 2418016272 RPDU1_B4_SSPC_TripSta_03 "SSPC3跳闸状态";
CM_ SG_ 2418016272 RPDU1_B4_SSPC_BitErr_03 "SSPC3通断周期自检状态";
CM_ SG_ 2418016272 RPDU1_B4_SSPC_OnOffSta_03 "SSPC3通断状态";
CM_ SG_ 2418016272 RPDU1_B4_SSPC_DianHuErr_03 "SSPC3电弧故障状态";
CM_ SG_ 2418016272 BackUp079 "预留";
CM_ SG_ 2418016272 RPDU1_B4_SSPC_I_Load_02 "SSPC2通道电流";
CM_ SG_ 2418016272 RPDU1_B4_SSPC_TripSta_02 "SSPC2跳闸状态";
CM_ SG_ 2418016272 RPDU1_B4_SSPC_BitErr_02 "SSPC2通断周期自检状态";
CM_ SG_ 2418016272 RPDU1_B4_SSPC_OnOffSta_02 "SSPC2通断状态";
CM_ SG_ 2418016272 RPDU1_B4_SSPC_DianHuErr_02 "SSPC2电弧故障状态";
CM_ SG_ 2418016272 BackUp078 "预留";
CM_ SG_ 2418016272 RPDU1_B4_SSPC_I_Load_01 "SSPC1通道电流";
CM_ SG_ 2418016272 RPDU1_B4_SSPC_TripSta_01 "SSPC1跳闸状态";
CM_ SG_ 2418016272 RPDU1_B4_SSPC_BitErr_01 "SSPC1通断周期自检状态";
CM_ SG_ 2418016272 RPDU1_B4_SSPC_OnOffSta_01 "SSPC1通断状态";
CM_ SG_ 2418016272 RPDU1_B4_SSPC_DianHuErr_01 "SSPC1电弧故障状态";
CM_ SG_ 2418016272 BackUp077 "预留";
CM_ SG_ 2417950736 BackUp076 "预留";
CM_ SG_ 2417950736 BackUp075 "预留";
CM_ SG_ 2417950736 BackUp074 "预留";
CM_ SG_ 2417950736 BackUp073 "预留";
CM_ SG_ 2417950736 RPDU1_B3_SSPC_I_Load_18 "SSPC18通道电流";
CM_ SG_ 2417950736 RPDU1_B3_SSPC_TripSta_18 "SSPC18跳闸状态";
CM_ SG_ 2417950736 RPDU1_B3_SSPC_BitErr_18 "SSPC18通断周期自检状态";
CM_ SG_ 2417950736 RPDU1_B3_SSPC_OnOffSta_18 "SSPC18通断状态";
CM_ SG_ 2417950736 RPDU1_B3_SSPC_DianHuErr_18 "SSPC18电弧故障状态";
CM_ SG_ 2417950736 BackUp072 "预留";
CM_ SG_ 2417950736 RPDU1_B3_SSPC_I_Load_17 "SSPC17通道电流";
CM_ SG_ 2417950736 RPDU1_B3_SSPC_TripSta_17 "SSPC17跳闸状态";
CM_ SG_ 2417950736 RPDU1_B3_SSPC_BitErr_17 "SSPC17通断周期自检状态";
CM_ SG_ 2417950736 RPDU1_B3_SSPC_OnOffSta_17 "SSPC17通断状态";
CM_ SG_ 2417950736 RPDU1_B3_SSPC_DianHuErr_17 "SSPC17电弧故障状态";
CM_ SG_ 2417950736 BackUp071 "预留";
CM_ SG_ 2417885200 RPDU1_B3_SSPC_I_Load_16 "SSPC16通道电流";
CM_ SG_ 2417885200 RPDU1_B3_SSPC_TripSta_16 "SSPC16跳闸状态";
CM_ SG_ 2417885200 RPDU1_B3_SSPC_BitErr_16 "SSPC16通断周期自检状态";
CM_ SG_ 2417885200 RPDU1_B3_SSPC_OnOffSta_16 "SSPC16通断状态";
CM_ SG_ 2417885200 RPDU1_B3_SSPC_DianHuErr_16 "SSPC16电弧故障状态";
CM_ SG_ 2417885200 BackUp070 "预留";
CM_ SG_ 2417885200 RPDU1_B3_SSPC_I_Load_15 "SSPC15通道电流";
CM_ SG_ 2417885200 RPDU1_B3_SSPC_TripSta_15 "SSPC15跳闸状态";
CM_ SG_ 2417885200 RPDU1_B3_SSPC_BitErr_15 "SSPC15通断周期自检状态";
CM_ SG_ 2417885200 RPDU1_B3_SSPC_OnOffSta_15 "SSPC15通断状态";
CM_ SG_ 2417885200 RPDU1_B3_SSPC_DianHuErr_15 "SSPC15电弧故障状态";
CM_ SG_ 2417885200 BackUp069 "预留";
CM_ SG_ 2417885200 RPDU1_B3_SSPC_I_Load_14 "SSPC14通道电流";
CM_ SG_ 2417885200 RPDU1_B3_SSPC_TripSta_14 "SSPC14跳闸状态";
CM_ SG_ 2417885200 RPDU1_B3_SSPC_BitErr_14 "SSPC14通断周期自检状态";
CM_ SG_ 2417885200 RPDU1_B3_SSPC_OnOffSta_14 "SSPC14通断状态";
CM_ SG_ 2417885200 RPDU1_B3_SSPC_DianHuErr_14 "SSPC14电弧故障状态";
CM_ SG_ 2417885200 BackUp068 "预留";
CM_ SG_ 2417885200 RPDU1_B3_SSPC_I_Load_13 "SSPC13通道电流";
CM_ SG_ 2417885200 RPDU1_B3_SSPC_TripSta_13 "SSPC13跳闸状态";
CM_ SG_ 2417885200 RPDU1_B3_SSPC_BitErr_13 "SSPC13通断周期自检状态";
CM_ SG_ 2417885200 RPDU1_B3_SSPC_OnOffSta_13 "SSPC13通断状态";
CM_ SG_ 2417885200 RPDU1_B3_SSPC_DianHuErr_13 "SSPC13电弧故障状态";
CM_ SG_ 2417885200 BackUp067 "预留";
CM_ SG_ 2417819664 RPDU1_B3_SSPC_I_Load_12 "SSPC12通道电流";
CM_ SG_ 2417819664 RPDU1_B3_SSPC_TripSta_12 "SSPC12跳闸状态";
CM_ SG_ 2417819664 RPDU1_B3_SSPC_BitErr_12 "SSPC12通断周期自检状态";
CM_ SG_ 2417819664 RPDU1_B3_SSPC_OnOffSta_12 "SSPC12通断状态";
CM_ SG_ 2417819664 RPDU1_B3_SSPC_DianHuErr_12 "SSPC12电弧故障状态";
CM_ SG_ 2417819664 BackUp066 "预留";
CM_ SG_ 2417819664 RPDU1_B3_SSPC_I_Load_11 "SSPC11通道电流";
CM_ SG_ 2417819664 RPDU1_B3_SSPC_TripSta_11 "SSPC11跳闸状态";
CM_ SG_ 2417819664 RPDU1_B3_SSPC_BitErr_11 "SSPC11通断周期自检状态";
CM_ SG_ 2417819664 RPDU1_B3_SSPC_OnOffSta_11 "SSPC11通断状态";
CM_ SG_ 2417819664 RPDU1_B3_SSPC_DianHuErr_11 "SSPC11电弧故障状态";
CM_ SG_ 2417819664 BackUp065 "预留";
CM_ SG_ 2417819664 RPDU1_B3_SSPC_I_Load_10 "SSPC10通道电流";
CM_ SG_ 2417819664 RPDU1_B3_SSPC_TripSta_10 "SSPC10跳闸状态";
CM_ SG_ 2417819664 RPDU1_B3_SSPC_BitErr_10 "SSPC10通断周期自检状态";
CM_ SG_ 2417819664 RPDU1_B3_SSPC_OnOffSta_10 "SSPC10通断状态";
CM_ SG_ 2417819664 RPDU1_B3_SSPC_DianHuErr_10 "SSPC10电弧故障状态";
CM_ SG_ 2417819664 BackUp064 "预留";
CM_ SG_ 2417819664 RPDU1_B3_SSPC_I_Load_09 "SSPC9通道电流";
CM_ SG_ 2417819664 RPDU1_B3_SSPC_TripSta_09 "SSPC9跳闸状态";
CM_ SG_ 2417819664 RPDU1_B3_SSPC_BitErr_09 "SSPC9通断周期自检状态";
CM_ SG_ 2417819664 RPDU1_B3_SSPC_OnOffSta_09 "SSPC9通断状态";
CM_ SG_ 2417819664 RPDU1_B3_SSPC_DianHuErr_09 "SSPC9电弧故障状态";
CM_ SG_ 2417819664 BackUp063 "预留";
CM_ SG_ 2417754128 RPDU1_B3_SSPC_I_Load_08 "SSPC8通道电流";
CM_ SG_ 2417754128 RPDU1_B3_SSPC_TripSta_08 "SSPC8跳闸状态";
CM_ SG_ 2417754128 RPDU1_B3_SSPC_BitErr_08 "SSPC8通断周期自检状态";
CM_ SG_ 2417754128 RPDU1_B3_SSPC_OnOffSta_08 "SSPC8通断状态";
CM_ SG_ 2417754128 RPDU1_B3_SSPC_DianHuErr_08 "SSPC8电弧故障状态";
CM_ SG_ 2417754128 BackUp062 "预留";
CM_ SG_ 2417754128 RPDU1_B3_SSPC_I_Load_07 "SSPC7通道电流";
CM_ SG_ 2417754128 RPDU1_B3_SSPC_TripSta_07 "SSPC7跳闸状态";
CM_ SG_ 2417754128 RPDU1_B3_SSPC_BitErr_07 "SSPC7通断周期自检状态";
CM_ SG_ 2417754128 RPDU1_B3_SSPC_OnOffSta_07 "SSPC7通断状态";
CM_ SG_ 2417754128 RPDU1_B3_SSPC_DianHuErr_07 "SSPC7电弧故障状态";
CM_ SG_ 2417754128 BackUp061 "预留";
CM_ SG_ 2417754128 RPDU1_B3_SSPC_I_Load_06 "SSPC6通道电流";
CM_ SG_ 2417754128 RPDU1_B3_SSPC_TripSta_06 "SSPC6跳闸状态";
CM_ SG_ 2417754128 RPDU1_B3_SSPC_BitErr_06 "SSPC6通断周期自检状态";
CM_ SG_ 2417754128 RPDU1_B3_SSPC_OnOffSta_06 "SSPC6通断状态";
CM_ SG_ 2417754128 RPDU1_B3_SSPC_DianHuErr_06 "SSPC6电弧故障状态";
CM_ SG_ 2417754128 BackUp060 "预留";
CM_ SG_ 2417754128 RPDU1_B3_SSPC_I_Load_05 "SSPC5通道电流";
CM_ SG_ 2417754128 RPDU1_B3_SSPC_TripSta_05 "SSPC5跳闸状态";
CM_ SG_ 2417754128 RPDU1_B3_SSPC_BitErr_05 "SSPC5通断周期自检状态";
CM_ SG_ 2417754128 RPDU1_B3_SSPC_OnOffSta_05 "SSPC5通断状态";
CM_ SG_ 2417754128 RPDU1_B3_SSPC_DianHuErr_05 "SSPC5电弧故障状态";
CM_ SG_ 2417754128 BackUp059 "预留";
CM_ SG_ 2417688592 RPDU1_B3_SSPC_I_Load_04 "SSPC4通道电流";
CM_ SG_ 2417688592 RPDU1_B3_SSPC_TripSta_04 "SSPC4跳闸状态";
CM_ SG_ 2417688592 RPDU1_B3_SSPC_BitErr_04 "SSPC4通断周期自检状态";
CM_ SG_ 2417688592 RPDU1_B3_SSPC_OnOffSta_04 "SSPC4通断状态";
CM_ SG_ 2417688592 RPDU1_B3_SSPC_DianHuErr_04 "SSPC4电弧故障状态";
CM_ SG_ 2417688592 BackUp058 "预留";
CM_ SG_ 2417688592 RPDU1_B3_SSPC_I_Load_03 "SSPC3通道电流";
CM_ SG_ 2417688592 RPDU1_B3_SSPC_TripSta_03 "SSPC3跳闸状态";
CM_ SG_ 2417688592 RPDU1_B3_SSPC_BitErr_03 "SSPC3通断周期自检状态";
CM_ SG_ 2417688592 RPDU1_B3_SSPC_OnOffSta_03 "SSPC3通断状态";
CM_ SG_ 2417688592 RPDU1_B3_SSPC_DianHuErr_03 "SSPC3电弧故障状态";
CM_ SG_ 2417688592 BackUp057 "预留";
CM_ SG_ 2417688592 RPDU1_B3_SSPC_I_Load_02 "SSPC2通道电流";
CM_ SG_ 2417688592 RPDU1_B3_SSPC_TripSta_02 "SSPC2跳闸状态";
CM_ SG_ 2417688592 RPDU1_B3_SSPC_BitErr_02 "SSPC2通断周期自检状态";
CM_ SG_ 2417688592 RPDU1_B3_SSPC_OnOffSta_02 "SSPC2通断状态";
CM_ SG_ 2417688592 RPDU1_B3_SSPC_DianHuErr_02 "SSPC2电弧故障状态";
CM_ SG_ 2417688592 BackUp056 "预留";
CM_ SG_ 2417688592 RPDU1_B3_SSPC_I_Load_01 "SSPC1通道电流";
CM_ SG_ 2417688592 RPDU1_B3_SSPC_TripSta_01 "SSPC1跳闸状态";
CM_ SG_ 2417688592 RPDU1_B3_SSPC_BitErr_01 "SSPC1通断周期自检状态";
CM_ SG_ 2417688592 RPDU1_B3_SSPC_OnOffSta_01 "SSPC1通断状态";
CM_ SG_ 2417688592 RPDU1_B3_SSPC_DianHuErr_01 "SSPC1电弧故障状态";
CM_ SG_ 2417688592 BackUp055 "预留";
CM_ SG_ 2417623056 BackUp054 "预留";
CM_ SG_ 2417623056 BackUp053 "预留";
CM_ SG_ 2417623056 BackUp052 "预留";
CM_ SG_ 2417623056 BackUp051 "预留";
CM_ SG_ 2417623056 RPDU1_B2_SSPC_I_Load_18 "SSPC18通道电流";
CM_ SG_ 2417623056 RPDU1_B2_SSPC_TripSta_18 "SSPC18跳闸状态";
CM_ SG_ 2417623056 RPDU1_B2_SSPC_BitErr_18 "SSPC18通断周期自检状态";
CM_ SG_ 2417623056 RPDU1_B2_SSPC_OnOffSta_18 "SSPC18通断状态";
CM_ SG_ 2417623056 RPDU1_B2_SSPC_DianHuErr_18 "SSPC18电弧故障状态";
CM_ SG_ 2417623056 BackUp050 "预留";
CM_ SG_ 2417623056 RPDU1_B2_SSPC_I_Load_17 "SSPC17通道电流";
CM_ SG_ 2417623056 RPDU1_B2_SSPC_TripSta_17 "SSPC17跳闸状态";
CM_ SG_ 2417623056 RPDU1_B2_SSPC_BitErr_17 "SSPC17通断周期自检状态";
CM_ SG_ 2417623056 RPDU1_B2_SSPC_OnOffSta_17 "SSPC17通断状态";
CM_ SG_ 2417623056 RPDU1_B2_SSPC_DianHuErr_17 "SSPC17电弧故障状态";
CM_ SG_ 2417623056 BackUp049 "预留";
CM_ SG_ 2417557520 RPDU1_B2_SSPC_I_Load_16 "SSPC16通道电流";
CM_ SG_ 2417557520 RPDU1_B2_SSPC_TripSta_16 "SSPC16跳闸状态";
CM_ SG_ 2417557520 RPDU1_B2_SSPC_BitErr_16 "SSPC16通断周期自检状态";
CM_ SG_ 2417557520 RPDU1_B2_SSPC_OnOffSta_16 "SSPC16通断状态";
CM_ SG_ 2417557520 RPDU1_B2_SSPC_DianHuErr_16 "SSPC16电弧故障状态";
CM_ SG_ 2417557520 BackUp048 "预留";
CM_ SG_ 2417557520 RPDU1_B2_SSPC_I_Load_15 "SSPC15通道电流";
CM_ SG_ 2417557520 RPDU1_B2_SSPC_TripSta_15 "SSPC15跳闸状态";
CM_ SG_ 2417557520 RPDU1_B2_SSPC_BitErr_15 "SSPC15通断周期自检状态";
CM_ SG_ 2417557520 RPDU1_B2_SSPC_OnOffSta_15 "SSPC15通断状态";
CM_ SG_ 2417557520 RPDU1_B2_SSPC_DianHuErr_15 "SSPC15电弧故障状态";
CM_ SG_ 2417557520 BackUp047 "预留";
CM_ SG_ 2417557520 RPDU1_B2_SSPC_I_Load_14 "SSPC14通道电流";
CM_ SG_ 2417557520 RPDU1_B2_SSPC_TripSta_14 "SSPC14跳闸状态";
CM_ SG_ 2417557520 RPDU1_B2_SSPC_BitErr_14 "SSPC14通断周期自检状态";
CM_ SG_ 2417557520 RPDU1_B2_SSPC_OnOffSta_14 "SSPC14通断状态";
CM_ SG_ 2417557520 RPDU1_B2_SSPC_DianHuErr_14 "SSPC14电弧故障状态";
CM_ SG_ 2417557520 BackUp046 "预留";
CM_ SG_ 2417557520 RPDU1_B2_SSPC_I_Load_13 "SSPC13通道电流";
CM_ SG_ 2417557520 RPDU1_B2_SSPC_TripSta_13 "SSPC13跳闸状态";
CM_ SG_ 2417557520 RPDU1_B2_SSPC_BitErr_13 "SSPC13通断周期自检状态";
CM_ SG_ 2417557520 RPDU1_B2_SSPC_OnOffSta_13 "SSPC13通断状态";
CM_ SG_ 2417557520 RPDU1_B2_SSPC_DianHuErr_13 "SSPC13电弧故障状态";
CM_ SG_ 2417557520 BackUp045 "预留";
CM_ SG_ 2417491984 RPDU1_B2_SSPC_I_Load_12 "SSPC12通道电流";
CM_ SG_ 2417491984 RPDU1_B2_SSPC_TripSta_12 "SSPC12跳闸状态";
CM_ SG_ 2417491984 RPDU1_B2_SSPC_BitErr_12 "SSPC12通断周期自检状态";
CM_ SG_ 2417491984 RPDU1_B2_SSPC_OnOffSta_12 "SSPC12通断状态";
CM_ SG_ 2417491984 RPDU1_B2_SSPC_DianHuErr_12 "SSPC12电弧故障状态";
CM_ SG_ 2417491984 BackUp044 "预留";
CM_ SG_ 2417491984 RPDU1_B2_SSPC_I_Load_11 "SSPC11通道电流";
CM_ SG_ 2417491984 RPDU1_B2_SSPC_TripSta_11 "SSPC11跳闸状态";
CM_ SG_ 2417491984 RPDU1_B2_SSPC_BitErr_11 "SSPC11通断周期自检状态";
CM_ SG_ 2417491984 RPDU1_B2_SSPC_OnOffSta_11 "SSPC11通断状态";
CM_ SG_ 2417491984 RPDU1_B2_SSPC_DianHuErr_11 "SSPC11电弧故障状态";
CM_ SG_ 2417491984 BackUp043 "预留";
CM_ SG_ 2417491984 RPDU1_B2_SSPC_I_Load_10 "SSPC10通道电流";
CM_ SG_ 2417491984 RPDU1_B2_SSPC_TripSta_10 "SSPC10跳闸状态";
CM_ SG_ 2417491984 RPDU1_B2_SSPC_BitErr_10 "SSPC10通断周期自检状态";
CM_ SG_ 2417491984 RPDU1_B2_SSPC_OnOffSta_10 "SSPC10通断状态";
CM_ SG_ 2417491984 RPDU1_B2_SSPC_DianHuErr_10 "SSPC10电弧故障状态";
CM_ SG_ 2417491984 BackUp042 "预留";
CM_ SG_ 2417491984 RPDU1_B2_SSPC_I_Load_09 "SSPC9通道电流";
CM_ SG_ 2417491984 RPDU1_B2_SSPC_TripSta_09 "SSPC9跳闸状态";
CM_ SG_ 2417491984 RPDU1_B2_SSPC_BitErr_09 "SSPC9通断周期自检状态";
CM_ SG_ 2417491984 RPDU1_B2_SSPC_OnOffSta_09 "SSPC9通断状态";
CM_ SG_ 2417491984 RPDU1_B2_SSPC_DianHuErr_09 "SSPC9电弧故障状态";
CM_ SG_ 2417491984 BackUp041 "预留";
CM_ SG_ 2417426448 RPDU1_B2_SSPC_I_Load_08 "SSPC8通道电流";
CM_ SG_ 2417426448 RPDU1_B2_SSPC_TripSta_08 "SSPC8跳闸状态";
CM_ SG_ 2417426448 RPDU1_B2_SSPC_BitErr_08 "SSPC8通断周期自检状态";
CM_ SG_ 2417426448 RPDU1_B2_SSPC_OnOffSta_08 "SSPC8通断状态";
CM_ SG_ 2417426448 RPDU1_B2_SSPC_DianHuErr_08 "SSPC8电弧故障状态";
CM_ SG_ 2417426448 BackUp040 "预留";
CM_ SG_ 2417426448 RPDU1_B2_SSPC_I_Load_07 "SSPC7通道电流";
CM_ SG_ 2417426448 RPDU1_B2_SSPC_TripSta_07 "SSPC7跳闸状态";
CM_ SG_ 2417426448 RPDU1_B2_SSPC_BitErr_07 "SSPC7通断周期自检状态";
CM_ SG_ 2417426448 RPDU1_B2_SSPC_OnOffSta_07 "SSPC7通断状态";
CM_ SG_ 2417426448 RPDU1_B2_SSPC_DianHuErr_07 "SSPC7电弧故障状态";
CM_ SG_ 2417426448 BackUp039 "预留";
CM_ SG_ 2417426448 RPDU1_B2_SSPC_I_Load_06 "SSPC6通道电流";
CM_ SG_ 2417426448 RPDU1_B2_SSPC_TripSta_06 "SSPC6跳闸状态";
CM_ SG_ 2417426448 RPDU1_B2_SSPC_BitErr_06 "SSPC6通断周期自检状态";
CM_ SG_ 2417426448 RPDU1_B2_SSPC_OnOffSta_06 "SSPC6通断状态";
CM_ SG_ 2417426448 RPDU1_B2_SSPC_DianHuErr_06 "SSPC6电弧故障状态";
CM_ SG_ 2417426448 BackUp038 "预留";
CM_ SG_ 2417426448 RPDU1_B2_SSPC_I_Load_05 "SSPC5通道电流";
CM_ SG_ 2417426448 RPDU1_B2_SSPC_TripSta_05 "SSPC5跳闸状态";
CM_ SG_ 2417426448 RPDU1_B2_SSPC_BitErr_05 "SSPC5通断周期自检状态";
CM_ SG_ 2417426448 RPDU1_B2_SSPC_OnOffSta_05 "SSPC5通断状态";
CM_ SG_ 2417426448 RPDU1_B2_SSPC_DianHuErr_05 "SSPC5电弧故障状态";
CM_ SG_ 2417426448 BackUp037 "预留";
CM_ SG_ 2417360912 RPDU1_B2_SSPC_I_Load_04 "SSPC4通道电流";
CM_ SG_ 2417360912 RPDU1_B2_SSPC_TripSta_04 "SSPC4跳闸状态";
CM_ SG_ 2417360912 RPDU1_B2_SSPC_BitErr_04 "SSPC4通断周期自检状态";
CM_ SG_ 2417360912 RPDU1_B2_SSPC_OnOffSta_04 "SSPC4通断状态";
CM_ SG_ 2417360912 RPDU1_B2_SSPC_DianHuErr_04 "SSPC4电弧故障状态";
CM_ SG_ 2417360912 BackUp036 "预留";
CM_ SG_ 2417360912 RPDU1_B2_SSPC_I_Load_03 "SSPC3通道电流";
CM_ SG_ 2417360912 RPDU1_B2_SSPC_TripSta_03 "SSPC3跳闸状态";
CM_ SG_ 2417360912 RPDU1_B2_SSPC_BitErr_03 "SSPC3通断周期自检状态";
CM_ SG_ 2417360912 RPDU1_B2_SSPC_OnOffSta_03 "SSPC3通断状态";
CM_ SG_ 2417360912 RPDU1_B2_SSPC_DianHuErr_03 "SSPC3电弧故障状态";
CM_ SG_ 2417360912 BackUp035 "预留";
CM_ SG_ 2417360912 RPDU1_B2_SSPC_I_Load_02 "SSPC2通道电流";
CM_ SG_ 2417360912 RPDU1_B2_SSPC_TripSta_02 "SSPC2跳闸状态";
CM_ SG_ 2417360912 RPDU1_B2_SSPC_BitErr_02 "SSPC2通断周期自检状态";
CM_ SG_ 2417360912 RPDU1_B2_SSPC_OnOffSta_02 "SSPC2通断状态";
CM_ SG_ 2417360912 RPDU1_B2_SSPC_DianHuErr_02 "SSPC2电弧故障状态";
CM_ SG_ 2417360912 BackUp034 "预留";
CM_ SG_ 2417360912 RPDU1_B2_SSPC_I_Load_01 "SSPC1通道电流";
CM_ SG_ 2417360912 RPDU1_B2_SSPC_TripSta_01 "SSPC1跳闸状态";
CM_ SG_ 2417360912 RPDU1_B2_SSPC_BitErr_01 "SSPC1通断周期自检状态";
CM_ SG_ 2417360912 RPDU1_B2_SSPC_OnOffSta_01 "SSPC1通断状态";
CM_ SG_ 2417360912 RPDU1_B2_SSPC_DianHuErr_01 "SSPC1电弧故障状态";
CM_ SG_ 2417360912 BackUp033 "预留";
CM_ SG_ 2417295376 BackUp032 "预留";
CM_ SG_ 2417295376 BackUp031 "预留";
CM_ SG_ 2417295376 BackUp030 "预留";
CM_ SG_ 2417295376 BackUp029 "预留";
CM_ SG_ 2417295376 RPDU1_B1_SSPC_I_Load_18 "SSPC18通道电流";
CM_ SG_ 2417295376 RPDU1_B1_SSPC_TripSta_18 "SSPC18跳闸状态";
CM_ SG_ 2417295376 RPDU1_B1_SSPC_BitErr_18 "SSPC18通断周期自检状态";
CM_ SG_ 2417295376 RPDU1_B1_SSPC_OnOffSta_18 "SSPC18通断状态";
CM_ SG_ 2417295376 RPDU1_B1_SSPC_DianHuErr_18 "SSPC18电弧故障状态";
CM_ SG_ 2417295376 BackUp028 "预留";
CM_ SG_ 2417295376 RPDU1_B1_SSPC_I_Load_17 "SSPC17通道电流";
CM_ SG_ 2417295376 RPDU1_B1_SSPC_TripSta_17 "SSPC17跳闸状态";
CM_ SG_ 2417295376 RPDU1_B1_SSPC_BitErr_17 "SSPC17通断周期自检状态";
CM_ SG_ 2417295376 RPDU1_B1_SSPC_OnOffSta_17 "SSPC17通断状态";
CM_ SG_ 2417295376 RPDU1_B1_SSPC_DianHuErr_17 "SSPC17电弧故障状态";
CM_ SG_ 2417295376 BackUp027 "预留";
CM_ SG_ 2417229840 RPDU1_B1_SSPC_I_Load_16 "SSPC16通道电流";
CM_ SG_ 2417229840 RPDU1_B1_SSPC_TripSta_16 "SSPC16跳闸状态";
CM_ SG_ 2417229840 RPDU1_B1_SSPC_BitErr_16 "SSPC16通断周期自检状态";
CM_ SG_ 2417229840 RPDU1_B1_SSPC_OnOffSta_16 "SSPC16通断状态";
CM_ SG_ 2417229840 RPDU1_B1_SSPC_DianHuErr_16 "SSPC16电弧故障状态";
CM_ SG_ 2417229840 BackUp026 "预留";
CM_ SG_ 2417229840 RPDU1_B1_SSPC_I_Load_15 "SSPC15通道电流";
CM_ SG_ 2417229840 RPDU1_B1_SSPC_TripSta_15 "SSPC15跳闸状态";
CM_ SG_ 2417229840 RPDU1_B1_SSPC_BitErr_15 "SSPC15通断周期自检状态";
CM_ SG_ 2417229840 RPDU1_B1_SSPC_OnOffSta_15 "SSPC15通断状态";
CM_ SG_ 2417229840 RPDU1_B1_SSPC_DianHuErr_15 "SSPC15电弧故障状态";
CM_ SG_ 2417229840 BackUp025 "预留";
CM_ SG_ 2417229840 RPDU1_B1_SSPC_I_Load_14 "SSPC14通道电流";
CM_ SG_ 2417229840 RPDU1_B1_SSPC_TripSta_14 "SSPC14跳闸状态";
CM_ SG_ 2417229840 RPDU1_B1_SSPC_BitErr_14 "SSPC14通断周期自检状态";
CM_ SG_ 2417229840 RPDU1_B1_SSPC_OnOffSta_14 "SSPC14通断状态";
CM_ SG_ 2417229840 RPDU1_B1_SSPC_DianHuErr_14 "SSPC14电弧故障状态";
CM_ SG_ 2417229840 BackUp024 "预留";
CM_ SG_ 2417229840 RPDU1_B1_SSPC_I_Load_13 "SSPC13通道电流";
CM_ SG_ 2417229840 RPDU1_B1_SSPC_TripSta_13 "SSPC13跳闸状态";
CM_ SG_ 2417229840 RPDU1_B1_SSPC_BitErr_13 "SSPC13通断周期自检状态";
CM_ SG_ 2417229840 RPDU1_B1_SSPC_OnOffSta_13 "SSPC13通断状态";
CM_ SG_ 2417229840 RPDU1_B1_SSPC_DianHuErr_13 "SSPC13电弧故障状态";
CM_ SG_ 2417229840 BackUp023 "预留";
CM_ SG_ 2417164304 RPDU1_B1_SSPC_I_Load_12 "SSPC12通道电流";
CM_ SG_ 2417164304 RPDU1_B1_SSPC_TripSta_12 "SSPC12跳闸状态";
CM_ SG_ 2417164304 RPDU1_B1_SSPC_BitErr_12 "SSPC12通断周期自检状态";
CM_ SG_ 2417164304 RPDU1_B1_SSPC_OnOffSta_12 "SSPC12通断状态";
CM_ SG_ 2417164304 RPDU1_B1_SSPC_DianHuErr_12 "SSPC12电弧故障状态";
CM_ SG_ 2417164304 BackUp022 "预留";
CM_ SG_ 2417164304 RPDU1_B1_SSPC_I_Load_11 "SSPC11通道电流";
CM_ SG_ 2417164304 RPDU1_B1_SSPC_TripSta_11 "SSPC11跳闸状态";
CM_ SG_ 2417164304 RPDU1_B1_SSPC_BitErr_11 "SSPC11通断周期自检状态";
CM_ SG_ 2417164304 RPDU1_B1_SSPC_OnOffSta_11 "SSPC11通断状态";
CM_ SG_ 2417164304 RPDU1_B1_SSPC_DianHuErr_11 "SSPC11电弧故障状态";
CM_ SG_ 2417164304 BackUp021 "预留";
CM_ SG_ 2417164304 RPDU1_B1_SSPC_I_Load_10 "SSPC10通道电流";
CM_ SG_ 2417164304 RPDU1_B1_SSPC_TripSta_10 "SSPC10跳闸状态";
CM_ SG_ 2417164304 RPDU1_B1_SSPC_BitErr_10 "SSPC10通断周期自检状态";
CM_ SG_ 2417164304 RPDU1_B1_SSPC_OnOffSta_10 "SSPC10通断状态";
CM_ SG_ 2417164304 RPDU1_B1_SSPC_DianHuErr_10 "SSPC10电弧故障状态";
CM_ SG_ 2417164304 BackUp020 "预留";
CM_ SG_ 2417164304 RPDU1_B1_SSPC_I_Load_09 "SSPC9通道电流";
CM_ SG_ 2417164304 RPDU1_B1_SSPC_TripSta_09 "SSPC9跳闸状态";
CM_ SG_ 2417164304 RPDU1_B1_SSPC_BitErr_09 "SSPC9通断周期自检状态";
CM_ SG_ 2417164304 RPDU1_B1_SSPC_OnOffSta_09 "SSPC9通断状态";
CM_ SG_ 2417164304 RPDU1_B1_SSPC_DianHuErr_09 "SSPC9电弧故障状态";
CM_ SG_ 2417164304 BackUp019 "预留";
CM_ SG_ 2417098768 RPDU1_B1_SSPC_I_Load_08 "SSPC8通道电流";
CM_ SG_ 2417098768 RPDU1_B1_SSPC_TripSta_08 "SSPC8跳闸状态";
CM_ SG_ 2417098768 RPDU1_B1_SSPC_BitErr_08 "SSPC8通断周期自检状态";
CM_ SG_ 2417098768 RPDU1_B1_SSPC_OnOffSta_08 "SSPC8通断状态";
CM_ SG_ 2417098768 RPDU1_B1_SSPC_DianHuErr_08 "SSPC8电弧故障状态";
CM_ SG_ 2417098768 BackUp018 "预留";
CM_ SG_ 2417098768 RPDU1_B1_SSPC_I_Load_07 "SSPC7通道电流";
CM_ SG_ 2417098768 RPDU1_B1_SSPC_TripSta_07 "SSPC7跳闸状态";
CM_ SG_ 2417098768 RPDU1_B1_SSPC_BitErr_07 "SSPC7通断周期自检状态";
CM_ SG_ 2417098768 RPDU1_B1_SSPC_OnOffSta_07 "SSPC7通断状态";
CM_ SG_ 2417098768 RPDU1_B1_SSPC_DianHuErr_07 "SSPC7电弧故障状态";
CM_ SG_ 2417098768 BackUp017 "预留";
CM_ SG_ 2417098768 RPDU1_B1_SSPC_I_Load_06 "SSPC6通道电流";
CM_ SG_ 2417098768 RPDU1_B1_SSPC_TripSta_06 "SSPC6跳闸状态";
CM_ SG_ 2417098768 RPDU1_B1_SSPC_BitErr_06 "SSPC6通断周期自检状态";
CM_ SG_ 2417098768 RPDU1_B1_SSPC_OnOffSta_06 "SSPC6通断状态";
CM_ SG_ 2417098768 RPDU1_B1_SSPC_DianHuErr_06 "SSPC6电弧故障状态";
CM_ SG_ 2417098768 BackUp016 "预留";
CM_ SG_ 2417098768 RPDU1_B1_SSPC_I_Load_05 "SSPC5通道电流";
CM_ SG_ 2417098768 RPDU1_B1_SSPC_TripSta_05 "SSPC5跳闸状态";
CM_ SG_ 2417098768 RPDU1_B1_SSPC_BitErr_05 "SSPC5通断周期自检状态";
CM_ SG_ 2417098768 RPDU1_B1_SSPC_OnOffSta_05 "SSPC5通断状态";
CM_ SG_ 2417098768 RPDU1_B1_SSPC_DianHuErr_05 "SSPC5电弧故障状态";
CM_ SG_ 2417098768 BackUp015 "预留";
CM_ SG_ 2417033232 RPDU1_B1_SSPC_I_Load_04 "SSPC4通道电流";
CM_ SG_ 2417033232 RPDU1_B1_SSPC_TripSta_04 "SSPC4跳闸状态";
CM_ SG_ 2417033232 RPDU1_B1_SSPC_BitErr_04 "SSPC4通断周期自检状态";
CM_ SG_ 2417033232 RPDU1_B1_SSPC_OnOffSta_04 "SSPC4通断状态";
CM_ SG_ 2417033232 RPDU1_B1_SSPC_DianHuErr_04 "SSPC4电弧故障状态";
CM_ SG_ 2417033232 BackUp014 "预留";
CM_ SG_ 2417033232 RPDU1_B1_SSPC_I_Load_03 "SSPC3通道电流";
CM_ SG_ 2417033232 RPDU1_B1_SSPC_TripSta_03 "SSPC3跳闸状态";
CM_ SG_ 2417033232 RPDU1_B1_SSPC_BitErr_03 "SSPC3通断周期自检状态";
CM_ SG_ 2417033232 RPDU1_B1_SSPC_OnOffSta_03 "SSPC3通断状态";
CM_ SG_ 2417033232 RPDU1_B1_SSPC_DianHuErr_03 "SSPC3电弧故障状态";
CM_ SG_ 2417033232 BackUp013 "预留";
CM_ SG_ 2417033232 RPDU1_B1_SSPC_I_Load_02 "SSPC2通道电流";
CM_ SG_ 2417033232 RPDU1_B1_SSPC_TripSta_02 "SSPC2跳闸状态";
CM_ SG_ 2417033232 RPDU1_B1_SSPC_BitErr_02 "SSPC2通断周期自检状态";
CM_ SG_ 2417033232 RPDU1_B1_SSPC_OnOffSta_02 "SSPC2通断状态";
CM_ SG_ 2417033232 RPDU1_B1_SSPC_DianHuErr_02 "SSPC2电弧故障状态";
CM_ SG_ 2417033232 BackUp012 "预留";
CM_ SG_ 2417033232 RPDU1_B1_SSPC_I_Load_01 "SSPC1通道电流";
CM_ SG_ 2417033232 RPDU1_B1_SSPC_TripSta_01 "SSPC1跳闸状态";
CM_ SG_ 2417033232 RPDU1_B1_SSPC_BitErr_01 "SSPC1通断周期自检状态";
CM_ SG_ 2417033232 RPDU1_B1_SSPC_OnOffSta_01 "SSPC1通断状态";
CM_ SG_ 2417033232 RPDU1_B1_SSPC_DianHuErr_01 "SSPC1电弧故障状态";
CM_ SG_ 2417033232 BackUp011 "预留";
CM_ SG_ 2416967696 BackUp010 "预留";
CM_ SG_ 2416967696 L_TouChuan_DCDC_DDCSta "DDC 接触器状态信号";
CM_ SG_ 2416967696 L_TouChuan_DCDC_DDCCtrl "DDC 接触器控制信号";
CM_ SG_ 2416967696 L_TouChuan_DCDC_FanWarn "风扇异常告警";
CM_ SG_ 2416967696 L_TouChuan_DCDC_ConnStaErr "输出接触器状态故障";
CM_ SG_ 2416967696 L_TouChuan_DCDC_HardOutOverErr "硬件输出过压故障";
CM_ SG_ 2416967696 L_TouChuan_DCDC_TOverErr "过温故障";
CM_ SG_ 2416967696 L_TouChuan_DCDC_TOverWarn "过温告警";
CM_ SG_ 2416967696 L_TouChuan_DCDC_OutILimitErr "输出限流故障";
CM_ SG_ 2416967696 L_TouChuan_DCDC_OutIOverErr "输出过流故障";
CM_ SG_ 2416967696 L_TouChuan_DCDC_OutPowOverErr "输出过压故障";
CM_ SG_ 2416967696 L_TouChuan_DCDC_OutPowLowErr "输出欠压故障";
CM_ SG_ 2416967696 L_TouChuan_DCDC_OutPowLowWarn "输出电压低告警";
CM_ SG_ 2416967696 L_TouChuan_DCDC_InPowLowErr "输入欠压故障";
CM_ SG_ 2416902160 BackUp009 "预留";
CM_ SG_ 2416902160 BackUp008 "预留";
CM_ SG_ 2416902160 BackUp007 "预留";
CM_ SG_ 2416902160 L_TouChuan_DCDC_12_2U "二次电源12V-2";
CM_ SG_ 2416836624 L_TouChuan_DCDC_12_1U "二次电源12V-1";
CM_ SG_ 2416836624 L_TouChuan_DCDC_5_U "二次电源5V电压";
CM_ SG_ 2416836624 L_TouChuan_DCDC_270To28_U "270V转28V电压";
CM_ SG_ 2416836624 L_TouChuan_DCDC_In_28U "28V输入电压";
CM_ SG_ 2416771088 L_TouChuan_DCDC_T "产品内部温度";
CM_ SG_ 2416771088 L_TouChuan_DCDC_Out_I "输出电流";
CM_ SG_ 2416771088 L_TouChuan_DCDC_Out_U "输出电压";
CM_ SG_ 2416771088 L_TouChuan_DCDC_In_U "输入电压";
CM_ SG_ 2416705552 L_DCDC_Ver_D "版本号段D";
CM_ SG_ 2416705552 L_DCDC_Ver_C "版本号段C";
CM_ SG_ 2416705552 L_DCDC_Ver_B "版本号段B";
CM_ SG_ 2416705552 L_DCDC_Ver_A "版本号段A";
CM_ SG_ 2416574480 L_MCU_Ver_Day "日期";
CM_ SG_ 2416574480 L_MCU_Ver_Month "月份";
CM_ SG_ 2416574480 L_MCU_Ver_Year "年份";
CM_ SG_ 2416574480 L_MCU_Ver_D "版本号段D";
CM_ SG_ 2416574480 L_MCU_Ver_C "版本号段C";
CM_ SG_ 2416574480 L_MCU_Ver_B "版本号段B";
CM_ SG_ 2416574480 L_MCU_Ver_A "版本号段A";
CM_ SG_ 2416508944 BackUp006 "预留";
CM_ SG_ 2416508944 L_DuanLuQi_Sta_49 "断路器49状态";
CM_ SG_ 2416508944 L_DuanLuQi_Sta_48 "断路器48状态";
CM_ SG_ 2416508944 L_DuanLuQi_Sta_47 "断路器47状态";
CM_ SG_ 2416508944 L_DuanLuQi_Sta_46 "断路器46状态";
CM_ SG_ 2416508944 L_DuanLuQi_Sta_45 "断路器45状态";
CM_ SG_ 2416508944 L_DuanLuQi_Sta_44 "断路器44状态";
CM_ SG_ 2416508944 L_DuanLuQi_Sta_43 "断路器43状态";
CM_ SG_ 2416508944 L_DuanLuQi_Sta_42 "断路器42状态";
CM_ SG_ 2416508944 L_DuanLuQi_Sta_41 "断路器41状态";
CM_ SG_ 2416508944 L_DuanLuQi_Sta_40 "断路器40状态";
CM_ SG_ 2416508944 L_DuanLuQi_Sta_39 "断路器39状态";
CM_ SG_ 2416508944 L_DuanLuQi_Sta_38 "断路器38状态";
CM_ SG_ 2416508944 L_DuanLuQi_Sta_37 "断路器37状态";
CM_ SG_ 2416508944 L_DuanLuQi_Sta_36 "断路器36状态";
CM_ SG_ 2416508944 L_DuanLuQi_Sta_35 "断路器35状态";
CM_ SG_ 2416508944 L_DuanLuQi_Sta_34 "断路器34状态";
CM_ SG_ 2416508944 L_DuanLuQi_Sta_33 "断路器33状态";
CM_ SG_ 2416508944 L_DuanLuQi_Sta_32 "断路器32状态";
CM_ SG_ 2416508944 L_DuanLuQi_Sta_31 "断路器31状态";
CM_ SG_ 2416508944 L_DuanLuQi_Sta_30 "断路器30状态";
CM_ SG_ 2416508944 L_DuanLuQi_Sta_29 "断路器29状态";
CM_ SG_ 2416508944 L_DuanLuQi_Sta_28 "断路器28状态";
CM_ SG_ 2416508944 L_DuanLuQi_Sta_27 "断路器27状态";
CM_ SG_ 2416508944 L_DuanLuQi_Sta_26 "断路器26状态";
CM_ SG_ 2416508944 L_DuanLuQi_Sta_25 "断路器25状态";
CM_ SG_ 2416508944 L_DuanLuQi_Sta_24 "断路器24状态";
CM_ SG_ 2416508944 L_DuanLuQi_Sta_23 "断路器23状态";
CM_ SG_ 2416508944 L_DuanLuQi_Sta_22 "断路器22状态";
CM_ SG_ 2416508944 L_DuanLuQi_Sta_21 "断路器21状态";
CM_ SG_ 2416508944 L_DuanLuQi_Sta_20 "断路器20状态";
CM_ SG_ 2416508944 L_DuanLuQi_Sta_19 "断路器19状态";
CM_ SG_ 2416508944 L_DuanLuQi_Sta_18 "断路器18状态";
CM_ SG_ 2416508944 L_DuanLuQi_Sta_17 "断路器17状态";
CM_ SG_ 2416508944 L_DuanLuQi_Sta_16 "断路器16状态";
CM_ SG_ 2416508944 L_DuanLuQi_Sta_15 "断路器15状态";
CM_ SG_ 2416508944 L_DuanLuQi_Sta_14 "断路器14状态";
CM_ SG_ 2416508944 L_DuanLuQi_Sta_13 "断路器13状态";
CM_ SG_ 2416508944 L_DuanLuQi_Sta_12 "断路器12状态";
CM_ SG_ 2416508944 L_DuanLuQi_Sta_11 "断路器11状态";
CM_ SG_ 2416508944 L_DuanLuQi_Sta_10 "断路器10状态";
CM_ SG_ 2416508944 L_DuanLuQi_Sta_09 "断路器9状态";
CM_ SG_ 2416508944 L_DuanLuQi_Sta_08 "断路器8状态";
CM_ SG_ 2416508944 L_DuanLuQi_Sta_07 "断路器7状态";
CM_ SG_ 2416508944 L_DuanLuQi_Sta_06 "断路器6状态";
CM_ SG_ 2416508944 L_DuanLuQi_Sta_05 "断路器5状态";
CM_ SG_ 2416508944 L_DuanLuQi_Sta_04 "断路器4状态";
CM_ SG_ 2416508944 L_DuanLuQi_Sta_03 "断路器3状态";
CM_ SG_ 2416508944 L_DuanLuQi_Sta_02 "断路器2状态";
CM_ SG_ 2416508944 L_DuanLuQi_Sta_01 "断路器1状态";
CM_ SG_ 2416443408 BackUp005 "预留";
CM_ SG_ 2416443408 L_LE28IOver "L/E 28V DC汇流条转换电流状态";
CM_ SG_ 2416443408 L_LR28IOver "L/R 28V DC汇流条转换电流状态";
CM_ SG_ 2416443408 L_HLT281IOver "L 28 DC汇流条1输入电流状态";
CM_ SG_ 2416443408 L_HLT282IOver "L 28 DC汇流条2输入电流状态";
CM_ SG_ 2416443408 L_LE270IOver "L/E 270 DC汇流条转换电流状态";
CM_ SG_ 2416443408 L_LR270IOver "L/R 270 DC汇流条转换电流状态";
CM_ SG_ 2416443408 L_HLT270IOver "L 270 DC汇流条输入电流状态";
CM_ SG_ 2416443408 BackUp004 "预留";
CM_ SG_ 2416443408 L_HOTBBUSta "HOTBB汇流条电压状态";
CM_ SG_ 2416443408 L_HLT281USta "L 28 DC汇流条2电压状态";
CM_ SG_ 2416443408 L_HLT282USta "L 28 DC汇流条1电压状态";
CM_ SG_ 2416443408 L_DCDC28OutUSta "L 270-28 DCDC变换器输出电源电压状态";
CM_ SG_ 2416443408 L_DCDC270InUSta "L 270-28 DCDC变换器输入电源电压状态";
CM_ SG_ 2416443408 L_HLT270USta "L 270 DC汇流条电压状态";
CM_ SG_ 2416443408 L_Batter270USta "L 270电池输入电压状态";
CM_ SG_ 2416443408 BackUp003 "预留";
CM_ SG_ 2416443408 L_Heart_BIT "主备心跳自检";
CM_ SG_ 2416443408 L_ZBUART_BIT "主备通讯自检";
CM_ SG_ 2416443408 L_ADCIN_BIT "模拟量采集电路自检";
CM_ SG_ 2416443408 L_GpioIN_BIT "离散量采集电路自检";
CM_ SG_ 2416443408 L_Flash_BIT "存储电路自检";
CM_ SG_ 2416443408 L_UART_BIT "RS422总线自检";
CM_ SG_ 2416443408 L_IntCAN2_BIT "内部CAN总线2自检";
CM_ SG_ 2416443408 L_IntCAN1_BIT "内部CAN总线1自检";
CM_ SG_ 2416443408 L_ExtCAN_BIT "外部CAN总线自检";
CM_ SG_ 2416443408 L_CPU_BIT "主处理器自检";
CM_ SG_ 2416443408 L_Pow_BIT "电源电路自检";
CM_ SG_ 2416377872 LTSSR_STA "LTSSR状态";
CM_ SG_ 2416377872 EBC_STA_L "EBC接触器状态";
CM_ SG_ 2416377872 LTR_STA "LTR接触器状态";
CM_ SG_ 2416377872 LETC1_STA "LETC1接触器状态";
CM_ SG_ 2416377872 BTC2_STA "BTC2接触器状态";
CM_ SG_ 2416377872 LDC2_STA "LDC2接触器状态";
CM_ SG_ 2416377872 LETR_STA "LETR接触器状态";
CM_ SG_ 2416377872 LBC_STA "LBC接触器状态";
CM_ SG_ 2416312336 BackUp002 "预留";
CM_ SG_ 2416312336 BackUp001 "预留";
CM_ SG_ 2416312336 LTSSR_U "LTSSR后端电压";
CM_ SG_ 2416312336 LE28_HLT_ZH_U "L/E 28V DC汇流条转换电压";
CM_ SG_ 2416246800 LR28_HLT1_ZH_U "L/R 28V DC汇流条1转换电压";
CM_ SG_ 2416246800 L28_HLT2_U "L 28 DC汇流条2电压";
CM_ SG_ 2416246800 L28_HLT1_U "L 28 DC汇流条1电压";
CM_ SG_ 2416246800 L_DCDC_Out_U "L 270-28 DCDC变换器输出电源电压";
CM_ SG_ 2416181264 L_DCDC_In_U "L 270-28 DCD变换器输入电源电压";
CM_ SG_ 2416181264 LE270_HLT_ZH_U "L/E 270 DC汇流条转换电压";
CM_ SG_ 2416181264 LR270_HLT_ZH_U "L/R 270 DC汇流条转换电压";
CM_ SG_ 2416181264 L270_HLT_U "L 270 DC汇流条电压";
CM_ SG_ 2416115728 L270_Batter_U "L 270电池输入电压";
CM_ SG_ 2416115728 L_HOTBB_HLT_U "HOTBB汇流条电压";
CM_ SG_ 2416115728 L_E28_HLT_U "E 28 DC汇流条电压";
CM_ SG_ 2416115728 L_E270_HLT_U "E 270 DC汇流条电压";
CM_ SG_ 2416050192 LTSSR_I "LTSSR电流";
CM_ SG_ 2416050192 LE28_HLT_ZH_I "L/E 28V DC汇流条转换电流";
CM_ SG_ 2416050192 LR28_HLT_ZH_I "L/R 28V DC汇流条转换电流";
CM_ SG_ 2416050192 L28_HLT2_In_I "L 28 DC汇流条2输入电流";
CM_ SG_ 2415984656 L28_HLT1_In_I "L 28 DC汇流条1输入电流";
CM_ SG_ 2415984656 LE270_HLT_ZH_I "L/E 270 DC汇流条转换电流";
CM_ SG_ 2415984656 LR270_HLT_ZH_I "L/R 270 DC汇流条转换电流";
CM_ SG_ 2415984656 L270_HLT_In_I "L 270 DC汇流条输入电流";
BA_DEF_ SG_  "GenSigSwitchedByIgnition" ENUM  "No","Yes";
BA_DEF_ SG_  "GenSigFuncType" ENUM  "NoFunction","MsgCounter","CRC-8","XOR","XOR-2","DatedBit","SW-Kl15","CHK","Constant","Protocol","CRC-8-SAE_J1850","CRC-32","DataLength","DataID","MsgCounter16","SOK-Signatur","Cluster";
BA_DEF_ BO_  "MsgType" ENUM  "Application","NM ","NMH","TP2.0","ISO-TP ","BAP","EID","KS","XCP_PRE_CONFIGURED","XCP_RUNTIME_CONFIGURED";
BA_DEF_ BO_  "GenMsgILSupport" ENUM  "No","Yes";
BA_DEF_ BO_  "GenMsgCycleTime" INT 0 65535;
BA_DEF_ BO_  "GenMsgMinAcceptLength" INT 0 8;
BA_DEF_ BO_  "GenMsgSendType" ENUM  "Cyclic","CyclicAndSpontanX","Event";
BA_DEF_ BO_  "CANFD_BRS" ENUM  "0","1";
BA_DEF_ BO_  "VFrameFormat" ENUM  "StandardCAN","ExtendedCAN","reserved","reserved","reserved","reserved","reserved","reserved","reserved","reserved","reserved","reserved","reserved","reserved","StandardCAN_FD","ExtendedCAN_FD";
BA_DEF_ SG_  "GenSigEnvVarType" ENUM  "undef","int","float";
BA_DEF_ SG_  "GenSigSendType" ENUM  "Cyclic","OnWrite","OnWriteWithRepetition","OnChange","OnChangeWithRepetition","IfActive","IfActiveWithRepetition","NoSigSendType","NotUsed","NotUsed","NotUsed","NotUsed","NotUsed";
BA_DEF_ SG_  "GenSigStartValue" FLOAT 0 1215752192;
BA_DEF_DEF_  "GenSigSwitchedByIgnition" "Yes";
BA_DEF_DEF_  "GenSigFuncType" "NoFunction";
BA_DEF_DEF_  "MsgType" "Application";
BA_DEF_DEF_  "GenMsgILSupport" "Yes";
BA_DEF_DEF_  "GenMsgCycleTime" 10;
BA_DEF_DEF_  "GenMsgMinAcceptLength" 8;
BA_DEF_DEF_  "GenMsgSendType" "Cyclic";
BA_DEF_DEF_  "CANFD_BRS" "1";
BA_DEF_DEF_  "VFrameFormat" "StandardCAN";
BA_DEF_DEF_  "GenSigEnvVarType" "undef";
BA_DEF_DEF_  "GenSigSendType" "Cyclic";
BA_DEF_DEF_  "GenSigStartValue" 0;
BA_ "VFrameFormat" BO_ 2419589136 1;
BA_ "GenMsgCycleTime" BO_ 2419589136 400;
BA_ "VFrameFormat" BO_ 2419523600 1;
BA_ "GenMsgCycleTime" BO_ 2419523600 400;
BA_ "VFrameFormat" BO_ 2419458064 1;
BA_ "GenMsgCycleTime" BO_ 2419458064 400;
BA_ "VFrameFormat" BO_ 2419392528 1;
BA_ "GenMsgCycleTime" BO_ 2419392528 400;
BA_ "VFrameFormat" BO_ 2419326992 1;
BA_ "GenMsgCycleTime" BO_ 2419326992 400;
BA_ "VFrameFormat" BO_ 2419261456 1;
BA_ "GenMsgCycleTime" BO_ 2419261456 400;
BA_ "VFrameFormat" BO_ 2419195920 1;
BA_ "GenMsgCycleTime" BO_ 2419195920 400;
BA_ "VFrameFormat" BO_ 2419130384 1;
BA_ "GenMsgCycleTime" BO_ 2419130384 400;
BA_ "VFrameFormat" BO_ 2419064848 1;
BA_ "GenMsgCycleTime" BO_ 2419064848 400;
BA_ "VFrameFormat" BO_ 2418999312 1;
BA_ "GenMsgCycleTime" BO_ 2418999312 400;
BA_ "VFrameFormat" BO_ 2418933776 1;
BA_ "GenMsgCycleTime" BO_ 2418933776 400;
BA_ "VFrameFormat" BO_ 2418868240 1;
BA_ "GenMsgCycleTime" BO_ 2418868240 400;
BA_ "VFrameFormat" BO_ 2418802704 1;
BA_ "GenMsgCycleTime" BO_ 2418802704 400;
BA_ "VFrameFormat" BO_ 2418737168 1;
BA_ "GenMsgCycleTime" BO_ 2418737168 400;
BA_ "VFrameFormat" BO_ 2418671632 1;
BA_ "GenMsgCycleTime" BO_ 2418671632 400;
BA_ "VFrameFormat" BO_ 2418606096 1;
BA_ "GenMsgCycleTime" BO_ 2418606096 400;
BA_ "VFrameFormat" BO_ 2418540560 1;
BA_ "GenMsgCycleTime" BO_ 2418540560 400;
BA_ "VFrameFormat" BO_ 2418475024 1;
BA_ "GenMsgCycleTime" BO_ 2418475024 400;
BA_ "VFrameFormat" BO_ 2418409488 1;
BA_ "GenMsgCycleTime" BO_ 2418409488 400;
BA_ "VFrameFormat" BO_ 2418343952 1;
BA_ "GenMsgCycleTime" BO_ 2418343952 400;
BA_ "VFrameFormat" BO_ 2418278416 1;
BA_ "GenMsgCycleTime" BO_ 2418278416 400;
BA_ "VFrameFormat" BO_ 2418212880 1;
BA_ "GenMsgCycleTime" BO_ 2418212880 400;
BA_ "VFrameFormat" BO_ 2418147344 1;
BA_ "GenMsgCycleTime" BO_ 2418147344 400;
BA_ "VFrameFormat" BO_ 2418081808 1;
BA_ "GenMsgCycleTime" BO_ 2418081808 400;
BA_ "VFrameFormat" BO_ 2418016272 1;
BA_ "GenMsgCycleTime" BO_ 2418016272 400;
BA_ "VFrameFormat" BO_ 2417950736 1;
BA_ "GenMsgCycleTime" BO_ 2417950736 400;
BA_ "VFrameFormat" BO_ 2417885200 1;
BA_ "GenMsgCycleTime" BO_ 2417885200 400;
BA_ "VFrameFormat" BO_ 2417819664 1;
BA_ "GenMsgCycleTime" BO_ 2417819664 400;
BA_ "VFrameFormat" BO_ 2417754128 1;
BA_ "GenMsgCycleTime" BO_ 2417754128 400;
BA_ "VFrameFormat" BO_ 2417688592 1;
BA_ "GenMsgCycleTime" BO_ 2417688592 400;
BA_ "VFrameFormat" BO_ 2417623056 1;
BA_ "GenMsgCycleTime" BO_ 2417623056 400;
BA_ "VFrameFormat" BO_ 2417557520 1;
BA_ "GenMsgCycleTime" BO_ 2417557520 400;
BA_ "VFrameFormat" BO_ 2417491984 1;
BA_ "GenMsgCycleTime" BO_ 2417491984 400;
BA_ "VFrameFormat" BO_ 2417426448 1;
BA_ "GenMsgCycleTime" BO_ 2417426448 400;
BA_ "VFrameFormat" BO_ 2417360912 1;
BA_ "GenMsgCycleTime" BO_ 2417360912 400;
BA_ "VFrameFormat" BO_ 2417295376 1;
BA_ "GenMsgCycleTime" BO_ 2417295376 400;
BA_ "VFrameFormat" BO_ 2417229840 1;
BA_ "GenMsgCycleTime" BO_ 2417229840 400;
BA_ "VFrameFormat" BO_ 2417164304 1;
BA_ "GenMsgCycleTime" BO_ 2417164304 400;
BA_ "VFrameFormat" BO_ 2417098768 1;
BA_ "GenMsgCycleTime" BO_ 2417098768 400;
BA_ "VFrameFormat" BO_ 2417033232 1;
BA_ "GenMsgCycleTime" BO_ 2417033232 400;
BA_ "VFrameFormat" BO_ 2416967696 1;
BA_ "GenMsgCycleTime" BO_ 2416967696 400;
BA_ "VFrameFormat" BO_ 2416902160 1;
BA_ "GenMsgCycleTime" BO_ 2416902160 400;
BA_ "VFrameFormat" BO_ 2416836624 1;
BA_ "GenMsgCycleTime" BO_ 2416836624 400;
BA_ "VFrameFormat" BO_ 2416771088 1;
BA_ "GenMsgCycleTime" BO_ 2416771088 400;
BA_ "VFrameFormat" BO_ 2416705552 1;
BA_ "GenMsgCycleTime" BO_ 2416705552 400;
BA_ "VFrameFormat" BO_ 2416574480 1;
BA_ "GenMsgCycleTime" BO_ 2416574480 400;
BA_ "VFrameFormat" BO_ 2416508944 1;
BA_ "GenMsgCycleTime" BO_ 2416508944 400;
BA_ "VFrameFormat" BO_ 2416443408 1;
BA_ "GenMsgCycleTime" BO_ 2416443408 400;
BA_ "VFrameFormat" BO_ 2416377872 1;
BA_ "GenMsgCycleTime" BO_ 2416377872 400;
BA_ "VFrameFormat" BO_ 2416312336 1;
BA_ "GenMsgCycleTime" BO_ 2416312336 400;
BA_ "VFrameFormat" BO_ 2416246800 1;
BA_ "GenMsgCycleTime" BO_ 2416246800 400;
BA_ "VFrameFormat" BO_ 2416181264 1;
BA_ "GenMsgCycleTime" BO_ 2416181264 400;
BA_ "VFrameFormat" BO_ 2416115728 1;
BA_ "GenMsgCycleTime" BO_ 2416115728 400;
BA_ "VFrameFormat" BO_ 2416050192 1;
BA_ "GenMsgCycleTime" BO_ 2416050192 400;
BA_ "VFrameFormat" BO_ 2415984656 1;
BA_ "GenMsgCycleTime" BO_ 2415984656 400;
BA_ "GenSigStartValue" SG_ 2416574480 L_MCU_Ver_Day 1;
BA_ "GenSigStartValue" SG_ 2416574480 L_MCU_Ver_Month 1;
VAL_ 2419589136 RPDU3_B3_SSPC_TripSta_18 1 "短路跳闸" 2 "过流跳闸" 0 "正常" 3 "无定义" ;
VAL_ 2419589136 RPDU3_B3_SSPC_BitErr_18 1 "故障" 0 "正常" ;
VAL_ 2419589136 RPDU3_B3_SSPC_OnOffSta_18 1 "接通" 0 "断开" ;
VAL_ 2419589136 RPDU3_B3_SSPC_DianHuErr_18 1 "有故障" 0 "无故障" ;
VAL_ 2419589136 RPDU3_B3_SSPC_TripSta_17 1 "短路跳闸" 2 "过流跳闸" 0 "正常" 3 "无定义" ;
VAL_ 2419589136 RPDU3_B3_SSPC_BitErr_17 1 "故障" 0 "正常" ;
VAL_ 2419589136 RPDU3_B3_SSPC_OnOffSta_17 1 "接通" 0 "断开" ;
VAL_ 2419589136 RPDU3_B3_SSPC_DianHuErr_17 1 "有故障" 0 "无故障" ;
VAL_ 2419523600 RPDU3_B3_SSPC_TripSta_16 1 "短路跳闸" 2 "过流跳闸" 0 "正常" 3 "无定义" ;
VAL_ 2419523600 RPDU3_B3_SSPC_BitErr_16 1 "故障" 0 "正常" ;
VAL_ 2419523600 RPDU3_B3_SSPC_OnOffSta_16 1 "接通" 0 "断开" ;
VAL_ 2419523600 RPDU3_B3_SSPC_DianHuErr_16 1 "有故障" 0 "无故障" ;
VAL_ 2419523600 RPDU3_B3_SSPC_TripSta_15 1 "短路跳闸" 2 "过流跳闸" 0 "正常" 3 "无定义" ;
VAL_ 2419523600 RPDU3_B3_SSPC_BitErr_15 1 "故障" 0 "正常" ;
VAL_ 2419523600 RPDU3_B3_SSPC_OnOffSta_15 1 "接通" 0 "断开" ;
VAL_ 2419523600 RPDU3_B3_SSPC_DianHuErr_15 1 "有故障" 0 "无故障" ;
VAL_ 2419523600 RPDU3_B3_SSPC_TripSta_14 1 "短路跳闸" 2 "过流跳闸" 0 "正常" 3 "无定义" ;
VAL_ 2419523600 RPDU3_B3_SSPC_BitErr_14 1 "故障" 0 "正常" ;
VAL_ 2419523600 RPDU3_B3_SSPC_OnOffSta_14 1 "接通" 0 "断开" ;
VAL_ 2419523600 RPDU3_B3_SSPC_DianHuErr_14 1 "有故障" 0 "无故障" ;
VAL_ 2419523600 RPDU3_B3_SSPC_TripSta_13 1 "短路跳闸" 2 "过流跳闸" 0 "正常" 3 "无定义" ;
VAL_ 2419523600 RPDU3_B3_SSPC_BitErr_13 1 "故障" 0 "正常" ;
VAL_ 2419523600 RPDU3_B3_SSPC_OnOffSta_13 1 "接通" 0 "断开" ;
VAL_ 2419523600 RPDU3_B3_SSPC_DianHuErr_13 1 "有故障" 0 "无故障" ;
VAL_ 2419458064 RPDU3_B3_SSPC_TripSta_12 1 "短路跳闸" 2 "过流跳闸" 0 "正常" 3 "无定义" ;
VAL_ 2419458064 RPDU3_B3_SSPC_BitErr_12 1 "故障" 0 "正常" ;
VAL_ 2419458064 RPDU3_B3_SSPC_OnOffSta_12 1 "接通" 0 "断开" ;
VAL_ 2419458064 RPDU3_B3_SSPC_DianHuErr_12 1 "有故障" 0 "无故障" ;
VAL_ 2419458064 RPDU3_B3_SSPC_TripSta_11 1 "短路跳闸" 2 "过流跳闸" 0 "正常" 3 "无定义" ;
VAL_ 2419458064 RPDU3_B3_SSPC_BitErr_11 1 "故障" 0 "正常" ;
VAL_ 2419458064 RPDU3_B3_SSPC_OnOffSta_11 1 "接通" 0 "断开" ;
VAL_ 2419458064 RPDU3_B3_SSPC_DianHuErr_11 1 "有故障" 0 "无故障" ;
VAL_ 2419458064 RPDU3_B3_SSPC_TripSta_10 1 "短路跳闸" 2 "过流跳闸" 0 "正常" 3 "无定义" ;
VAL_ 2419458064 RPDU3_B3_SSPC_BitErr_10 1 "故障" 0 "正常" ;
VAL_ 2419458064 RPDU3_B3_SSPC_OnOffSta_10 1 "接通" 0 "断开" ;
VAL_ 2419458064 RPDU3_B3_SSPC_DianHuErr_10 1 "有故障" 0 "无故障" ;
VAL_ 2419458064 RPDU3_B3_SSPC_TripSta_09 1 "短路跳闸" 2 "过流跳闸" 0 "正常" 3 "无定义" ;
VAL_ 2419458064 RPDU3_B3_SSPC_BitErr_09 1 "故障" 0 "正常" ;
VAL_ 2419458064 RPDU3_B3_SSPC_OnOffSta_09 1 "接通" 0 "断开" ;
VAL_ 2419458064 RPDU3_B3_SSPC_DianHuErr_09 1 "有故障" 0 "无故障" ;
VAL_ 2419392528 RPDU3_B3_SSPC_TripSta_08 1 "短路跳闸" 2 "过流跳闸" 0 "正常" 3 "无定义" ;
VAL_ 2419392528 RPDU3_B3_SSPC_BitErr_08 1 "故障" 0 "正常" ;
VAL_ 2419392528 RPDU3_B3_SSPC_OnOffSta_08 1 "接通" 0 "断开" ;
VAL_ 2419392528 RPDU3_B3_SSPC_DianHuErr_08 1 "有故障" 0 "无故障" ;
VAL_ 2419392528 RPDU3_B3_SSPC_TripSta_07 1 "短路跳闸" 2 "过流跳闸" 0 "正常" 3 "无定义" ;
VAL_ 2419392528 RPDU3_B3_SSPC_BitErr_07 1 "故障" 0 "正常" ;
VAL_ 2419392528 RPDU3_B3_SSPC_OnOffSta_07 1 "接通" 0 "断开" ;
VAL_ 2419392528 RPDU3_B3_SSPC_DianHuErr_07 1 "有故障" 0 "无故障" ;
VAL_ 2419392528 RPDU3_B3_SSPC_TripSta_06 1 "短路跳闸" 2 "过流跳闸" 0 "正常" 3 "无定义" ;
VAL_ 2419392528 RPDU3_B3_SSPC_BitErr_06 1 "故障" 0 "正常" ;
VAL_ 2419392528 RPDU3_B3_SSPC_OnOffSta_06 1 "接通" 0 "断开" ;
VAL_ 2419392528 RPDU3_B3_SSPC_DianHuErr_06 1 "有故障" 0 "无故障" ;
VAL_ 2419392528 RPDU3_B3_SSPC_TripSta_05 1 "短路跳闸" 2 "过流跳闸" 0 "正常" 3 "无定义" ;
VAL_ 2419392528 RPDU3_B3_SSPC_BitErr_05 1 "故障" 0 "正常" ;
VAL_ 2419392528 RPDU3_B3_SSPC_OnOffSta_05 1 "接通" 0 "断开" ;
VAL_ 2419392528 RPDU3_B3_SSPC_DianHuErr_05 1 "有故障" 0 "无故障" ;
VAL_ 2419326992 RPDU3_B3_SSPC_TripSta_04 1 "短路跳闸" 2 "过流跳闸" 0 "正常" 3 "无定义" ;
VAL_ 2419326992 RPDU3_B3_SSPC_BitErr_04 1 "故障" 0 "正常" ;
VAL_ 2419326992 RPDU3_B3_SSPC_OnOffSta_04 1 "接通" 0 "断开" ;
VAL_ 2419326992 RPDU3_B3_SSPC_DianHuErr_04 1 "有故障" 0 "无故障" ;
VAL_ 2419326992 RPDU3_B3_SSPC_TripSta_03 1 "短路跳闸" 2 "过流跳闸" 0 "正常" 3 "无定义" ;
VAL_ 2419326992 RPDU3_B3_SSPC_BitErr_03 1 "故障" 0 "正常" ;
VAL_ 2419326992 RPDU3_B3_SSPC_OnOffSta_03 1 "接通" 0 "断开" ;
VAL_ 2419326992 RPDU3_B3_SSPC_DianHuErr_03 1 "有故障" 0 "无故障" ;
VAL_ 2419326992 RPDU3_B3_SSPC_TripSta_02 1 "短路跳闸" 2 "过流跳闸" 0 "正常" 3 "无定义" ;
VAL_ 2419326992 RPDU3_B3_SSPC_BitErr_02 1 "故障" 0 "正常" ;
VAL_ 2419326992 RPDU3_B3_SSPC_OnOffSta_02 1 "接通" 0 "断开" ;
VAL_ 2419326992 RPDU3_B3_SSPC_DianHuErr_02 1 "有故障" 0 "无故障" ;
VAL_ 2419326992 RPDU3_B3_SSPC_TripSta_01 1 "短路跳闸" 2 "过流跳闸" 0 "正常" 3 "无定义" ;
VAL_ 2419326992 RPDU3_B3_SSPC_BitErr_01 1 "故障" 0 "正常" ;
VAL_ 2419326992 RPDU3_B3_SSPC_OnOffSta_01 1 "接通" 0 "断开" ;
VAL_ 2419326992 RPDU3_B3_SSPC_DianHuErr_01 1 "有故障" 0 "无故障" ;
VAL_ 2419261456 RPDU3_B2_SSPC_TripSta_18 1 "短路跳闸" 2 "过流跳闸" 0 "正常" 3 "无定义" ;
VAL_ 2419261456 RPDU3_B2_SSPC_BitErr_18 1 "故障" 0 "正常" ;
VAL_ 2419261456 RPDU3_B2_SSPC_OnOffSta_18 1 "接通" 0 "断开" ;
VAL_ 2419261456 RPDU3_B2_SSPC_DianHuErr_18 1 "有故障" 0 "无故障" ;
VAL_ 2419261456 RPDU3_B2_SSPC_TripSta_17 1 "短路跳闸" 2 "过流跳闸" 0 "正常" 3 "无定义" ;
VAL_ 2419261456 RPDU3_B2_SSPC_BitErr_17 1 "故障" 0 "正常" ;
VAL_ 2419261456 RPDU3_B2_SSPC_OnOffSta_17 1 "接通" 0 "断开" ;
VAL_ 2419261456 RPDU3_B2_SSPC_DianHuErr_17 1 "有故障" 0 "无故障" ;
VAL_ 2419195920 RPDU3_B2_SSPC_TripSta_16 1 "短路跳闸" 2 "过流跳闸" 0 "正常" 3 "无定义" ;
VAL_ 2419195920 RPDU3_B2_SSPC_BitErr_16 1 "故障" 0 "正常" ;
VAL_ 2419195920 RPDU3_B2_SSPC_OnOffSta_16 1 "接通" 0 "断开" ;
VAL_ 2419195920 RPDU3_B2_SSPC_DianHuErr_16 1 "有故障" 0 "无故障" ;
VAL_ 2419195920 RPDU3_B2_SSPC_TripSta_15 1 "短路跳闸" 2 "过流跳闸" 0 "正常" 3 "无定义" ;
VAL_ 2419195920 RPDU3_B2_SSPC_BitErr_15 1 "故障" 0 "正常" ;
VAL_ 2419195920 RPDU3_B2_SSPC_OnOffSta_15 1 "接通" 0 "断开" ;
VAL_ 2419195920 RPDU3_B2_SSPC_DianHuErr_15 1 "有故障" 0 "无故障" ;
VAL_ 2419195920 RPDU3_B2_SSPC_TripSta_14 1 "短路跳闸" 2 "过流跳闸" 0 "正常" 3 "无定义" ;
VAL_ 2419195920 RPDU3_B2_SSPC_BitErr_14 1 "故障" 0 "正常" ;
VAL_ 2419195920 RPDU3_B2_SSPC_OnOffSta_14 1 "接通" 0 "断开" ;
VAL_ 2419195920 RPDU3_B2_SSPC_DianHuErr_14 1 "有故障" 0 "无故障" ;
VAL_ 2419195920 RPDU3_B2_SSPC_TripSta_13 1 "短路跳闸" 2 "过流跳闸" 0 "正常" 3 "无定义" ;
VAL_ 2419195920 RPDU3_B2_SSPC_BitErr_13 1 "故障" 0 "正常" ;
VAL_ 2419195920 RPDU3_B2_SSPC_OnOffSta_13 1 "接通" 0 "断开" ;
VAL_ 2419195920 RPDU3_B2_SSPC_DianHuErr_13 1 "有故障" 0 "无故障" ;
VAL_ 2419130384 RPDU3_B2_SSPC_TripSta_12 1 "短路跳闸" 2 "过流跳闸" 0 "正常" 3 "无定义" ;
VAL_ 2419130384 RPDU3_B2_SSPC_BitErr_12 1 "故障" 0 "正常" ;
VAL_ 2419130384 RPDU3_B2_SSPC_OnOffSta_12 1 "接通" 0 "断开" ;
VAL_ 2419130384 RPDU3_B2_SSPC_DianHuErr_12 1 "有故障" 0 "无故障" ;
VAL_ 2419130384 RPDU3_B2_SSPC_TripSta_11 1 "短路跳闸" 2 "过流跳闸" 0 "正常" 3 "无定义" ;
VAL_ 2419130384 RPDU3_B2_SSPC_BitErr_11 1 "故障" 0 "正常" ;
VAL_ 2419130384 RPDU3_B2_SSPC_OnOffSta_11 1 "接通" 0 "断开" ;
VAL_ 2419130384 RPDU3_B2_SSPC_DianHuErr_11 1 "有故障" 0 "无故障" ;
VAL_ 2419130384 RPDU3_B2_SSPC_TripSta_10 1 "短路跳闸" 2 "过流跳闸" 0 "正常" 3 "无定义" ;
VAL_ 2419130384 RPDU3_B2_SSPC_BitErr_10 1 "故障" 0 "正常" ;
VAL_ 2419130384 RPDU3_B2_SSPC_OnOffSta_10 1 "接通" 0 "断开" ;
VAL_ 2419130384 RPDU3_B2_SSPC_DianHuErr_10 1 "有故障" 0 "无故障" ;
VAL_ 2419130384 RPDU3_B2_SSPC_TripSta_09 1 "短路跳闸" 2 "过流跳闸" 0 "正常" 3 "无定义" ;
VAL_ 2419130384 RPDU3_B2_SSPC_BitErr_09 1 "故障" 0 "正常" ;
VAL_ 2419130384 RPDU3_B2_SSPC_OnOffSta_09 1 "接通" 0 "断开" ;
VAL_ 2419130384 RPDU3_B2_SSPC_DianHuErr_09 1 "有故障" 0 "无故障" ;
VAL_ 2419064848 RPDU3_B2_SSPC_TripSta_08 1 "短路跳闸" 2 "过流跳闸" 0 "正常" 3 "无定义" ;
VAL_ 2419064848 RPDU3_B2_SSPC_BitErr_08 1 "故障" 0 "正常" ;
VAL_ 2419064848 RPDU3_B2_SSPC_OnOffSta_08 1 "接通" 0 "断开" ;
VAL_ 2419064848 RPDU3_B2_SSPC_DianHuErr_08 1 "有故障" 0 "无故障" ;
VAL_ 2419064848 RPDU3_B2_SSPC_TripSta_07 1 "短路跳闸" 2 "过流跳闸" 0 "正常" 3 "无定义" ;
VAL_ 2419064848 RPDU3_B2_SSPC_BitErr_07 1 "故障" 0 "正常" ;
VAL_ 2419064848 RPDU3_B2_SSPC_OnOffSta_07 1 "接通" 0 "断开" ;
VAL_ 2419064848 RPDU3_B2_SSPC_DianHuErr_07 1 "有故障" 0 "无故障" ;
VAL_ 2419064848 RPDU3_B2_SSPC_TripSta_06 1 "短路跳闸" 2 "过流跳闸" 0 "正常" 3 "无定义" ;
VAL_ 2419064848 RPDU3_B2_SSPC_BitErr_06 1 "故障" 0 "正常" ;
VAL_ 2419064848 RPDU3_B2_SSPC_OnOffSta_06 1 "接通" 0 "断开" ;
VAL_ 2419064848 RPDU3_B2_SSPC_DianHuErr_06 1 "有故障" 0 "无故障" ;
VAL_ 2419064848 RPDU3_B2_SSPC_TripSta_05 1 "短路跳闸" 2 "过流跳闸" 0 "正常" 3 "无定义" ;
VAL_ 2419064848 RPDU3_B2_SSPC_BitErr_05 1 "故障" 0 "正常" ;
VAL_ 2419064848 RPDU3_B2_SSPC_OnOffSta_05 1 "接通" 0 "断开" ;
VAL_ 2419064848 RPDU3_B2_SSPC_DianHuErr_05 1 "有故障" 0 "无故障" ;
VAL_ 2418999312 RPDU3_B2_SSPC_TripSta_04 1 "短路跳闸" 2 "过流跳闸" 0 "正常" 3 "无定义" ;
VAL_ 2418999312 RPDU3_B2_SSPC_BitErr_04 1 "故障" 0 "正常" ;
VAL_ 2418999312 RPDU3_B2_SSPC_OnOffSta_04 1 "接通" 0 "断开" ;
VAL_ 2418999312 RPDU3_B2_SSPC_DianHuErr_04 1 "有故障" 0 "无故障" ;
VAL_ 2418999312 RPDU3_B2_SSPC_TripSta_03 1 "短路跳闸" 2 "过流跳闸" 0 "正常" 3 "无定义" ;
VAL_ 2418999312 RPDU3_B2_SSPC_BitErr_03 1 "故障" 0 "正常" ;
VAL_ 2418999312 RPDU3_B2_SSPC_OnOffSta_03 1 "接通" 0 "断开" ;
VAL_ 2418999312 RPDU3_B2_SSPC_DianHuErr_03 1 "有故障" 0 "无故障" ;
VAL_ 2418999312 RPDU3_B2_SSPC_TripSta_02 1 "短路跳闸" 2 "过流跳闸" 0 "正常" 3 "无定义" ;
VAL_ 2418999312 RPDU3_B2_SSPC_BitErr_02 1 "故障" 0 "正常" ;
VAL_ 2418999312 RPDU3_B2_SSPC_OnOffSta_02 1 "接通" 0 "断开" ;
VAL_ 2418999312 RPDU3_B2_SSPC_DianHuErr_02 1 "有故障" 0 "无故障" ;
VAL_ 2418999312 RPDU3_B2_SSPC_TripSta_01 1 "短路跳闸" 2 "过流跳闸" 0 "正常" 3 "无定义" ;
VAL_ 2418999312 RPDU3_B2_SSPC_BitErr_01 1 "故障" 0 "正常" ;
VAL_ 2418999312 RPDU3_B2_SSPC_OnOffSta_01 1 "接通" 0 "断开" ;
VAL_ 2418999312 RPDU3_B2_SSPC_DianHuErr_01 1 "有故障" 0 "无故障" ;
VAL_ 2418933776 RPDU3_B1_SSPC_TripSta_18 1 "短路跳闸" 2 "过流跳闸" 0 "正常" 3 "无定义" ;
VAL_ 2418933776 RPDU3_B1_SSPC_BitErr_18 1 "故障" 0 "正常" ;
VAL_ 2418933776 RPDU3_B1_SSPC_OnOffSta_18 1 "接通" 0 "断开" ;
VAL_ 2418933776 RPDU3_B1_SSPC_DianHuErr_18 1 "有故障" 0 "无故障" ;
VAL_ 2418933776 RPDU3_B1_SSPC_TripSta_17 1 "短路跳闸" 2 "过流跳闸" 0 "正常" 3 "无定义" ;
VAL_ 2418933776 RPDU3_B1_SSPC_BitErr_17 1 "故障" 0 "正常" ;
VAL_ 2418933776 RPDU3_B1_SSPC_OnOffSta_17 1 "接通" 0 "断开" ;
VAL_ 2418933776 RPDU3_B1_SSPC_DianHuErr_17 1 "有故障" 0 "无故障" ;
VAL_ 2418868240 RPDU3_B1_SSPC_TripSta_16 1 "短路跳闸" 2 "过流跳闸" 0 "正常" 3 "无定义" ;
VAL_ 2418868240 RPDU3_B1_SSPC_BitErr_16 1 "故障" 0 "正常" ;
VAL_ 2418868240 RPDU3_B1_SSPC_OnOffSta_16 1 "接通" 0 "断开" ;
VAL_ 2418868240 RPDU3_B1_SSPC_DianHuErr_16 1 "有故障" 0 "无故障" ;
VAL_ 2418868240 RPDU3_B1_SSPC_TripSta_15 1 "短路跳闸" 2 "过流跳闸" 0 "正常" 3 "无定义" ;
VAL_ 2418868240 RPDU3_B1_SSPC_BitErr_15 1 "故障" 0 "正常" ;
VAL_ 2418868240 RPDU3_B1_SSPC_OnOffSta_15 1 "接通" 0 "断开" ;
VAL_ 2418868240 RPDU3_B1_SSPC_DianHuErr_15 1 "有故障" 0 "无故障" ;
VAL_ 2418868240 RPDU3_B1_SSPC_TripSta_14 1 "短路跳闸" 2 "过流跳闸" 0 "正常" 3 "无定义" ;
VAL_ 2418868240 RPDU3_B1_SSPC_BitErr_14 1 "故障" 0 "正常" ;
VAL_ 2418868240 RPDU3_B1_SSPC_OnOffSta_14 1 "接通" 0 "断开" ;
VAL_ 2418868240 RPDU3_B1_SSPC_DianHuErr_14 1 "有故障" 0 "无故障" ;
VAL_ 2418868240 RPDU3_B1_SSPC_TripSta_13 1 "短路跳闸" 2 "过流跳闸" 0 "正常" 3 "无定义" ;
VAL_ 2418868240 RPDU3_B1_SSPC_BitErr_13 1 "故障" 0 "正常" ;
VAL_ 2418868240 RPDU3_B1_SSPC_OnOffSta_13 1 "接通" 0 "断开" ;
VAL_ 2418868240 RPDU3_B1_SSPC_DianHuErr_13 1 "有故障" 0 "无故障" ;
VAL_ 2418802704 RPDU3_B1_SSPC_TripSta_12 1 "短路跳闸" 2 "过流跳闸" 0 "正常" 3 "无定义" ;
VAL_ 2418802704 RPDU3_B1_SSPC_BitErr_12 1 "故障" 0 "正常" ;
VAL_ 2418802704 RPDU3_B1_SSPC_OnOffSta_12 1 "接通" 0 "断开" ;
VAL_ 2418802704 RPDU3_B1_SSPC_DianHuErr_12 1 "有故障" 0 "无故障" ;
VAL_ 2418802704 RPDU3_B1_SSPC_TripSta_11 1 "短路跳闸" 2 "过流跳闸" 0 "正常" 3 "无定义" ;
VAL_ 2418802704 RPDU3_B1_SSPC_BitErr_11 1 "故障" 0 "正常" ;
VAL_ 2418802704 RPDU3_B1_SSPC_OnOffSta_11 1 "接通" 0 "断开" ;
VAL_ 2418802704 RPDU3_B1_SSPC_DianHuErr_11 1 "有故障" 0 "无故障" ;
VAL_ 2418802704 RPDU3_B1_SSPC_TripSta_10 1 "短路跳闸" 2 "过流跳闸" 0 "正常" 3 "无定义" ;
VAL_ 2418802704 RPDU3_B1_SSPC_BitErr_10 1 "故障" 0 "正常" ;
VAL_ 2418802704 RPDU3_B1_SSPC_OnOffSta_10 1 "接通" 0 "断开" ;
VAL_ 2418802704 RPDU3_B1_SSPC_DianHuErr_10 1 "有故障" 0 "无故障" ;
VAL_ 2418802704 RPDU3_B1_SSPC_TripSta_09 1 "短路跳闸" 2 "过流跳闸" 0 "正常" 3 "无定义" ;
VAL_ 2418802704 RPDU3_B1_SSPC_BitErr_09 1 "故障" 0 "正常" ;
VAL_ 2418802704 RPDU3_B1_SSPC_OnOffSta_09 1 "接通" 0 "断开" ;
VAL_ 2418802704 RPDU3_B1_SSPC_DianHuErr_09 1 "有故障" 0 "无故障" ;
VAL_ 2418737168 RPDU3_B1_SSPC_TripSta_08 1 "短路跳闸" 2 "过流跳闸" 0 "正常" 3 "无定义" ;
VAL_ 2418737168 RPDU3_B1_SSPC_BitErr_08 1 "故障" 0 "正常" ;
VAL_ 2418737168 RPDU3_B1_SSPC_OnOffSta_08 1 "接通" 0 "断开" ;
VAL_ 2418737168 RPDU3_B1_SSPC_DianHuErr_08 1 "有故障" 0 "无故障" ;
VAL_ 2418737168 RPDU3_B1_SSPC_TripSta_07 1 "短路跳闸" 2 "过流跳闸" 0 "正常" 3 "无定义" ;
VAL_ 2418737168 RPDU3_B1_SSPC_BitErr_07 1 "故障" 0 "正常" ;
VAL_ 2418737168 RPDU3_B1_SSPC_OnOffSta_07 1 "接通" 0 "断开" ;
VAL_ 2418737168 RPDU3_B1_SSPC_DianHuErr_07 1 "有故障" 0 "无故障" ;
VAL_ 2418737168 RPDU3_B1_SSPC_TripSta_06 1 "短路跳闸" 2 "过流跳闸" 0 "正常" 3 "无定义" ;
VAL_ 2418737168 RPDU3_B1_SSPC_BitErr_06 1 "故障" 0 "正常" ;
VAL_ 2418737168 RPDU3_B1_SSPC_OnOffSta_06 1 "接通" 0 "断开" ;
VAL_ 2418737168 RPDU3_B1_SSPC_DianHuErr_06 1 "有故障" 0 "无故障" ;
VAL_ 2418737168 RPDU3_B1_SSPC_TripSta_05 1 "短路跳闸" 2 "过流跳闸" 0 "正常" 3 "无定义" ;
VAL_ 2418737168 RPDU3_B1_SSPC_BitErr_05 1 "故障" 0 "正常" ;
VAL_ 2418737168 RPDU3_B1_SSPC_OnOffSta_05 1 "接通" 0 "断开" ;
VAL_ 2418737168 RPDU3_B1_SSPC_DianHuErr_05 1 "有故障" 0 "无故障" ;
VAL_ 2418671632 RPDU3_B1_SSPC_TripSta_04 1 "短路跳闸" 2 "过流跳闸" 0 "正常" 3 "无定义" ;
VAL_ 2418671632 RPDU3_B1_SSPC_BitErr_04 1 "故障" 0 "正常" ;
VAL_ 2418671632 RPDU3_B1_SSPC_OnOffSta_04 1 "接通" 0 "断开" ;
VAL_ 2418671632 RPDU3_B1_SSPC_DianHuErr_04 1 "有故障" 0 "无故障" ;
VAL_ 2418671632 RPDU3_B1_SSPC_TripSta_03 1 "短路跳闸" 2 "过流跳闸" 0 "正常" 3 "无定义" ;
VAL_ 2418671632 RPDU3_B1_SSPC_BitErr_03 1 "故障" 0 "正常" ;
VAL_ 2418671632 RPDU3_B1_SSPC_OnOffSta_03 1 "接通" 0 "断开" ;
VAL_ 2418671632 RPDU3_B1_SSPC_DianHuErr_03 1 "有故障" 0 "无故障" ;
VAL_ 2418671632 RPDU3_B1_SSPC_TripSta_02 1 "短路跳闸" 2 "过流跳闸" 0 "正常" 3 "无定义" ;
VAL_ 2418671632 RPDU3_B1_SSPC_BitErr_02 1 "故障" 0 "正常" ;
VAL_ 2418671632 RPDU3_B1_SSPC_OnOffSta_02 1 "接通" 0 "断开" ;
VAL_ 2418671632 RPDU3_B1_SSPC_DianHuErr_02 1 "有故障" 0 "无故障" ;
VAL_ 2418671632 RPDU3_B1_SSPC_TripSta_01 1 "短路跳闸" 2 "过流跳闸" 0 "正常" 3 "无定义" ;
VAL_ 2418671632 RPDU3_B1_SSPC_BitErr_01 1 "故障" 0 "正常" ;
VAL_ 2418671632 RPDU3_B1_SSPC_OnOffSta_01 1 "接通" 0 "断开" ;
VAL_ 2418671632 RPDU3_B1_SSPC_DianHuErr_01 1 "有故障" 0 "无故障" ;
VAL_ 2418540560 RPDU1_B6_SSPC_TripSta_07 1 "短路跳闸" 2 "过流跳闸" 0 "正常" 3 "无定义" ;
VAL_ 2418540560 RPDU1_B6_SSPC_BitErr_07 1 "故障" 0 "正常" ;
VAL_ 2418540560 RPDU1_B6_SSPC_OnOffSta_07 1 "接通" 0 "断开" ;
VAL_ 2418540560 RPDU1_B6_SSPC_DianHuErr_07 1 "有故障" 0 "无故障" ;
VAL_ 2418540560 RPDU1_B6_SSPC_TripSta_06 1 "短路跳闸" 2 "过流跳闸" 0 "正常" 3 "无定义" ;
VAL_ 2418540560 RPDU1_B6_SSPC_BitErr_06 1 "故障" 0 "正常" ;
VAL_ 2418540560 RPDU1_B6_SSPC_OnOffSta_06 1 "接通" 0 "断开" ;
VAL_ 2418540560 RPDU1_B6_SSPC_DianHuErr_06 1 "有故障" 0 "无故障" ;
VAL_ 2418540560 RPDU1_B6_SSPC_TripSta_05 1 "短路跳闸" 2 "过流跳闸" 0 "正常" 3 "无定义" ;
VAL_ 2418540560 RPDU1_B6_SSPC_BitErr_05 1 "故障" 0 "正常" ;
VAL_ 2418540560 RPDU1_B6_SSPC_OnOffSta_05 1 "接通" 0 "断开" ;
VAL_ 2418540560 RPDU1_B6_SSPC_DianHuErr_05 1 "有故障" 0 "无故障" ;
VAL_ 2418475024 RPDU1_B6_SSPC_TripSta_04 1 "短路跳闸" 2 "过流跳闸" 0 "正常" 3 "无定义" ;
VAL_ 2418475024 RPDU1_B6_SSPC_BitErr_04 1 "故障" 0 "正常" ;
VAL_ 2418475024 RPDU1_B6_SSPC_OnOffSta_04 1 "接通" 0 "断开" ;
VAL_ 2418475024 RPDU1_B6_SSPC_DianHuErr_04 1 "有故障" 0 "无故障" ;
VAL_ 2418475024 RPDU1_B6_SSPC_TripSta_03 1 "短路跳闸" 2 "过流跳闸" 0 "正常" 3 "无定义" ;
VAL_ 2418475024 RPDU1_B6_SSPC_BitErr_03 1 "故障" 0 "正常" ;
VAL_ 2418475024 RPDU1_B6_SSPC_OnOffSta_03 1 "接通" 0 "断开" ;
VAL_ 2418475024 RPDU1_B6_SSPC_DianHuErr_03 1 "有故障" 0 "无故障" ;
VAL_ 2418475024 RPDU1_B6_SSPC_TripSta_02 1 "短路跳闸" 2 "过流跳闸" 0 "正常" 3 "无定义" ;
VAL_ 2418475024 RPDU1_B6_SSPC_BitErr_02 1 "故障" 0 "正常" ;
VAL_ 2418475024 RPDU1_B6_SSPC_OnOffSta_02 1 "接通" 0 "断开" ;
VAL_ 2418475024 RPDU1_B6_SSPC_DianHuErr_02 1 "有故障" 0 "无故障" ;
VAL_ 2418475024 RPDU1_B6_SSPC_TripSta_01 1 "短路跳闸" 2 "过流跳闸" 0 "正常" 3 "无定义" ;
VAL_ 2418475024 RPDU1_B6_SSPC_BitErr_01 1 "故障" 0 "正常" ;
VAL_ 2418475024 RPDU1_B6_SSPC_OnOffSta_01 1 "接通" 0 "断开" ;
VAL_ 2418475024 RPDU1_B6_SSPC_DianHuErr_01 1 "有故障" 0 "无故障" ;
VAL_ 2418409488 RPDU1_B5_SSPC_TripSta_07 1 "短路跳闸" 2 "过流跳闸" 0 "正常" 3 "无定义" ;
VAL_ 2418409488 RPDU1_B5_SSPC_BitErr_07 1 "故障" 0 "正常" ;
VAL_ 2418409488 RPDU1_B5_SSPC_OnOffSta_07 1 "接通" 0 "断开" ;
VAL_ 2418409488 RPDU1_B5_SSPC_DianHuErr_07 1 "有故障" 0 "无故障" ;
VAL_ 2418409488 RPDU1_B5_SSPC_TripSta_06 1 "短路跳闸" 2 "过流跳闸" 0 "正常" 3 "无定义" ;
VAL_ 2418409488 RPDU1_B5_SSPC_BitErr_06 1 "故障" 0 "正常" ;
VAL_ 2418409488 RPDU1_B5_SSPC_OnOffSta_06 1 "接通" 0 "断开" ;
VAL_ 2418409488 RPDU1_B5_SSPC_DianHuErr_06 1 "有故障" 0 "无故障" ;
VAL_ 2418409488 RPDU1_B5_SSPC_TripSta_05 1 "短路跳闸" 2 "过流跳闸" 0 "正常" 3 "无定义" ;
VAL_ 2418409488 RPDU1_B5_SSPC_BitErr_05 1 "故障" 0 "正常" ;
VAL_ 2418409488 RPDU1_B5_SSPC_OnOffSta_05 1 "接通" 0 "断开" ;
VAL_ 2418409488 RPDU1_B5_SSPC_DianHuErr_05 1 "有故障" 0 "无故障" ;
VAL_ 2418343952 RPDU1_B5_SSPC_TripSta_04 1 "短路跳闸" 2 "过流跳闸" 0 "正常" 3 "无定义" ;
VAL_ 2418343952 RPDU1_B5_SSPC_BitErr_04 1 "故障" 0 "正常" ;
VAL_ 2418343952 RPDU1_B5_SSPC_OnOffSta_04 1 "接通" 0 "断开" ;
VAL_ 2418343952 RPDU1_B5_SSPC_DianHuErr_04 1 "有故障" 0 "无故障" ;
VAL_ 2418343952 RPDU1_B5_SSPC_TripSta_03 1 "短路跳闸" 2 "过流跳闸" 0 "正常" 3 "无定义" ;
VAL_ 2418343952 RPDU1_B5_SSPC_BitErr_03 1 "故障" 0 "正常" ;
VAL_ 2418343952 RPDU1_B5_SSPC_OnOffSta_03 1 "接通" 0 "断开" ;
VAL_ 2418343952 RPDU1_B5_SSPC_DianHuErr_03 1 "有故障" 0 "无故障" ;
VAL_ 2418343952 RPDU1_B5_SSPC_TripSta_02 1 "短路跳闸" 2 "过流跳闸" 0 "正常" 3 "无定义" ;
VAL_ 2418343952 RPDU1_B5_SSPC_BitErr_02 1 "故障" 0 "正常" ;
VAL_ 2418343952 RPDU1_B5_SSPC_OnOffSta_02 1 "接通" 0 "断开" ;
VAL_ 2418343952 RPDU1_B5_SSPC_DianHuErr_02 1 "有故障" 0 "无故障" ;
VAL_ 2418343952 RPDU1_B5_SSPC_TripSta_01 1 "短路跳闸" 2 "过流跳闸" 0 "正常" 3 "无定义" ;
VAL_ 2418343952 RPDU1_B5_SSPC_BitErr_01 1 "故障" 0 "正常" ;
VAL_ 2418343952 RPDU1_B5_SSPC_OnOffSta_01 1 "接通" 0 "断开" ;
VAL_ 2418343952 RPDU1_B5_SSPC_DianHuErr_01 1 "有故障" 0 "无故障" ;
VAL_ 2418278416 RPDU1_B4_SSPC_TripSta_18 1 "短路跳闸" 2 "过流跳闸" 0 "正常" 3 "无定义" ;
VAL_ 2418278416 RPDU1_B4_SSPC_BitErr_18 1 "故障" 0 "正常" ;
VAL_ 2418278416 RPDU1_B4_SSPC_OnOffSta_18 1 "接通" 0 "断开" ;
VAL_ 2418278416 RPDU1_B4_SSPC_DianHuErr_18 1 "有故障" 0 "无故障" ;
VAL_ 2418278416 RPDU1_B4_SSPC_TripSta_17 1 "短路跳闸" 2 "过流跳闸" 0 "正常" 3 "无定义" ;
VAL_ 2418278416 RPDU1_B4_SSPC_BitErr_17 1 "故障" 0 "正常" ;
VAL_ 2418278416 RPDU1_B4_SSPC_OnOffSta_17 1 "接通" 0 "断开" ;
VAL_ 2418278416 RPDU1_B4_SSPC_DianHuErr_17 1 "有故障" 0 "无故障" ;
VAL_ 2418212880 RPDU1_B4_SSPC_TripSta_16 1 "短路跳闸" 2 "过流跳闸" 0 "正常" 3 "无定义" ;
VAL_ 2418212880 RPDU1_B4_SSPC_BitErr_16 1 "故障" 0 "正常" ;
VAL_ 2418212880 RPDU1_B4_SSPC_OnOffSta_16 1 "接通" 0 "断开" ;
VAL_ 2418212880 RPDU1_B4_SSPC_DianHuErr_16 1 "有故障" 0 "无故障" ;
VAL_ 2418212880 RPDU1_B4_SSPC_TripSta_15 1 "短路跳闸" 2 "过流跳闸" 0 "正常" 3 "无定义" ;
VAL_ 2418212880 RPDU1_B4_SSPC_BitErr_15 1 "故障" 0 "正常" ;
VAL_ 2418212880 RPDU1_B4_SSPC_OnOffSta_15 1 "接通" 0 "断开" ;
VAL_ 2418212880 RPDU1_B4_SSPC_DianHuErr_15 1 "有故障" 0 "无故障" ;
VAL_ 2418212880 RPDU1_B4_SSPC_TripSta_14 1 "短路跳闸" 2 "过流跳闸" 0 "正常" 3 "无定义" ;
VAL_ 2418212880 RPDU1_B4_SSPC_BitErr_14 1 "故障" 0 "正常" ;
VAL_ 2418212880 RPDU1_B4_SSPC_OnOffSta_14 1 "接通" 0 "断开" ;
VAL_ 2418212880 RPDU1_B4_SSPC_DianHuErr_14 1 "有故障" 0 "无故障" ;
VAL_ 2418212880 RPDU1_B4_SSPC_TripSta_13 1 "短路跳闸" 2 "过流跳闸" 0 "正常" 3 "无定义" ;
VAL_ 2418212880 RPDU1_B4_SSPC_BitErr_13 1 "故障" 0 "正常" ;
VAL_ 2418212880 RPDU1_B4_SSPC_OnOffSta_13 1 "接通" 0 "断开" ;
VAL_ 2418212880 RPDU1_B4_SSPC_DianHuErr_13 1 "有故障" 0 "无故障" ;
VAL_ 2418147344 RPDU1_B4_SSPC_TripSta_12 1 "短路跳闸" 2 "过流跳闸" 0 "正常" 3 "无定义" ;
VAL_ 2418147344 RPDU1_B4_SSPC_BitErr_12 1 "故障" 0 "正常" ;
VAL_ 2418147344 RPDU1_B4_SSPC_OnOffSta_12 1 "接通" 0 "断开" ;
VAL_ 2418147344 RPDU1_B4_SSPC_DianHuErr_12 1 "有故障" 0 "无故障" ;
VAL_ 2418147344 RPDU1_B4_SSPC_TripSta_11 1 "短路跳闸" 2 "过流跳闸" 0 "正常" 3 "无定义" ;
VAL_ 2418147344 RPDU1_B4_SSPC_BitErr_11 1 "故障" 0 "正常" ;
VAL_ 2418147344 RPDU1_B4_SSPC_OnOffSta_11 1 "接通" 0 "断开" ;
VAL_ 2418147344 RPDU1_B4_SSPC_DianHuErr_11 1 "有故障" 0 "无故障" ;
VAL_ 2418147344 RPDU1_B4_SSPC_TripSta_10 1 "短路跳闸" 2 "过流跳闸" 0 "正常" 3 "无定义" ;
VAL_ 2418147344 RPDU1_B4_SSPC_BitErr_10 1 "故障" 0 "正常" ;
VAL_ 2418147344 RPDU1_B4_SSPC_OnOffSta_10 1 "接通" 0 "断开" ;
VAL_ 2418147344 RPDU1_B4_SSPC_DianHuErr_10 1 "有故障" 0 "无故障" ;
VAL_ 2418147344 RPDU1_B4_SSPC_TripSta_09 1 "短路跳闸" 2 "过流跳闸" 0 "正常" 3 "无定义" ;
VAL_ 2418147344 RPDU1_B4_SSPC_BitErr_09 1 "故障" 0 "正常" ;
VAL_ 2418147344 RPDU1_B4_SSPC_OnOffSta_09 1 "接通" 0 "断开" ;
VAL_ 2418147344 RPDU1_B4_SSPC_DianHuErr_09 1 "有故障" 0 "无故障" ;
VAL_ 2418081808 RPDU1_B4_SSPC_TripSta_08 1 "短路跳闸" 2 "过流跳闸" 0 "正常" 3 "无定义" ;
VAL_ 2418081808 RPDU1_B4_SSPC_BitErr_08 1 "故障" 0 "正常" ;
VAL_ 2418081808 RPDU1_B4_SSPC_OnOffSta_08 1 "接通" 0 "断开" ;
VAL_ 2418081808 RPDU1_B4_SSPC_DianHuErr_08 1 "有故障" 0 "无故障" ;
VAL_ 2418081808 RPDU1_B4_SSPC_TripSta_07 1 "短路跳闸" 2 "过流跳闸" 0 "正常" 3 "无定义" ;
VAL_ 2418081808 RPDU1_B4_SSPC_BitErr_07 1 "故障" 0 "正常" ;
VAL_ 2418081808 RPDU1_B4_SSPC_OnOffSta_07 1 "接通" 0 "断开" ;
VAL_ 2418081808 RPDU1_B4_SSPC_DianHuErr_07 1 "有故障" 0 "无故障" ;
VAL_ 2418081808 RPDU1_B4_SSPC_TripSta_06 1 "短路跳闸" 2 "过流跳闸" 0 "正常" 3 "无定义" ;
VAL_ 2418081808 RPDU1_B4_SSPC_BitErr_06 1 "故障" 0 "正常" ;
VAL_ 2418081808 RPDU1_B4_SSPC_OnOffSta_06 1 "接通" 0 "断开" ;
VAL_ 2418081808 RPDU1_B4_SSPC_DianHuErr_06 1 "有故障" 0 "无故障" ;
VAL_ 2418081808 RPDU1_B4_SSPC_TripSta_05 1 "短路跳闸" 2 "过流跳闸" 0 "正常" 3 "无定义" ;
VAL_ 2418081808 RPDU1_B4_SSPC_BitErr_05 1 "故障" 0 "正常" ;
VAL_ 2418081808 RPDU1_B4_SSPC_OnOffSta_05 1 "接通" 0 "断开" ;
VAL_ 2418081808 RPDU1_B4_SSPC_DianHuErr_05 1 "有故障" 0 "无故障" ;
VAL_ 2418016272 RPDU1_B4_SSPC_TripSta_04 1 "短路跳闸" 2 "过流跳闸" 0 "正常" 3 "无定义" ;
VAL_ 2418016272 RPDU1_B4_SSPC_BitErr_04 1 "故障" 0 "正常" ;
VAL_ 2418016272 RPDU1_B4_SSPC_OnOffSta_04 1 "接通" 0 "断开" ;
VAL_ 2418016272 RPDU1_B4_SSPC_DianHuErr_04 1 "有故障" 0 "无故障" ;
VAL_ 2418016272 RPDU1_B4_SSPC_TripSta_03 1 "短路跳闸" 2 "过流跳闸" 0 "正常" 3 "无定义" ;
VAL_ 2418016272 RPDU1_B4_SSPC_BitErr_03 1 "故障" 0 "正常" ;
VAL_ 2418016272 RPDU1_B4_SSPC_OnOffSta_03 1 "接通" 0 "断开" ;
VAL_ 2418016272 RPDU1_B4_SSPC_DianHuErr_03 1 "有故障" 0 "无故障" ;
VAL_ 2418016272 RPDU1_B4_SSPC_TripSta_02 1 "短路跳闸" 2 "过流跳闸" 0 "正常" 3 "无定义" ;
VAL_ 2418016272 RPDU1_B4_SSPC_BitErr_02 1 "故障" 0 "正常" ;
VAL_ 2418016272 RPDU1_B4_SSPC_OnOffSta_02 1 "接通" 0 "断开" ;
VAL_ 2418016272 RPDU1_B4_SSPC_DianHuErr_02 1 "有故障" 0 "无故障" ;
VAL_ 2418016272 RPDU1_B4_SSPC_TripSta_01 1 "短路跳闸" 2 "过流跳闸" 0 "正常" 3 "无定义" ;
VAL_ 2418016272 RPDU1_B4_SSPC_BitErr_01 1 "故障" 0 "正常" ;
VAL_ 2418016272 RPDU1_B4_SSPC_OnOffSta_01 1 "接通" 0 "断开" ;
VAL_ 2418016272 RPDU1_B4_SSPC_DianHuErr_01 1 "有故障" 0 "无故障" ;
VAL_ 2417950736 RPDU1_B3_SSPC_TripSta_18 1 "短路跳闸" 2 "过流跳闸" 0 "正常" 3 "无定义" ;
VAL_ 2417950736 RPDU1_B3_SSPC_BitErr_18 1 "故障" 0 "正常" ;
VAL_ 2417950736 RPDU1_B3_SSPC_OnOffSta_18 1 "接通" 0 "断开" ;
VAL_ 2417950736 RPDU1_B3_SSPC_DianHuErr_18 1 "有故障" 0 "无故障" ;
VAL_ 2417950736 RPDU1_B3_SSPC_TripSta_17 1 "短路跳闸" 2 "过流跳闸" 0 "正常" 3 "无定义" ;
VAL_ 2417950736 RPDU1_B3_SSPC_BitErr_17 1 "故障" 0 "正常" ;
VAL_ 2417950736 RPDU1_B3_SSPC_OnOffSta_17 1 "接通" 0 "断开" ;
VAL_ 2417950736 RPDU1_B3_SSPC_DianHuErr_17 1 "有故障" 0 "无故障" ;
VAL_ 2417885200 RPDU1_B3_SSPC_TripSta_16 1 "短路跳闸" 2 "过流跳闸" 0 "正常" 3 "无定义" ;
VAL_ 2417885200 RPDU1_B3_SSPC_BitErr_16 1 "故障" 0 "正常" ;
VAL_ 2417885200 RPDU1_B3_SSPC_OnOffSta_16 1 "接通" 0 "断开" ;
VAL_ 2417885200 RPDU1_B3_SSPC_DianHuErr_16 1 "有故障" 0 "无故障" ;
VAL_ 2417885200 RPDU1_B3_SSPC_TripSta_15 1 "短路跳闸" 2 "过流跳闸" 0 "正常" 3 "无定义" ;
VAL_ 2417885200 RPDU1_B3_SSPC_BitErr_15 1 "故障" 0 "正常" ;
VAL_ 2417885200 RPDU1_B3_SSPC_OnOffSta_15 1 "接通" 0 "断开" ;
VAL_ 2417885200 RPDU1_B3_SSPC_DianHuErr_15 1 "有故障" 0 "无故障" ;
VAL_ 2417885200 RPDU1_B3_SSPC_TripSta_14 1 "短路跳闸" 2 "过流跳闸" 0 "正常" 3 "无定义" ;
VAL_ 2417885200 RPDU1_B3_SSPC_BitErr_14 1 "故障" 0 "正常" ;
VAL_ 2417885200 RPDU1_B3_SSPC_OnOffSta_14 1 "接通" 0 "断开" ;
VAL_ 2417885200 RPDU1_B3_SSPC_DianHuErr_14 1 "有故障" 0 "无故障" ;
VAL_ 2417885200 RPDU1_B3_SSPC_TripSta_13 1 "短路跳闸" 2 "过流跳闸" 0 "正常" 3 "无定义" ;
VAL_ 2417885200 RPDU1_B3_SSPC_BitErr_13 1 "故障" 0 "正常" ;
VAL_ 2417885200 RPDU1_B3_SSPC_OnOffSta_13 1 "接通" 0 "断开" ;
VAL_ 2417885200 RPDU1_B3_SSPC_DianHuErr_13 1 "有故障" 0 "无故障" ;
VAL_ 2417819664 RPDU1_B3_SSPC_TripSta_12 1 "短路跳闸" 2 "过流跳闸" 0 "正常" 3 "无定义" ;
VAL_ 2417819664 RPDU1_B3_SSPC_BitErr_12 1 "故障" 0 "正常" ;
VAL_ 2417819664 RPDU1_B3_SSPC_OnOffSta_12 1 "接通" 0 "断开" ;
VAL_ 2417819664 RPDU1_B3_SSPC_DianHuErr_12 1 "有故障" 0 "无故障" ;
VAL_ 2417819664 RPDU1_B3_SSPC_TripSta_11 1 "短路跳闸" 2 "过流跳闸" 0 "正常" 3 "无定义" ;
VAL_ 2417819664 RPDU1_B3_SSPC_BitErr_11 1 "故障" 0 "正常" ;
VAL_ 2417819664 RPDU1_B3_SSPC_OnOffSta_11 1 "接通" 0 "断开" ;
VAL_ 2417819664 RPDU1_B3_SSPC_DianHuErr_11 1 "有故障" 0 "无故障" ;
VAL_ 2417819664 RPDU1_B3_SSPC_TripSta_10 1 "短路跳闸" 2 "过流跳闸" 0 "正常" 3 "无定义" ;
VAL_ 2417819664 RPDU1_B3_SSPC_BitErr_10 1 "故障" 0 "正常" ;
VAL_ 2417819664 RPDU1_B3_SSPC_OnOffSta_10 1 "接通" 0 "断开" ;
VAL_ 2417819664 RPDU1_B3_SSPC_DianHuErr_10 1 "有故障" 0 "无故障" ;
VAL_ 2417819664 RPDU1_B3_SSPC_TripSta_09 1 "短路跳闸" 2 "过流跳闸" 0 "正常" 3 "无定义" ;
VAL_ 2417819664 RPDU1_B3_SSPC_BitErr_09 1 "故障" 0 "正常" ;
VAL_ 2417819664 RPDU1_B3_SSPC_OnOffSta_09 1 "接通" 0 "断开" ;
VAL_ 2417819664 RPDU1_B3_SSPC_DianHuErr_09 1 "有故障" 0 "无故障" ;
VAL_ 2417754128 RPDU1_B3_SSPC_TripSta_08 1 "短路跳闸" 2 "过流跳闸" 0 "正常" 3 "无定义" ;
VAL_ 2417754128 RPDU1_B3_SSPC_BitErr_08 1 "故障" 0 "正常" ;
VAL_ 2417754128 RPDU1_B3_SSPC_OnOffSta_08 1 "接通" 0 "断开" ;
VAL_ 2417754128 RPDU1_B3_SSPC_DianHuErr_08 1 "有故障" 0 "无故障" ;
VAL_ 2417754128 RPDU1_B3_SSPC_TripSta_07 1 "短路跳闸" 2 "过流跳闸" 0 "正常" 3 "无定义" ;
VAL_ 2417754128 RPDU1_B3_SSPC_BitErr_07 1 "故障" 0 "正常" ;
VAL_ 2417754128 RPDU1_B3_SSPC_OnOffSta_07 1 "接通" 0 "断开" ;
VAL_ 2417754128 RPDU1_B3_SSPC_DianHuErr_07 1 "有故障" 0 "无故障" ;
VAL_ 2417754128 RPDU1_B3_SSPC_TripSta_06 1 "短路跳闸" 2 "过流跳闸" 0 "正常" 3 "无定义" ;
VAL_ 2417754128 RPDU1_B3_SSPC_BitErr_06 1 "故障" 0 "正常" ;
VAL_ 2417754128 RPDU1_B3_SSPC_OnOffSta_06 1 "接通" 0 "断开" ;
VAL_ 2417754128 RPDU1_B3_SSPC_DianHuErr_06 1 "有故障" 0 "无故障" ;
VAL_ 2417754128 RPDU1_B3_SSPC_TripSta_05 1 "短路跳闸" 2 "过流跳闸" 0 "正常" 3 "无定义" ;
VAL_ 2417754128 RPDU1_B3_SSPC_BitErr_05 1 "故障" 0 "正常" ;
VAL_ 2417754128 RPDU1_B3_SSPC_OnOffSta_05 1 "接通" 0 "断开" ;
VAL_ 2417754128 RPDU1_B3_SSPC_DianHuErr_05 1 "有故障" 0 "无故障" ;
VAL_ 2417688592 RPDU1_B3_SSPC_TripSta_04 1 "短路跳闸" 2 "过流跳闸" 0 "正常" 3 "无定义" ;
VAL_ 2417688592 RPDU1_B3_SSPC_BitErr_04 1 "故障" 0 "正常" ;
VAL_ 2417688592 RPDU1_B3_SSPC_OnOffSta_04 1 "接通" 0 "断开" ;
VAL_ 2417688592 RPDU1_B3_SSPC_DianHuErr_04 1 "有故障" 0 "无故障" ;
VAL_ 2417688592 RPDU1_B3_SSPC_TripSta_03 1 "短路跳闸" 2 "过流跳闸" 0 "正常" 3 "无定义" ;
VAL_ 2417688592 RPDU1_B3_SSPC_BitErr_03 1 "故障" 0 "正常" ;
VAL_ 2417688592 RPDU1_B3_SSPC_OnOffSta_03 1 "接通" 0 "断开" ;
VAL_ 2417688592 RPDU1_B3_SSPC_DianHuErr_03 1 "有故障" 0 "无故障" ;
VAL_ 2417688592 RPDU1_B3_SSPC_TripSta_02 1 "短路跳闸" 2 "过流跳闸" 0 "正常" 3 "无定义" ;
VAL_ 2417688592 RPDU1_B3_SSPC_BitErr_02 1 "故障" 0 "正常" ;
VAL_ 2417688592 RPDU1_B3_SSPC_OnOffSta_02 1 "接通" 0 "断开" ;
VAL_ 2417688592 RPDU1_B3_SSPC_DianHuErr_02 1 "有故障" 0 "无故障" ;
VAL_ 2417688592 RPDU1_B3_SSPC_TripSta_01 1 "短路跳闸" 2 "过流跳闸" 0 "正常" 3 "无定义" ;
VAL_ 2417688592 RPDU1_B3_SSPC_BitErr_01 1 "故障" 0 "正常" ;
VAL_ 2417688592 RPDU1_B3_SSPC_OnOffSta_01 1 "接通" 0 "断开" ;
VAL_ 2417688592 RPDU1_B3_SSPC_DianHuErr_01 1 "有故障" 0 "无故障" ;
VAL_ 2417623056 RPDU1_B2_SSPC_TripSta_18 1 "短路跳闸" 2 "过流跳闸" 0 "正常" 3 "无定义" ;
VAL_ 2417623056 RPDU1_B2_SSPC_BitErr_18 1 "故障" 0 "正常" ;
VAL_ 2417623056 RPDU1_B2_SSPC_OnOffSta_18 1 "接通" 0 "断开" ;
VAL_ 2417623056 RPDU1_B2_SSPC_DianHuErr_18 1 "有故障" 0 "无故障" ;
VAL_ 2417623056 RPDU1_B2_SSPC_TripSta_17 1 "短路跳闸" 2 "过流跳闸" 0 "正常" 3 "无定义" ;
VAL_ 2417623056 RPDU1_B2_SSPC_BitErr_17 1 "故障" 0 "正常" ;
VAL_ 2417623056 RPDU1_B2_SSPC_OnOffSta_17 1 "接通" 0 "断开" ;
VAL_ 2417623056 RPDU1_B2_SSPC_DianHuErr_17 1 "有故障" 0 "无故障" ;
VAL_ 2417557520 RPDU1_B2_SSPC_TripSta_16 1 "短路跳闸" 2 "过流跳闸" 0 "正常" 3 "无定义" ;
VAL_ 2417557520 RPDU1_B2_SSPC_BitErr_16 1 "故障" 0 "正常" ;
VAL_ 2417557520 RPDU1_B2_SSPC_OnOffSta_16 1 "接通" 0 "断开" ;
VAL_ 2417557520 RPDU1_B2_SSPC_DianHuErr_16 1 "有故障" 0 "无故障" ;
VAL_ 2417557520 RPDU1_B2_SSPC_TripSta_15 1 "短路跳闸" 2 "过流跳闸" 0 "正常" 3 "无定义" ;
VAL_ 2417557520 RPDU1_B2_SSPC_BitErr_15 1 "故障" 0 "正常" ;
VAL_ 2417557520 RPDU1_B2_SSPC_OnOffSta_15 1 "接通" 0 "断开" ;
VAL_ 2417557520 RPDU1_B2_SSPC_DianHuErr_15 1 "有故障" 0 "无故障" ;
VAL_ 2417557520 RPDU1_B2_SSPC_TripSta_14 1 "短路跳闸" 2 "过流跳闸" 0 "正常" 3 "无定义" ;
VAL_ 2417557520 RPDU1_B2_SSPC_BitErr_14 1 "故障" 0 "正常" ;
VAL_ 2417557520 RPDU1_B2_SSPC_OnOffSta_14 1 "接通" 0 "断开" ;
VAL_ 2417557520 RPDU1_B2_SSPC_DianHuErr_14 1 "有故障" 0 "无故障" ;
VAL_ 2417557520 RPDU1_B2_SSPC_TripSta_13 1 "短路跳闸" 2 "过流跳闸" 0 "正常" 3 "无定义" ;
VAL_ 2417557520 RPDU1_B2_SSPC_BitErr_13 1 "故障" 0 "正常" ;
VAL_ 2417557520 RPDU1_B2_SSPC_OnOffSta_13 1 "接通" 0 "断开" ;
VAL_ 2417557520 RPDU1_B2_SSPC_DianHuErr_13 1 "有故障" 0 "无故障" ;
VAL_ 2417491984 RPDU1_B2_SSPC_TripSta_12 1 "短路跳闸" 2 "过流跳闸" 0 "正常" 3 "无定义" ;
VAL_ 2417491984 RPDU1_B2_SSPC_BitErr_12 1 "故障" 0 "正常" ;
VAL_ 2417491984 RPDU1_B2_SSPC_OnOffSta_12 1 "接通" 0 "断开" ;
VAL_ 2417491984 RPDU1_B2_SSPC_DianHuErr_12 1 "有故障" 0 "无故障" ;
VAL_ 2417491984 RPDU1_B2_SSPC_TripSta_11 1 "短路跳闸" 2 "过流跳闸" 0 "正常" 3 "无定义" ;
VAL_ 2417491984 RPDU1_B2_SSPC_BitErr_11 1 "故障" 0 "正常" ;
VAL_ 2417491984 RPDU1_B2_SSPC_OnOffSta_11 1 "接通" 0 "断开" ;
VAL_ 2417491984 RPDU1_B2_SSPC_DianHuErr_11 1 "有故障" 0 "无故障" ;
VAL_ 2417491984 RPDU1_B2_SSPC_TripSta_10 1 "短路跳闸" 2 "过流跳闸" 0 "正常" 3 "无定义" ;
VAL_ 2417491984 RPDU1_B2_SSPC_BitErr_10 1 "故障" 0 "正常" ;
VAL_ 2417491984 RPDU1_B2_SSPC_OnOffSta_10 1 "接通" 0 "断开" ;
VAL_ 2417491984 RPDU1_B2_SSPC_DianHuErr_10 1 "有故障" 0 "无故障" ;
VAL_ 2417491984 RPDU1_B2_SSPC_TripSta_09 1 "短路跳闸" 2 "过流跳闸" 0 "正常" 3 "无定义" ;
VAL_ 2417491984 RPDU1_B2_SSPC_BitErr_09 1 "故障" 0 "正常" ;
VAL_ 2417491984 RPDU1_B2_SSPC_OnOffSta_09 1 "接通" 0 "断开" ;
VAL_ 2417491984 RPDU1_B2_SSPC_DianHuErr_09 1 "有故障" 0 "无故障" ;
VAL_ 2417426448 RPDU1_B2_SSPC_TripSta_08 1 "短路跳闸" 2 "过流跳闸" 0 "正常" 3 "无定义" ;
VAL_ 2417426448 RPDU1_B2_SSPC_BitErr_08 1 "故障" 0 "正常" ;
VAL_ 2417426448 RPDU1_B2_SSPC_OnOffSta_08 1 "接通" 0 "断开" ;
VAL_ 2417426448 RPDU1_B2_SSPC_DianHuErr_08 1 "有故障" 0 "无故障" ;
VAL_ 2417426448 RPDU1_B2_SSPC_TripSta_07 1 "短路跳闸" 2 "过流跳闸" 0 "正常" 3 "无定义" ;
VAL_ 2417426448 RPDU1_B2_SSPC_BitErr_07 1 "故障" 0 "正常" ;
VAL_ 2417426448 RPDU1_B2_SSPC_OnOffSta_07 1 "接通" 0 "断开" ;
VAL_ 2417426448 RPDU1_B2_SSPC_DianHuErr_07 1 "有故障" 0 "无故障" ;
VAL_ 2417426448 RPDU1_B2_SSPC_TripSta_06 1 "短路跳闸" 2 "过流跳闸" 0 "正常" 3 "无定义" ;
VAL_ 2417426448 RPDU1_B2_SSPC_BitErr_06 1 "故障" 0 "正常" ;
VAL_ 2417426448 RPDU1_B2_SSPC_OnOffSta_06 1 "接通" 0 "断开" ;
VAL_ 2417426448 RPDU1_B2_SSPC_DianHuErr_06 1 "有故障" 0 "无故障" ;
VAL_ 2417426448 RPDU1_B2_SSPC_TripSta_05 1 "短路跳闸" 2 "过流跳闸" 0 "正常" 3 "无定义" ;
VAL_ 2417426448 RPDU1_B2_SSPC_BitErr_05 1 "故障" 0 "正常" ;
VAL_ 2417426448 RPDU1_B2_SSPC_OnOffSta_05 1 "接通" 0 "断开" ;
VAL_ 2417426448 RPDU1_B2_SSPC_DianHuErr_05 1 "有故障" 0 "无故障" ;
VAL_ 2417360912 RPDU1_B2_SSPC_TripSta_04 1 "短路跳闸" 2 "过流跳闸" 0 "正常" 3 "无定义" ;
VAL_ 2417360912 RPDU1_B2_SSPC_BitErr_04 1 "故障" 0 "正常" ;
VAL_ 2417360912 RPDU1_B2_SSPC_OnOffSta_04 1 "接通" 0 "断开" ;
VAL_ 2417360912 RPDU1_B2_SSPC_DianHuErr_04 1 "有故障" 0 "无故障" ;
VAL_ 2417360912 RPDU1_B2_SSPC_TripSta_03 1 "短路跳闸" 2 "过流跳闸" 0 "正常" 3 "无定义" ;
VAL_ 2417360912 RPDU1_B2_SSPC_BitErr_03 1 "故障" 0 "正常" ;
VAL_ 2417360912 RPDU1_B2_SSPC_OnOffSta_03 1 "接通" 0 "断开" ;
VAL_ 2417360912 RPDU1_B2_SSPC_DianHuErr_03 1 "有故障" 0 "无故障" ;
VAL_ 2417360912 RPDU1_B2_SSPC_TripSta_02 1 "短路跳闸" 2 "过流跳闸" 0 "正常" 3 "无定义" ;
VAL_ 2417360912 RPDU1_B2_SSPC_BitErr_02 1 "故障" 0 "正常" ;
VAL_ 2417360912 RPDU1_B2_SSPC_OnOffSta_02 1 "接通" 0 "断开" ;
VAL_ 2417360912 RPDU1_B2_SSPC_DianHuErr_02 1 "有故障" 0 "无故障" ;
VAL_ 2417360912 RPDU1_B2_SSPC_TripSta_01 1 "短路跳闸" 2 "过流跳闸" 0 "正常" 3 "无定义" ;
VAL_ 2417360912 RPDU1_B2_SSPC_BitErr_01 1 "故障" 0 "正常" ;
VAL_ 2417360912 RPDU1_B2_SSPC_OnOffSta_01 1 "接通" 0 "断开" ;
VAL_ 2417360912 RPDU1_B2_SSPC_DianHuErr_01 1 "有故障" 0 "无故障" ;
VAL_ 2417295376 RPDU1_B1_SSPC_TripSta_18 1 "短路跳闸" 2 "过流跳闸" 0 "正常" 3 "无定义" ;
VAL_ 2417295376 RPDU1_B1_SSPC_BitErr_18 1 "故障" 0 "正常" ;
VAL_ 2417295376 RPDU1_B1_SSPC_OnOffSta_18 1 "接通" 0 "断开" ;
VAL_ 2417295376 RPDU1_B1_SSPC_DianHuErr_18 1 "有故障" 0 "无故障" ;
VAL_ 2417295376 RPDU1_B1_SSPC_TripSta_17 1 "短路跳闸" 2 "过流跳闸" 0 "正常" 3 "无定义" ;
VAL_ 2417295376 RPDU1_B1_SSPC_BitErr_17 1 "故障" 0 "正常" ;
VAL_ 2417295376 RPDU1_B1_SSPC_OnOffSta_17 1 "接通" 0 "断开" ;
VAL_ 2417295376 RPDU1_B1_SSPC_DianHuErr_17 1 "有故障" 0 "无故障" ;
VAL_ 2417229840 RPDU1_B1_SSPC_TripSta_16 1 "短路跳闸" 2 "过流跳闸" 0 "正常" 3 "无定义" ;
VAL_ 2417229840 RPDU1_B1_SSPC_BitErr_16 1 "故障" 0 "正常" ;
VAL_ 2417229840 RPDU1_B1_SSPC_OnOffSta_16 1 "接通" 0 "断开" ;
VAL_ 2417229840 RPDU1_B1_SSPC_DianHuErr_16 1 "有故障" 0 "无故障" ;
VAL_ 2417229840 RPDU1_B1_SSPC_TripSta_15 1 "短路跳闸" 2 "过流跳闸" 0 "正常" 3 "无定义" ;
VAL_ 2417229840 RPDU1_B1_SSPC_BitErr_15 1 "故障" 0 "正常" ;
VAL_ 2417229840 RPDU1_B1_SSPC_OnOffSta_15 1 "接通" 0 "断开" ;
VAL_ 2417229840 RPDU1_B1_SSPC_DianHuErr_15 1 "有故障" 0 "无故障" ;
VAL_ 2417229840 RPDU1_B1_SSPC_TripSta_14 1 "短路跳闸" 2 "过流跳闸" 0 "正常" 3 "无定义" ;
VAL_ 2417229840 RPDU1_B1_SSPC_BitErr_14 1 "故障" 0 "正常" ;
VAL_ 2417229840 RPDU1_B1_SSPC_OnOffSta_14 1 "接通" 0 "断开" ;
VAL_ 2417229840 RPDU1_B1_SSPC_DianHuErr_14 1 "有故障" 0 "无故障" ;
VAL_ 2417229840 RPDU1_B1_SSPC_TripSta_13 1 "短路跳闸" 2 "过流跳闸" 0 "正常" 3 "无定义" ;
VAL_ 2417229840 RPDU1_B1_SSPC_BitErr_13 1 "故障" 0 "正常" ;
VAL_ 2417229840 RPDU1_B1_SSPC_OnOffSta_13 1 "接通" 0 "断开" ;
VAL_ 2417229840 RPDU1_B1_SSPC_DianHuErr_13 1 "有故障" 0 "无故障" ;
VAL_ 2417164304 RPDU1_B1_SSPC_TripSta_12 1 "短路跳闸" 2 "过流跳闸" 0 "正常" 3 "无定义" ;
VAL_ 2417164304 RPDU1_B1_SSPC_BitErr_12 1 "故障" 0 "正常" ;
VAL_ 2417164304 RPDU1_B1_SSPC_OnOffSta_12 1 "接通" 0 "断开" ;
VAL_ 2417164304 RPDU1_B1_SSPC_DianHuErr_12 1 "有故障" 0 "无故障" ;
VAL_ 2417164304 RPDU1_B1_SSPC_TripSta_11 1 "短路跳闸" 2 "过流跳闸" 0 "正常" 3 "无定义" ;
VAL_ 2417164304 RPDU1_B1_SSPC_BitErr_11 1 "故障" 0 "正常" ;
VAL_ 2417164304 RPDU1_B1_SSPC_OnOffSta_11 1 "接通" 0 "断开" ;
VAL_ 2417164304 RPDU1_B1_SSPC_DianHuErr_11 1 "有故障" 0 "无故障" ;
VAL_ 2417164304 RPDU1_B1_SSPC_TripSta_10 1 "短路跳闸" 2 "过流跳闸" 0 "正常" 3 "无定义" ;
VAL_ 2417164304 RPDU1_B1_SSPC_BitErr_10 1 "故障" 0 "正常" ;
VAL_ 2417164304 RPDU1_B1_SSPC_OnOffSta_10 1 "接通" 0 "断开" ;
VAL_ 2417164304 RPDU1_B1_SSPC_DianHuErr_10 1 "有故障" 0 "无故障" ;
VAL_ 2417164304 RPDU1_B1_SSPC_TripSta_09 1 "短路跳闸" 2 "过流跳闸" 0 "正常" 3 "无定义" ;
VAL_ 2417164304 RPDU1_B1_SSPC_BitErr_09 1 "故障" 0 "正常" ;
VAL_ 2417164304 RPDU1_B1_SSPC_OnOffSta_09 1 "接通" 0 "断开" ;
VAL_ 2417164304 RPDU1_B1_SSPC_DianHuErr_09 1 "有故障" 0 "无故障" ;
VAL_ 2417098768 RPDU1_B1_SSPC_TripSta_08 1 "短路跳闸" 2 "过流跳闸" 0 "正常" 3 "无定义" ;
VAL_ 2417098768 RPDU1_B1_SSPC_BitErr_08 1 "故障" 0 "正常" ;
VAL_ 2417098768 RPDU1_B1_SSPC_OnOffSta_08 1 "接通" 0 "断开" ;
VAL_ 2417098768 RPDU1_B1_SSPC_DianHuErr_08 1 "有故障" 0 "无故障" ;
VAL_ 2417098768 RPDU1_B1_SSPC_TripSta_07 1 "短路跳闸" 2 "过流跳闸" 0 "正常" 3 "无定义" ;
VAL_ 2417098768 RPDU1_B1_SSPC_BitErr_07 1 "故障" 0 "正常" ;
VAL_ 2417098768 RPDU1_B1_SSPC_OnOffSta_07 1 "接通" 0 "断开" ;
VAL_ 2417098768 RPDU1_B1_SSPC_DianHuErr_07 1 "有故障" 0 "无故障" ;
VAL_ 2417098768 RPDU1_B1_SSPC_TripSta_06 1 "短路跳闸" 2 "过流跳闸" 0 "正常" 3 "无定义" ;
VAL_ 2417098768 RPDU1_B1_SSPC_BitErr_06 1 "故障" 0 "正常" ;
VAL_ 2417098768 RPDU1_B1_SSPC_OnOffSta_06 1 "接通" 0 "断开" ;
VAL_ 2417098768 RPDU1_B1_SSPC_DianHuErr_06 1 "有故障" 0 "无故障" ;
VAL_ 2417098768 RPDU1_B1_SSPC_TripSta_05 1 "短路跳闸" 2 "过流跳闸" 0 "正常" 3 "无定义" ;
VAL_ 2417098768 RPDU1_B1_SSPC_BitErr_05 1 "故障" 0 "正常" ;
VAL_ 2417098768 RPDU1_B1_SSPC_OnOffSta_05 1 "接通" 0 "断开" ;
VAL_ 2417098768 RPDU1_B1_SSPC_DianHuErr_05 1 "有故障" 0 "无故障" ;
VAL_ 2417033232 RPDU1_B1_SSPC_TripSta_04 1 "短路跳闸" 2 "过流跳闸" 0 "正常" 3 "无定义" ;
VAL_ 2417033232 RPDU1_B1_SSPC_BitErr_04 1 "故障" 0 "正常" ;
VAL_ 2417033232 RPDU1_B1_SSPC_OnOffSta_04 1 "接通" 0 "断开" ;
VAL_ 2417033232 RPDU1_B1_SSPC_DianHuErr_04 1 "有故障" 0 "无故障" ;
VAL_ 2417033232 RPDU1_B1_SSPC_TripSta_03 1 "短路跳闸" 2 "过流跳闸" 0 "正常" 3 "无定义" ;
VAL_ 2417033232 RPDU1_B1_SSPC_BitErr_03 1 "故障" 0 "正常" ;
VAL_ 2417033232 RPDU1_B1_SSPC_OnOffSta_03 1 "接通" 0 "断开" ;
VAL_ 2417033232 RPDU1_B1_SSPC_DianHuErr_03 1 "有故障" 0 "无故障" ;
VAL_ 2417033232 RPDU1_B1_SSPC_TripSta_02 1 "短路跳闸" 2 "过流跳闸" 0 "正常" 3 "无定义" ;
VAL_ 2417033232 RPDU1_B1_SSPC_BitErr_02 1 "故障" 0 "正常" ;
VAL_ 2417033232 RPDU1_B1_SSPC_OnOffSta_02 1 "接通" 0 "断开" ;
VAL_ 2417033232 RPDU1_B1_SSPC_DianHuErr_02 1 "有故障" 0 "无故障" ;
VAL_ 2417033232 RPDU1_B1_SSPC_TripSta_01 1 "短路跳闸" 2 "过流跳闸" 0 "正常" 3 "无定义" ;
VAL_ 2417033232 RPDU1_B1_SSPC_BitErr_01 1 "故障" 0 "正常" ;
VAL_ 2417033232 RPDU1_B1_SSPC_OnOffSta_01 1 "接通" 0 "断开" ;
VAL_ 2417033232 RPDU1_B1_SSPC_DianHuErr_01 1 "有故障" 0 "无故障" ;
VAL_ 2416967696 L_TouChuan_DCDC_DDCSta 0 "断开" 1 "接通" ;
VAL_ 2416967696 L_TouChuan_DCDC_DDCCtrl 0 "断开" 1 "接通" ;
VAL_ 2416967696 L_TouChuan_DCDC_FanWarn 0 "正常" 1 "故障" ;
VAL_ 2416967696 L_TouChuan_DCDC_ConnStaErr 0 "正常" 1 "故障" ;
VAL_ 2416967696 L_TouChuan_DCDC_HardOutOverErr 0 "正常" 1 "故障" ;
VAL_ 2416967696 L_TouChuan_DCDC_TOverErr 0 "正常" 1 "故障" ;
VAL_ 2416967696 L_TouChuan_DCDC_TOverWarn 0 "正常" 1 "故障" ;
VAL_ 2416967696 L_TouChuan_DCDC_OutILimitErr 0 "正常" 1 "故障" ;
VAL_ 2416967696 L_TouChuan_DCDC_OutIOverErr 0 "正常" 1 "故障" ;
VAL_ 2416967696 L_TouChuan_DCDC_OutPowOverErr 0 "正常" 1 "故障" ;
VAL_ 2416967696 L_TouChuan_DCDC_OutPowLowErr 0 "正常" 1 "故障" ;
VAL_ 2416967696 L_TouChuan_DCDC_OutPowLowWarn 0 "正常" 1 "故障" ;
VAL_ 2416967696 L_TouChuan_DCDC_InPowLowErr 0 "正常" 1 "故障" ;
VAL_ 2416508944 L_DuanLuQi_Sta_49 0 "接通" 1 "断开" ;
VAL_ 2416508944 L_DuanLuQi_Sta_48 0 "接通" 1 "断开" ;
VAL_ 2416508944 L_DuanLuQi_Sta_47 0 "接通" 1 "断开" ;
VAL_ 2416508944 L_DuanLuQi_Sta_46 0 "接通" 1 "断开" ;
VAL_ 2416508944 L_DuanLuQi_Sta_45 0 "接通" 1 "断开" ;
VAL_ 2416508944 L_DuanLuQi_Sta_44 0 "接通" 1 "断开" ;
VAL_ 2416508944 L_DuanLuQi_Sta_43 0 "接通" 1 "断开" ;
VAL_ 2416508944 L_DuanLuQi_Sta_42 0 "接通" 1 "断开" ;
VAL_ 2416508944 L_DuanLuQi_Sta_41 0 "接通" 1 "断开" ;
VAL_ 2416508944 L_DuanLuQi_Sta_40 0 "接通" 1 "断开" ;
VAL_ 2416508944 L_DuanLuQi_Sta_39 0 "接通" 1 "断开" ;
VAL_ 2416508944 L_DuanLuQi_Sta_38 0 "接通" 1 "断开" ;
VAL_ 2416508944 L_DuanLuQi_Sta_37 0 "接通" 1 "断开" ;
VAL_ 2416508944 L_DuanLuQi_Sta_36 0 "接通" 1 "断开" ;
VAL_ 2416508944 L_DuanLuQi_Sta_35 0 "接通" 1 "断开" ;
VAL_ 2416508944 L_DuanLuQi_Sta_34 0 "接通" 1 "断开" ;
VAL_ 2416508944 L_DuanLuQi_Sta_33 0 "接通" 1 "断开" ;
VAL_ 2416508944 L_DuanLuQi_Sta_32 0 "接通" 1 "断开" ;
VAL_ 2416508944 L_DuanLuQi_Sta_31 0 "接通" 1 "断开" ;
VAL_ 2416508944 L_DuanLuQi_Sta_30 0 "接通" 1 "断开" ;
VAL_ 2416508944 L_DuanLuQi_Sta_29 0 "接通" 1 "断开" ;
VAL_ 2416508944 L_DuanLuQi_Sta_28 0 "接通" 1 "断开" ;
VAL_ 2416508944 L_DuanLuQi_Sta_27 0 "接通" 1 "断开" ;
VAL_ 2416508944 L_DuanLuQi_Sta_26 0 "接通" 1 "断开" ;
VAL_ 2416508944 L_DuanLuQi_Sta_25 0 "接通" 1 "断开" ;
VAL_ 2416508944 L_DuanLuQi_Sta_24 0 "接通" 1 "断开" ;
VAL_ 2416508944 L_DuanLuQi_Sta_23 0 "接通" 1 "断开" ;
VAL_ 2416508944 L_DuanLuQi_Sta_22 0 "接通" 1 "断开" ;
VAL_ 2416508944 L_DuanLuQi_Sta_21 0 "接通" 1 "断开" ;
VAL_ 2416508944 L_DuanLuQi_Sta_20 0 "接通" 1 "断开" ;
VAL_ 2416508944 L_DuanLuQi_Sta_19 0 "接通" 1 "断开" ;
VAL_ 2416508944 L_DuanLuQi_Sta_18 0 "接通" 1 "断开" ;
VAL_ 2416508944 L_DuanLuQi_Sta_17 0 "接通" 1 "断开" ;
VAL_ 2416508944 L_DuanLuQi_Sta_16 0 "接通" 1 "断开" ;
VAL_ 2416508944 L_DuanLuQi_Sta_15 0 "接通" 1 "断开" ;
VAL_ 2416508944 L_DuanLuQi_Sta_14 0 "接通" 1 "断开" ;
VAL_ 2416508944 L_DuanLuQi_Sta_13 0 "接通" 1 "断开" ;
VAL_ 2416508944 L_DuanLuQi_Sta_12 0 "接通" 1 "断开" ;
VAL_ 2416508944 L_DuanLuQi_Sta_11 0 "接通" 1 "断开" ;
VAL_ 2416508944 L_DuanLuQi_Sta_10 0 "接通" 1 "断开" ;
VAL_ 2416508944 L_DuanLuQi_Sta_09 0 "接通" 1 "断开" ;
VAL_ 2416508944 L_DuanLuQi_Sta_08 0 "接通" 1 "断开" ;
VAL_ 2416508944 L_DuanLuQi_Sta_07 0 "接通" 1 "断开" ;
VAL_ 2416508944 L_DuanLuQi_Sta_06 0 "接通" 1 "断开" ;
VAL_ 2416508944 L_DuanLuQi_Sta_05 0 "接通" 1 "断开" ;
VAL_ 2416508944 L_DuanLuQi_Sta_04 0 "接通" 1 "断开" ;
VAL_ 2416508944 L_DuanLuQi_Sta_03 0 "接通" 1 "断开" ;
VAL_ 2416508944 L_DuanLuQi_Sta_02 0 "接通" 1 "断开" ;
VAL_ 2416508944 L_DuanLuQi_Sta_01 0 "接通" 1 "断开" ;
VAL_ 2416443408 L_LE28IOver 0 "不过流" 1 "过流" ;
VAL_ 2416443408 L_LR28IOver 0 "不过流" 1 "过流" ;
VAL_ 2416443408 L_HLT281IOver 0 "不过流" 1 "过流" ;
VAL_ 2416443408 L_HLT282IOver 0 "不过流" 1 "过流" ;
VAL_ 2416443408 L_LE270IOver 0 "不过流" 1 "过流" ;
VAL_ 2416443408 L_LR270IOver 0 "不过流" 1 "过流" ;
VAL_ 2416443408 L_HLT270IOver 0 "不过流" 1 "过流" ;
VAL_ 2416443408 L_HOTBBUSta 0 "正常" 1 "欠压" 2 "过压" 3 "无定义" ;
VAL_ 2416443408 L_HLT281USta 0 "正常" 1 "欠压" 2 "过压" 3 "无定义" ;
VAL_ 2416443408 L_HLT282USta 0 "正常" 1 "欠压" 2 "过压" 3 "无定义" ;
VAL_ 2416443408 L_DCDC28OutUSta 0 "正常" 1 "欠压" 2 "过压" 3 "无定义" ;
VAL_ 2416443408 L_DCDC270InUSta 0 "正常" 1 "欠压" 2 "过压" 3 "无定义" ;
VAL_ 2416443408 L_HLT270USta 0 "正常" 1 "欠压" 2 "过压" 3 "无定义" ;
VAL_ 2416443408 L_Batter270USta 0 "正常" 1 "欠压" 2 "过压" 3 "无定义" ;
VAL_ 2416443408 L_Heart_BIT 0 "正常" 1 "故障" ;
VAL_ 2416443408 L_ZBUART_BIT 0 "正常" 1 "故障" ;
VAL_ 2416443408 L_ADCIN_BIT 0 "正常" 1 "故障" ;
VAL_ 2416443408 L_GpioIN_BIT 0 "正常" 1 "故障" ;
VAL_ 2416443408 L_Flash_BIT 0 "正常" 1 "故障" ;
VAL_ 2416443408 L_UART_BIT 0 "正常" 1 "故障" ;
VAL_ 2416443408 L_IntCAN2_BIT 0 "正常" 1 "故障" ;
VAL_ 2416443408 L_IntCAN1_BIT 0 "正常" 1 "故障" ;
VAL_ 2416443408 L_ExtCAN_BIT 0 "正常" 1 "故障" ;
VAL_ 2416443408 L_CPU_BIT 0 "正常" 1 "故障" ;
VAL_ 2416443408 L_Pow_BIT 0 "正常" 1 "故障" ;
VAL_ 2416377872 LTSSR_STA 0 "接通正常" 1 "接通故障" 2 "无效" 3 "无效" ;
VAL_ 2416377872 EBC_STA_L 0 "接通正常" 1 "接通故障" 3 "断开正常" 2 "断开故障" ;
VAL_ 2416377872 LTR_STA 0 "接通正常" 1 "接通故障" 3 "断开正常" 2 "断开故障" ;
VAL_ 2416377872 LETC1_STA 0 "接通正常" 1 "接通故障" 3 "断开正常" 2 "断开故障" ;
VAL_ 2416377872 BTC2_STA 0 "接通正常" 1 "接通故障" 3 "断开正常" 2 "断开故障" ;
VAL_ 2416377872 LDC2_STA 0 "接通正常" 1 "接通故障" 3 "断开正常" 2 "断开故障" ;
VAL_ 2416377872 LETR_STA 0 "接通正常" 1 "接通故障" 3 "断开正常" 2 "断开故障" ;
VAL_ 2416377872 LBC_STA 0 "接通正常" 1 "接通故障" 3 "断开正常" 2 "断开故障" ;
